VERSION ""

NS_ :

BS_:

BU_: WCM4 WCM3 WCM2 WCM VPM VLM VKM VICM VECM VDM VCU_RTOS_ETH VCU_ENTRY_ETH VCU_AGVM_ETH VCU UVM UPM TIM TEST_TOOL_1 TCP_ETH TCP TCM TCCM SRR_SRR_ETH SRR_SRR SRR_SLR_ETH SRR_SLR SRR_RR SRR_RF_ETH SRR_RF SRR_LR_CR SRR_LF_ETH SRR_LF SIB SDM SCL SBZA_R SBZA_L SBM SAM_RR SAM_RF SAM_LR SAM_LF SAM_BH SADS RadioLow_ETH RadioLow RSI_RTOS_ETH RSI RDCM PTM PLCM PFCM PDR_ETH PDR PCM PA ODS2 ODS NVM MTCM_R MTCM_L MSM_RR MSM_P MSM_LR MSM_D MSB2 MSB1 MRCM_R MRCM_L MFC LRR_RR_ETH LRR_LR_ETH LRR_CF_ETH LRR LRL_CF_ETH LIB_48V LIB1 IPC_INT IPC_GP IPC ICS_Info ICCM HVAC_FP_R HVAC_FP_F HUD_CAN HDLM FPI_RTOS_ETH FPI FOPM FCM_LC FCM EPSb EPS_1 EPSRAb EPSRAa EPS EOCM_HC_Superset EOCM_HCP2 EOCM ELM ECP_X1 ECP_S2 ECP_S ECP_MC ECP_H3 ECP_H2 ECP_H1 ECP_E ECM EBCM DMS DEFC DCM CSM_ETH CSM_AV CSM CGM_OTA_ETH CGM BSM_MH BSM_HEV BSM BCM ARS ARB APA AOS AMP ALC AHS AHL_AFL ADIMb ADIMa ACP2_MCU

BO_ 191 SRRSRRODP_BrstGrp_Prtctd_Conse02: 64 SRR_SRR
 SG_ SRRSRRODPB4P_POTk5IDAuth : 0|7@0+ (1,0) [0|127] "" EOCM_HCP2,EOCM_HC_Superset
 SG_ SRRSRRODPB4P_POTk5DynPrpAuth : 3|3@0+ (1,0) [0|4] "" EOCM_HCP2,EOCM_HC_Superset
 SG_ SRRSRRODPB4P_POTk5CnfdStsAuth : 5|2@0+ (1,0) [0|3] "" EOCM_HCP2,EOCM_HC_Superset
 SG_ SRRSRRODPB4P_BrstID : 7|2@0+ (1,0) [0|3] "" EOCM_HCP2,EOCM_HC_Superset
 SG_ SRRSRRODPB4P_POTk5InPthPotAuth : 9|6@0+ (2,0) [0|126] "%" EOCM_HCP2,EOCM_HC_Superset
 SG_ SRRSRRODPB4P_POTk5PoILAAuth : 17|9@0- (0.125,0) [-32|31.875] "m/s^2" EOCM_HCP2,EOCM_HC_Superset
 SG_ SRRSRRODPB4P_POTk5MStsAuth : 19|2@0+ (1,0) [0|3] "" EOCM_HCP2,EOCM_HC_Superset
 SG_ SRRSRRODPB4P_POTk5PoILgAAuth : 24|9@0- (0.125,0) [-32|31.875] "m/s^2" EOCM_HCP2,EOCM_HC_Superset
 SG_ SRRSRRODPB4P_POTk5PoILgPsAuth : 47|11@0- (0.125,0) [-128|127.875] "m" EOCM_HCP2,EOCM_HC_Superset
 SG_ SRRSRRODPB4P_POTk5PoILgVAuth : 52|10@0- (0.125,0) [-64|63.875] "m/s" EOCM_HCP2,EOCM_HC_Superset
 SG_ SRRSRRODPB4P_POTk5PoILPsAuth : 58|10@0- (0.125,0) [-64|63.875] "m" EOCM_HCP2,EOCM_HC_Superset
 SG_ SRRSRRODPB4P_POTk5PoILVAuth : 64|9@0- (0.125,0) [-32|31.875] "m/s" EOCM_HCP2,EOCM_HC_Superset
 SG_ SRRSRRODPB4P_VOTk10CICOPotAuth : 83|6@0+ (2,0) [0|126] "%" EOCM_HCP2,EOCM_HC_Superset
 SG_ SRRSRRODPB4P_POTk5TypCnfdAuth : 85|2@0+ (1,0) [0|3] "" EOCM_HCP2,EOCM_HC_Superset
 SG_ SRRSRRODPB4P_POTk5TypAuth : 87|2@0+ (1,0) [0|2] "" EOCM_HCP2,EOCM_HC_Superset
 SG_ SRRSRRODPB4P_VOTk10DynPrpStAuth : 88|1@0+ (1,0) [0|1] "" EOCM_HCP2,EOCM_HC_Superset
 SG_ SRRSRRODPB4P_VOTk10DynPrpAuth : 91|3@0+ (1,0) [0|4] "" EOCM_HCP2,EOCM_HC_Superset
 SG_ SRRSRRODPB4P_VOTk10CnfdStsAuth : 93|2@0+ (1,0) [0|3] "" EOCM_HCP2,EOCM_HC_Superset
 SG_ SRRSRRODPB4P_VOTk10MStsAuth : 96|2@0+ (1,0) [0|3] "" EOCM_HCP2,EOCM_HC_Superset
 SG_ SRRSRRODPB4P_VOTk10IDAuth : 103|7@0+ (1,0) [0|127] "" EOCM_HCP2,EOCM_HC_Superset
 SG_ SRRSRRODPB4P_VOTk10PoILAAuth : 110|9@0- (0.125,0) [-32|31.875] "m/s^2" EOCM_HCP2,EOCM_HC_Superset
 SG_ SRRSRRODPB4P_VOTk10PoILgAAuth : 117|9@0- (0.125,0) [-32|31.875] "m/s^2" EOCM_HCP2,EOCM_HC_Superset
 SG_ SRRSRRODPB4P_VOTk10PoILgPsAuth : 124|11@0- (0.125,0) [-128|127.875] "m" EOCM_HCP2,EOCM_HC_Superset
 SG_ SRRSRRODPB4P_VOTk10PoILgPsCAuth : 129|16@0+ (0.01,0) [0|655.35] "m^2" EOCM_HCP2,EOCM_HC_Superset
 SG_ SRRSRRODPB4P_VOTk10PoILgthAuth : 145|8@0+ (0.125,0) [0|31.875] "m" EOCM_HCP2,EOCM_HC_Superset
 SG_ SRRSRRODPB4P_VOTk10PoILgVAuth : 153|11@0- (0.125,0) [-128|127.875] "m/s" EOCM_HCP2,EOCM_HC_Superset
 SG_ SRRSRRODPB4P_VOTk10PoILgVCAuth : 174|10@0+ (0.125,0) [0|127.875] "(m/s)^2" EOCM_HCP2,EOCM_HC_Superset
 SG_ SRRSRRODPB4P_VOTk10PoILPsAuth : 180|10@0- (0.125,0) [-64|63.875] "m" EOCM_HCP2,EOCM_HC_Superset
 SG_ SRRSRRODPB4P_VOTk10PoILPsCAuth : 186|14@0+ (0.01,0) [0|163.83] "m^2" EOCM_HCP2,EOCM_HC_Superset
 SG_ SRRSRRODPB4P_VOTk10PoILVAuth : 204|9@0- (0.125,0) [-32|31.875] "m/s" EOCM_HCP2,EOCM_HC_Superset
 SG_ SRRSRRODPB4P_VOTk10PoILVCAuth : 211|10@0+ (0.125,0) [0|127.875] "(m/s)^2" EOCM_HCP2,EOCM_HC_Superset
 SG_ SRRSRRODPB4P_VOTk10TypCnfdAuth : 217|2@0+ (1,0) [0|3] "" EOCM_HCP2,EOCM_HC_Superset
 SG_ SRRSRRODPB4P_VOTk8CnfdStsAuth : 225|2@0+ (1,0) [0|3] "" EOCM_HCP2,EOCM_HC_Superset
 SG_ SRRSRRODPB4P_VOTk8CICOPotAuth : 231|6@0+ (2,0) [0|126] "%" EOCM_HCP2,EOCM_HC_Superset
 SG_ SRRSRRODPB4P_VOTk8IDAuth : 235|7@0+ (1,0) [0|127] "" EOCM_HCP2,EOCM_HC_Superset
 SG_ SRRSRRODPB4P_VOTk8DynPrpStsAuth : 236|1@0+ (1,0) [0|1] "" EOCM_HCP2,EOCM_HC_Superset
 SG_ SRRSRRODPB4P_VOTk8DynPrpAuth : 239|3@0+ (1,0) [0|4] "" EOCM_HCP2,EOCM_HC_Superset
 SG_ SRRSRRODPB4P_VOTk8PoILAAuth : 242|9@0- (0.125,0) [-32|31.875] "m/s^2" EOCM_HCP2,EOCM_HC_Superset
 SG_ SRRSRRODPB4P_VOTk8MStsAuth : 244|2@0+ (1,0) [0|3] "" EOCM_HCP2,EOCM_HC_Superset
 SG_ SRRSRRODPB4P_VOTk8PoILgAAuth : 249|9@0- (0.125,0) [-32|31.875] "m/s^2" EOCM_HCP2,EOCM_HC_Superset
 SG_ SRRSRRODPB4P_VOTk8PoILgPsAuth : 256|11@0- (0.125,0) [-128|127.875] "m" EOCM_HCP2,EOCM_HC_Superset
 SG_ SRRSRRODPB4P_VOTk8PoILgPsCAuth : 277|16@0+ (0.01,0) [0|655.35] "m^2" EOCM_HCP2,EOCM_HC_Superset
 SG_ SRRSRRODPB4P_VOTk8PoILgVAuth : 293|11@0- (0.125,0) [-128|127.875] "m/s" EOCM_HCP2,EOCM_HC_Superset
 SG_ SRRSRRODPB4P_VOTk8PoILgVCAuth : 298|10@0+ (0.125,0) [0|127.875] "(m/s)^2" EOCM_HCP2,EOCM_HC_Superset
 SG_ SRRSRRODPB4P_VOTk8PoILPsAuth : 304|10@0- (0.125,0) [-64|63.875] "m" EOCM_HCP2,EOCM_HC_Superset
 SG_ SRRSRRODPB4P_VOTk8PoILPsCAuth : 326|14@0+ (0.01,0) [0|163.83] "m^2" EOCM_HCP2,EOCM_HC_Superset
 SG_ SRRSRRODPB4P_VOTk8PoILVAuth : 328|9@0- (0.125,0) [-32|31.875] "m/s" EOCM_HCP2,EOCM_HC_Superset
 SG_ SRRSRRODPB4P_VOTk8PoILVCAuth : 351|10@0+ (0.125,0) [0|127.875] "(m/s)^2" EOCM_HCP2,EOCM_HC_Superset
 SG_ SRRSRRODPB4P_VOTk9CICOPotAuth : 355|6@0+ (2,0) [0|126] "%" EOCM_HCP2,EOCM_HC_Superset
 SG_ SRRSRRODPB4P_VOTk8TypCnfdAuth : 357|2@0+ (1,0) [0|3] "" EOCM_HCP2,EOCM_HC_Superset
 SG_ SRRSRRODPB4P_VOTk9DynPrpStsAuth : 360|1@0+ (1,0) [0|1] "" EOCM_HCP2,EOCM_HC_Superset
 SG_ SRRSRRODPB4P_VOTk9DynPrpAuth : 363|3@0+ (1,0) [0|4] "" EOCM_HCP2,EOCM_HC_Superset
 SG_ SRRSRRODPB4P_VOTk9CnfdStsAuth : 365|2@0+ (1,0) [0|3] "" EOCM_HCP2,EOCM_HC_Superset
 SG_ SRRSRRODPB4P_VOTk9MStsAuth : 368|2@0+ (1,0) [0|3] "" EOCM_HCP2,EOCM_HC_Superset
 SG_ SRRSRRODPB4P_VOTk9IDAuth : 375|7@0+ (1,0) [0|127] "" EOCM_HCP2,EOCM_HC_Superset
 SG_ SRRSRRODPB4P_VOTk9PoILAAuth : 382|9@0- (0.125,0) [-32|31.875] "m/s^2" EOCM_HCP2,EOCM_HC_Superset
 SG_ SRRSRRODPB4P_VOTk9PoILgAAuth : 389|9@0- (0.125,0) [-32|31.875] "m/s^2" EOCM_HCP2,EOCM_HC_Superset
 SG_ SRRSRRODPB4P_VOTk9PoILgPsAuth : 396|11@0- (0.125,0) [-128|127.875] "m" EOCM_HCP2,EOCM_HC_Superset
 SG_ SRRSRRODPB4P_VOTk9PoILgPsCAuth : 401|16@0+ (0.01,0) [0|655.35] "m^2" EOCM_HCP2,EOCM_HC_Superset
 SG_ SRRSRRODPB4P_VOTk9PoILgthAuth : 417|8@0+ (0.125,0) [0|31.875] "m" EOCM_HCP2,EOCM_HC_Superset
 SG_ SRRSRRODPB4P_VOTk9PoILgVAuth : 425|11@0- (0.125,0) [-128|127.875] "m/s" EOCM_HCP2,EOCM_HC_Superset
 SG_ SRRSRRODPB4P_VOTk9PoILgVCAuth : 446|10@0+ (0.125,0) [0|127.875] "(m/s)^2" EOCM_HCP2,EOCM_HC_Superset
 SG_ SRRSRRODPB4P_VOTk9PoILPsAuth : 452|10@0- (0.125,0) [-64|63.875] "m" EOCM_HCP2,EOCM_HC_Superset
 SG_ SRRSRRODPB4P_VOTk9PoILPsCAuth : 458|14@0+ (0.01,0) [0|163.83] "m^2" EOCM_HCP2,EOCM_HC_Superset
 SG_ SRRSRRODPB4P_VOTk9PoILVAuth : 476|9@0- (0.125,0) [-32|31.875] "m/s" EOCM_HCP2,EOCM_HC_Superset
 SG_ SRRSRRODPB4P_VOTk9PoILVCAuth : 483|10@0+ (0.125,0) [0|127.875] "(m/s)^2" EOCM_HCP2,EOCM_HC_Superset
 SG_ SRRSRRODPB4P_VOTk9TypCnfdAuth : 489|2@0+ (1,0) [0|3] "" EOCM_HCP2,EOCM_HC_Superset
 SG_ SRRSRRODPB4P_Filler : 503|16@0+ (1,0) [0|65535] "" EOCM_HCP2,EOCM_HC_Superset

BO_ 190 SRRSRRODP_BrstGrp_Prtctd_Conse03: 64 SRR_SRR
 SG_ SRRSRRODPB5P_IOTk10IDAuth : 1|7@0+ (1,0) [0|127] "" EOCM_HCP2,EOCM_HC_Superset
 SG_ SRRSRRODPB5P_IOTk10ElvtnAuth : 3|2@0+ (1,0) [0|3] "" EOCM_HCP2,EOCM_HC_Superset
 SG_ SRRSRRODPB5P_IOTk10CnfdStsAuth : 5|2@0+ (1,0) [0|3] "" EOCM_HCP2,EOCM_HC_Superset
 SG_ SRRSRRODPB5P_BrstID : 7|2@0+ (1,0) [0|3] "" EOCM_HCP2,EOCM_HC_Superset
 SG_ SRRSRRODPB5P_IOTk10PolLgPsAuth : 8|11@0- (0.125,0) [-128|127.875] "m" EOCM_HCP2,EOCM_HC_Superset
 SG_ SRRSRRODPB5P_IOTk10MStsAuth : 10|2@0+ (1,0) [0|3] "" EOCM_HCP2,EOCM_HC_Superset
 SG_ SRRSRRODPB5P_IOTk1CnfdStsAuth : 24|2@0+ (1,0) [0|3] "" EOCM_HCP2,EOCM_HC_Superset
 SG_ SRRSRRODPB5P_IOTk10TypCnfdAuth : 26|2@0+ (1,0) [0|3] "" EOCM_HCP2,EOCM_HC_Superset
 SG_ SRRSRRODPB5P_IOTk10TypAuth : 29|3@0+ (1,0) [0|5] "" EOCM_HCP2,EOCM_HC_Superset
 SG_ SRRSRRODPB5P_IOTk1IDAuth : 36|7@0+ (1,0) [0|127] "" EOCM_HCP2,EOCM_HC_Superset
 SG_ SRRSRRODPB5P_IOTk1ElvtnAuth : 38|2@0+ (1,0) [0|3] "" EOCM_HCP2,EOCM_HC_Superset
 SG_ SRRSRRODPB5P_IOTk1PoILgPsAuth : 43|11@0- (0.125,0) [-128|127.875] "m" EOCM_HCP2,EOCM_HC_Superset
 SG_ SRRSRRODPB5P_IOTk1MStsAuth : 45|2@0+ (1,0) [0|3] "" EOCM_HCP2,EOCM_HC_Superset
 SG_ SRRSRRODPB5P_IOTk1TypAuth : 48|3@0+ (1,0) [0|5] "" EOCM_HCP2,EOCM_HC_Superset
 SG_ SRRSRRODPB5P_IOTk2ElvtnAuth : 57|2@0+ (1,0) [0|3] "" EOCM_HCP2,EOCM_HC_Superset
 SG_ SRRSRRODPB5P_IOTk2CnfdStsAuth : 59|2@0+ (1,0) [0|3] "" EOCM_HCP2,EOCM_HC_Superset
 SG_ SRRSRRODPB5P_IOTk1TypCnfdAuth : 61|2@0+ (1,0) [0|3] "" EOCM_HCP2,EOCM_HC_Superset
 SG_ SRRSRRODPB5P_IOTk2MStsAuth : 64|2@0+ (1,0) [0|3] "" EOCM_HCP2,EOCM_HC_Superset
 SG_ SRRSRRODPB5P_IOTk2IDAuth : 71|7@0+ (1,0) [0|127] "" EOCM_HCP2,EOCM_HC_Superset
 SG_ SRRSRRODPB5P_IOTk2PolLgPsAuth : 78|11@0- (0.125,0) [-128|127.875] "m" EOCM_HCP2,EOCM_HC_Superset
 SG_ SRRSRRODPB5P_IOTk2TypCnfdAuth : 80|2@0+ (1,0) [0|3] "" EOCM_HCP2,EOCM_HC_Superset
 SG_ SRRSRRODPB5P_IOTk2TypAuth : 83|3@0+ (1,0) [0|5] "" EOCM_HCP2,EOCM_HC_Superset
 SG_ SRRSRRODPB5P_IOTk3IDAuth : 90|7@0+ (1,0) [0|127] "" EOCM_HCP2,EOCM_HC_Superset
 SG_ SRRSRRODPB5P_IOTk3ElvtnAuth : 92|2@0+ (1,0) [0|3] "" EOCM_HCP2,EOCM_HC_Superset
 SG_ SRRSRRODPB5P_IOTk3CnfdStsAuth : 94|2@0+ (1,0) [0|3] "" EOCM_HCP2,EOCM_HC_Superset
 SG_ SRRSRRODPB5P_IOTk3PolLgPsAuth : 97|11@0- (0.125,0) [-128|127.875] "m" EOCM_HCP2,EOCM_HC_Superset
 SG_ SRRSRRODPB5P_IOTk3MStsAuth : 99|2@0+ (1,0) [0|3] "" EOCM_HCP2,EOCM_HC_Superset
 SG_ SRRSRRODPB5P_IOTk4CnfdStsAuth : 113|2@0+ (1,0) [0|3] "" EOCM_HCP2,EOCM_HC_Superset
 SG_ SRRSRRODPB5P_IOTk3TypCnfdAuth : 115|2@0+ (1,0) [0|3] "" EOCM_HCP2,EOCM_HC_Superset
 SG_ SRRSRRODPB5P_IOTk3TypAuth : 118|3@0+ (1,0) [0|5] "" EOCM_HCP2,EOCM_HC_Superset
 SG_ SRRSRRODPB5P_IOTk4IDAuth : 125|7@0+ (1,0) [0|127] "" EOCM_HCP2,EOCM_HC_Superset
 SG_ SRRSRRODPB5P_IOTk4ElvtnAuth : 127|2@0+ (1,0) [0|3] "" EOCM_HCP2,EOCM_HC_Superset
 SG_ SRRSRRODPB5P_IOTk4PolLgPsAuth : 132|11@0- (0.125,0) [-128|127.875] "m" EOCM_HCP2,EOCM_HC_Superset
 SG_ SRRSRRODPB5P_IOTk4MStsAuth : 134|2@0+ (1,0) [0|3] "" EOCM_HCP2,EOCM_HC_Superset
 SG_ SRRSRRODPB5P_IOTk4TypAuth : 137|3@0+ (1,0) [0|5] "" EOCM_HCP2,EOCM_HC_Superset
 SG_ SRRSRRODPB5P_IOTk5IDAuth : 144|7@0+ (1,0) [0|127] "" EOCM_HCP2,EOCM_HC_Superset
 SG_ SRRSRRODPB5P_IOTk5ElvtnAuth : 146|2@0+ (1,0) [0|3] "" EOCM_HCP2,EOCM_HC_Superset
 SG_ SRRSRRODPB5P_IOTk5CnfdStsAuth : 148|2@0+ (1,0) [0|3] "" EOCM_HCP2,EOCM_HC_Superset
 SG_ SRRSRRODPB5P_IOTk4TypCnfdAuth : 150|2@0+ (1,0) [0|3] "" EOCM_HCP2,EOCM_HC_Superset
 SG_ SRRSRRODPB5P_IOTk5MStsAuth : 153|2@0+ (1,0) [0|3] "" EOCM_HCP2,EOCM_HC_Superset
 SG_ SRRSRRODPB5P_IOTk5PolLgPsAuth : 167|11@0- (0.125,0) [-128|127.875] "m" EOCM_HCP2,EOCM_HC_Superset
 SG_ SRRSRRODPB5P_IOTk5TypCnfdAuth : 169|2@0+ (1,0) [0|3] "" EOCM_HCP2,EOCM_HC_Superset
 SG_ SRRSRRODPB5P_IOTk5TypAuth : 172|3@0+ (1,0) [0|5] "" EOCM_HCP2,EOCM_HC_Superset
 SG_ SRRSRRODPB5P_IOTk6IDAuth : 179|7@0+ (1,0) [0|127] "" EOCM_HCP2,EOCM_HC_Superset
 SG_ SRRSRRODPB5P_IOTk6ElvtnAuth : 181|2@0+ (1,0) [0|3] "" EOCM_HCP2,EOCM_HC_Superset
 SG_ SRRSRRODPB5P_IOTk6CnfdStsAuth : 183|2@0+ (1,0) [0|3] "" EOCM_HCP2,EOCM_HC_Superset
 SG_ SRRSRRODPB5P_IOTk6PolLgPsAuth : 186|11@0- (0.125,0) [-128|127.875] "m" EOCM_HCP2,EOCM_HC_Superset
 SG_ SRRSRRODPB5P_IOTk6MStsAuth : 188|2@0+ (1,0) [0|3] "" EOCM_HCP2,EOCM_HC_Superset
 SG_ SRRSRRODPB5P_IOTk7ElvtnAuth : 200|2@0+ (1,0) [0|3] "" EOCM_HCP2,EOCM_HC_Superset
 SG_ SRRSRRODPB5P_IOTk7CnfdStsAuth : 202|2@0+ (1,0) [0|3] "" EOCM_HCP2,EOCM_HC_Superset
 SG_ SRRSRRODPB5P_IOTk6TypCnfdAuth : 204|2@0+ (1,0) [0|3] "" EOCM_HCP2,EOCM_HC_Superset
 SG_ SRRSRRODPB5P_IOTk6TypAuth : 207|3@0+ (1,0) [0|5] "" EOCM_HCP2,EOCM_HC_Superset
 SG_ SRRSRRODPB5P_IOTk7IDAuth : 214|7@0+ (1,0) [0|127] "" EOCM_HCP2,EOCM_HC_Superset
 SG_ SRRSRRODPB5P_IOTk7PolLgPsAuth : 221|11@0- (0.125,0) [-128|127.875] "m" EOCM_HCP2,EOCM_HC_Superset
 SG_ SRRSRRODPB5P_IOTk7MStsAuth : 223|2@0+ (1,0) [0|3] "" EOCM_HCP2,EOCM_HC_Superset
 SG_ SRRSRRODPB5P_IOTk7TypAuth : 226|3@0+ (1,0) [0|5] "" EOCM_HCP2,EOCM_HC_Superset
 SG_ SRRSRRODPB5P_IOTk8IDAuth : 233|7@0+ (1,0) [0|127] "" EOCM_HCP2,EOCM_HC_Superset
 SG_ SRRSRRODPB5P_IOTk8ElvtnAuth : 235|2@0+ (1,0) [0|3] "" EOCM_HCP2,EOCM_HC_Superset
 SG_ SRRSRRODPB5P_IOTk8CnfdStsAuth : 237|2@0+ (1,0) [0|3] "" EOCM_HCP2,EOCM_HC_Superset
 SG_ SRRSRRODPB5P_IOTk7TypCnfdAuth : 239|2@0+ (1,0) [0|3] "" EOCM_HCP2,EOCM_HC_Superset
 SG_ SRRSRRODPB5P_IOTk8PolLgPsAuth : 240|11@0- (0.125,0) [-128|127.875] "m" EOCM_HCP2,EOCM_HC_Superset
 SG_ SRRSRRODPB5P_IOTk8MStsAuth : 242|2@0+ (1,0) [0|3] "" EOCM_HCP2,EOCM_HC_Superset
 SG_ SRRSRRODPB5P_IOTk9CnfdStsAuth : 256|2@0+ (1,0) [0|3] "" EOCM_HCP2,EOCM_HC_Superset
 SG_ SRRSRRODPB5P_IOTk8TypCnfdAuth : 258|2@0+ (1,0) [0|3] "" EOCM_HCP2,EOCM_HC_Superset
 SG_ SRRSRRODPB5P_IOTk8TypAuth : 261|3@0+ (1,0) [0|5] "" EOCM_HCP2,EOCM_HC_Superset
 SG_ SRRSRRODPB5P_IOTk9IDAuth : 268|7@0+ (1,0) [0|127] "" EOCM_HCP2,EOCM_HC_Superset
 SG_ SRRSRRODPB5P_IOTk9ElvtnAuth : 270|2@0+ (1,0) [0|3] "" EOCM_HCP2,EOCM_HC_Superset
 SG_ SRRSRRODPB5P_IOTk9PolLgPsAuth : 275|11@0- (0.125,0) [-128|127.875] "m" EOCM_HCP2,EOCM_HC_Superset
 SG_ SRRSRRODPB5P_IOTk9MStsAuth : 277|2@0+ (1,0) [0|3] "" EOCM_HCP2,EOCM_HC_Superset
 SG_ SRRSRRODPB5P_IOTk9TypAuth : 280|3@0+ (1,0) [0|5] "" EOCM_HCP2,EOCM_HC_Superset
 SG_ SRRSRRODPB5P_VOTk9PoI2LgPsAuth : 291|11@0- (0.125,0) [-128|127.875] "m" EOCM_HCP2,EOCM_HC_Superset
 SG_ SRRSRRODPB5P_IOTk9TypCnfdAuth : 293|2@0+ (1,0) [0|3] "" EOCM_HCP2,EOCM_HC_Superset
 SG_ SRRSRRODPB5P_VOTk9PoI2LPsAuth : 296|10@0- (0.125,0) [-64|63.875] "m" EOCM_HCP2,EOCM_HC_Superset
 SG_ SRRSRRODPB5P_VOTk1PoI2LgPsAuth : 318|11@0- (0.125,0) [-128|127.875] "m" EOCM_HCP2,EOCM_HC_Superset
 SG_ SRRSRRODPB5P_VOTk1PoI2LPsAuth : 323|10@0- (0.125,0) [-64|63.875] "m" EOCM_HCP2,EOCM_HC_Superset
 SG_ SRRSRRODPB5P_VOTk2PoI2LgPsAuth : 329|11@0- (0.125,0) [-128|127.875] "m" EOCM_HCP2,EOCM_HC_Superset
 SG_ SRRSRRODPB5P_VOTk2PoI2LPsAuth : 350|10@0- (0.125,0) [-64|63.875] "m" EOCM_HCP2,EOCM_HC_Superset
 SG_ SRRSRRODPB5P_VOTk3PoI2LgPsAuth : 356|11@0- (0.125,0) [-128|127.875] "m" EOCM_HCP2,EOCM_HC_Superset
 SG_ SRRSRRODPB5P_VOTk3PoI2LPsAuth : 361|10@0- (0.125,0) [-64|63.875] "m" EOCM_HCP2,EOCM_HC_Superset
 SG_ SRRSRRODPB5P_VOTk4PoI2LgPsAuth : 383|11@0- (0.125,0) [-128|127.875] "m" EOCM_HCP2,EOCM_HC_Superset
 SG_ SRRSRRODPB5P_VOTk4PoI2LPsAuth : 388|10@0- (0.125,0) [-64|63.875] "m" EOCM_HCP2,EOCM_HC_Superset
 SG_ SRRSRRODPB5P_VOTk5Pol2LgPsAuth : 394|11@0- (0.125,0) [-128|127.875] "m" EOCM_HCP2,EOCM_HC_Superset
 SG_ SRRSRRODPB5P_VOTk5Pol2LPsAuth : 415|10@0- (0.125,0) [-64|63.875] "m" EOCM_HCP2,EOCM_HC_Superset
 SG_ SRRSRRODPB5P_VOTk6PoI2LgPsAuth : 421|11@0- (0.125,0) [-128|127.875] "m" EOCM_HCP2,EOCM_HC_Superset
 SG_ SRRSRRODPB5P_VOTk6PoI2LPsAuth : 426|10@0- (0.125,0) [-64|63.875] "m" EOCM_HCP2,EOCM_HC_Superset
 SG_ SRRSRRODPB5P_VOTk7PoI2LgPsAuth : 432|11@0- (0.125,0) [-128|127.875] "m" EOCM_HCP2,EOCM_HC_Superset
 SG_ SRRSRRODPB5P_VOTk7PoI2LPsAuth : 453|10@0- (0.125,0) [-64|63.875] "m" EOCM_HCP2,EOCM_HC_Superset
 SG_ SRRSRRODPB5P_VOTk8PoI2LgPsAuth : 459|11@0- (0.125,0) [-128|127.875] "m" EOCM_HCP2,EOCM_HC_Superset
 SG_ SRRSRRODPB5P_VOTk8PoI2LPsAuth : 464|10@0- (0.125,0) [-64|63.875] "m" EOCM_HCP2,EOCM_HC_Superset
 SG_ SRRSRRODPB5P_VOTk10PoI2LgPsAuth : 486|11@0- (0.125,0) [-128|127.875] "m" EOCM_HCP2,EOCM_HC_Superset
 SG_ SRRSRRODPB5P_VOTk10PoI2LPsAuth : 491|10@0- (0.125,0) [-64|63.875] "m" EOCM_HCP2,EOCM_HC_Superset
 SG_ SRRSRRODPB5P_Filler : 497|10@0+ (1,0) [0|1023] "" EOCM_HCP2,EOCM_HC_Superset

BO_ 193 SRRSRRODP_BrstGrp_Prtctd_First_F: 48 SRR_SRR
 SG_ SRRSRRODPB1P_MAC : 7|32@0+ (1,0) [0|4.29497e+009] "" EOCM_HCP2,EOCM_HC_Superset
 SG_ SRRSRRODPB1P_FCnt : 39|5@0+ (1,0) [0|31] "" EOCM_HCP2,EOCM_HC_Superset
 SG_ SRRSRRODPB1P_AcqTmStmAuth : 45|11@0+ (1,0) [0|2047] "ms" EOCM_HCP2,EOCM_HC_Superset
 SG_ SRRSRRODPB1P_BrstID : 47|2@0+ (1,0) [0|3] "" EOCM_HCP2,EOCM_HC_Superset
 SG_ SRRSRRODPB1P_CnstrArDtnCnfdAuth : 49|2@0+ (1,0) [0|3] "" EOCM_HCP2,EOCM_HC_Superset
 SG_ SRRSRRODPB1P_AcqTmStmAuth_Inv : 50|1@0+ (1,0) [0|1] "" EOCM_HCP2,EOCM_HC_Superset
 SG_ SRRSRRODPB1P_POTk1DynPrpAuth : 57|3@0+ (1,0) [0|4] "" EOCM_HCP2,EOCM_HC_Superset
 SG_ SRRSRRODPB1P_POTk1CnfdStsAuth : 59|2@0+ (1,0) [0|3] "" EOCM_HCP2,EOCM_HC_Superset
 SG_ SRRSRRODPB1P_MdCmdStsAuth : 61|2@0+ (1,0) [0|2] "" EOCM_HCP2,EOCM_HC_Superset
 SG_ SRRSRRODPB1P_CnstrArDtnStsAuth : 63|2@0+ (1,0) [0|2] "" EOCM_HCP2,EOCM_HC_Superset
 SG_ SRRSRRODPB1P_POTk1IDAuth : 70|7@0+ (1,0) [0|127] "" EOCM_HCP2,EOCM_HC_Superset
 SG_ SRRSRRODPB1P_POTk1MStsAuth : 73|2@0+ (1,0) [0|3] "" EOCM_HCP2,EOCM_HC_Superset
 SG_ SRRSRRODPB1P_POTk1InPthPotAuth : 79|6@0+ (2,0) [0|126] "%" EOCM_HCP2,EOCM_HC_Superset
 SG_ SRRSRRODPB1P_POTk1PoILAAuth : 87|9@0- (0.125,0) [-32|31.875] "m/s^2" EOCM_HCP2,EOCM_HC_Superset
 SG_ SRRSRRODPB1P_POTk1PoILgAAuth : 94|9@0- (0.125,0) [-32|31.875] "m/s^2" EOCM_HCP2,EOCM_HC_Superset
 SG_ SRRSRRODPB1P_POTk1PoILgPsAuth : 101|11@0- (0.125,0) [-128|127.875] "m" EOCM_HCP2,EOCM_HC_Superset
 SG_ SRRSRRODPB1P_POTk1PoILgVAuth : 106|10@0- (0.125,0) [-64|63.875] "m/s" EOCM_HCP2,EOCM_HC_Superset
 SG_ SRRSRRODPB1P_POTk1PoILPsAuth : 112|10@0- (0.125,0) [-64|63.875] "m" EOCM_HCP2,EOCM_HC_Superset
 SG_ SRRSRRODPB1P_POTk1PoILVAuth : 134|9@0- (0.125,0) [-32|31.875] "m/s" EOCM_HCP2,EOCM_HC_Superset
 SG_ SRRSRRODPB1P_POTk2CnfdStsAuth : 137|2@0+ (1,0) [0|3] "" EOCM_HCP2,EOCM_HC_Superset
 SG_ SRRSRRODPB1P_POTk1TypCnfdAuth : 139|2@0+ (1,0) [0|3] "" EOCM_HCP2,EOCM_HC_Superset
 SG_ SRRSRRODPB1P_POTk1TypAuth : 141|2@0+ (1,0) [0|2] "" EOCM_HCP2,EOCM_HC_Superset
 SG_ SRRSRRODPB1P_POTk2IDAuth : 148|7@0+ (1,0) [0|127] "" EOCM_HCP2,EOCM_HC_Superset
 SG_ SRRSRRODPB1P_POTk2DynPrpAuth : 151|3@0+ (1,0) [0|4] "" EOCM_HCP2,EOCM_HC_Superset
 SG_ SRRSRRODPB1P_POTk2InPthPotAuth : 157|6@0+ (2,0) [0|126] "%" EOCM_HCP2,EOCM_HC_Superset
 SG_ SRRSRRODPB1P_POTk2PoILAAuth : 165|9@0- (0.125,0) [-32|31.875] "m/s^2" EOCM_HCP2,EOCM_HC_Superset
 SG_ SRRSRRODPB1P_POTk2MStsAuth : 167|2@0+ (1,0) [0|3] "" EOCM_HCP2,EOCM_HC_Superset
 SG_ SRRSRRODPB1P_POTk2PoILgAAuth : 172|9@0- (0.125,0) [-32|31.875] "m/s^2" EOCM_HCP2,EOCM_HC_Superset
 SG_ SRRSRRODPB1P_POTk2PoILgPsAuth : 179|11@0- (0.125,0) [-128|127.875] "m" EOCM_HCP2,EOCM_HC_Superset
 SG_ SRRSRRODPB1P_POTk2PoILgVAuth : 184|10@0- (0.125,0) [-64|63.875] "m/s" EOCM_HCP2,EOCM_HC_Superset
 SG_ SRRSRRODPB1P_POTk2PoILPsAuth : 206|10@0- (0.125,0) [-64|63.875] "m" EOCM_HCP2,EOCM_HC_Superset
 SG_ SRRSRRODPB1P_POTk2PoILVAuth : 212|9@0- (0.125,0) [-32|31.875] "m/s" EOCM_HCP2,EOCM_HC_Superset
 SG_ SRRSRRODPB1P_POTk2TypCnfdAuth : 217|2@0+ (1,0) [0|3] "" EOCM_HCP2,EOCM_HC_Superset
 SG_ SRRSRRODPB1P_POTk2TypAuth : 219|2@0+ (1,0) [0|2] "" EOCM_HCP2,EOCM_HC_Superset
 SG_ SRRSRRODPB1P_SnsrUnvAuth : 224|1@0+ (1,0) [0|1] "" EOCM_HCP2,EOCM_HC_Superset
 SG_ SRRSRRODPB1P_SnsrBlckdAuth : 225|1@0+ (1,0) [0|1] "" EOCM_HCP2,EOCM_HC_Superset
 SG_ SRRSRRODPB1P_ServRqrdAuth : 226|1@0+ (1,0) [0|1] "" EOCM_HCP2,EOCM_HC_Superset
 SG_ SRRSRRODPB1P_RdTypCnfdAuth : 228|2@0+ (1,0) [0|3] "" EOCM_HCP2,EOCM_HC_Superset
 SG_ SRRSRRODPB1P_RdTypAuth : 231|3@0+ (1,0) [0|7] "" EOCM_HCP2,EOCM_HC_Superset
 SG_ SRRSRRODPB1P_VOTk1CICOPotAuth : 237|6@0+ (2,0) [0|126] "%" EOCM_HCP2,EOCM_HC_Superset
 SG_ SRRSRRODPB1P_SwpBndwdthStsAuth : 239|2@0+ (1,0) [0|3] "" EOCM_HCP2,EOCM_HC_Superset
 SG_ SRRSRRODPB1P_VOTk1IDAuth : 241|7@0+ (1,0) [0|127] "" EOCM_HCP2,EOCM_HC_Superset
 SG_ SRRSRRODPB1P_VOTk1DynPrpStsAuth : 242|1@0+ (1,0) [0|1] "" EOCM_HCP2,EOCM_HC_Superset
 SG_ SRRSRRODPB1P_VOTk1DynPrpAuth : 245|3@0+ (1,0) [0|4] "" EOCM_HCP2,EOCM_HC_Superset
 SG_ SRRSRRODPB1P_VOTk1CnfdStsAuth : 247|2@0+ (1,0) [0|3] "" EOCM_HCP2,EOCM_HC_Superset
 SG_ SRRSRRODPB1P_VOTk1PoILAAuth : 248|9@0- (0.125,0) [-32|31.875] "m/s^2" EOCM_HCP2,EOCM_HC_Superset
 SG_ SRRSRRODPB1P_VOTk1MStsAuth : 250|2@0+ (1,0) [0|3] "" EOCM_HCP2,EOCM_HC_Superset
 SG_ SRRSRRODPB1P_VOTk1PoILgAAuth : 271|9@0- (0.125,0) [-32|31.875] "m/s^2" EOCM_HCP2,EOCM_HC_Superset
 SG_ SRRSRRODPB1P_VOTk1PoILgPsAuth : 278|11@0- (0.125,0) [-128|127.875] "m" EOCM_HCP2,EOCM_HC_Superset
 SG_ SRRSRRODPB1P_VOTk1PoILgPsCAuth : 283|16@0+ (0.01,0) [0|655.35] "m^2" EOCM_HCP2,EOCM_HC_Superset
 SG_ SRRSRRODPB1P_VOTk1PoILgthAuth : 299|8@0+ (0.125,0) [0|31.875] "m" EOCM_HCP2,EOCM_HC_Superset
 SG_ SRRSRRODPB1P_VOTk1PoILgVAuth : 307|11@0- (0.125,0) [-128|127.875] "m/s" EOCM_HCP2,EOCM_HC_Superset
 SG_ SRRSRRODPB1P_VOTk1PoILgVCAuth : 312|10@0+ (0.125,0) [0|127.875] "(m/s)^2" EOCM_HCP2,EOCM_HC_Superset
 SG_ SRRSRRODPB1P_VOTk1PoILPsAuth : 334|10@0- (0.125,0) [-64|63.875] "m" EOCM_HCP2,EOCM_HC_Superset
 SG_ SRRSRRODPB1P_VOTk1PoILPsCAuth : 340|14@0+ (0.01,0) [0|163.83] "m^2" EOCM_HCP2,EOCM_HC_Superset
 SG_ SRRSRRODPB1P_VOTk1PoILVAuth : 358|9@0- (0.125,0) [-32|31.875] "m/s" EOCM_HCP2,EOCM_HC_Superset
 SG_ SRRSRRODPB1P_VOTk1PoILVCAuth : 365|10@0+ (0.125,0) [0|127.875] "(m/s)^2" EOCM_HCP2,EOCM_HC_Superset
 SG_ SRRSRRODPB1P_VOTk2PoILgthAuth : 369|8@0+ (0.125,0) [0|31.875] "m" EOCM_HCP2,EOCM_HC_Superset
 SG_ SRRSRRODPB1P_VOTk1TypCnfdAuth : 371|2@0+ (1,0) [0|3] "" EOCM_HCP2,EOCM_HC_Superset
 SG_ SRRSRRODPB1P_ARC : 377|2@0+ (1,0) [0|3] "" EOCM_HCP2,EOCM_HC_Superset

BO_ 522 SRRSRRODP_BrstGrp_Prtctd_Last_Fr: 48 SRR_SRR
 SG_ SRRSRRODPB6P_IOTk10PolLPsAuth : 5|10@0- (0.125,0) [-64|63.875] "m" EOCM_HCP2,EOCM_HC_Superset
 SG_ SRRSRRODPB6P_BrstID : 7|2@0+ (1,0) [0|3] "" EOCM_HCP2,EOCM_HC_Superset
 SG_ SRRSRRODPB6P_IOTk1PoILPsAuth : 11|10@0- (0.125,0) [-64|63.875] "m" EOCM_HCP2,EOCM_HC_Superset
 SG_ SRRSRRODPB6P_IOTk2PolLPsAuth : 17|10@0- (0.125,0) [-64|63.875] "m" EOCM_HCP2,EOCM_HC_Superset
 SG_ SRRSRRODPB6P_IOTk3PolLPsAuth : 39|10@0- (0.125,0) [-64|63.875] "m" EOCM_HCP2,EOCM_HC_Superset
 SG_ SRRSRRODPB6P_IOTk4PolLPsAuth : 45|10@0- (0.125,0) [-64|63.875] "m" EOCM_HCP2,EOCM_HC_Superset
 SG_ SRRSRRODPB6P_IOTk5PolLPsAuth : 51|10@0- (0.125,0) [-64|63.875] "m" EOCM_HCP2,EOCM_HC_Superset
 SG_ SRRSRRODPB6P_IOTk6PolLPsAuth : 57|10@0- (0.125,0) [-64|63.875] "m" EOCM_HCP2,EOCM_HC_Superset
 SG_ SRRSRRODPB6P_IOTk7PolLPsAuth : 79|10@0- (0.125,0) [-64|63.875] "m" EOCM_HCP2,EOCM_HC_Superset
 SG_ SRRSRRODPB6P_IOTk8PolLPsAuth : 85|10@0- (0.125,0) [-64|63.875] "m" EOCM_HCP2,EOCM_HC_Superset
 SG_ SRRSRRODPB6P_IOTk9PolLPsAuth : 91|10@0- (0.125,0) [-64|63.875] "m" EOCM_HCP2,EOCM_HC_Superset
 SG_ SRRSRRODPB6P_REOTk1CnfdStsAuth : 97|2@0+ (1,0) [0|3] "" EOCM_HCP2,EOCM_HC_Superset,SRR_SLR
 SG_ SRRSRRODPB6P_REOTk1CrvAuth : 111|16@0- (9.77e-07,0) [-0.0320143|0.0320134] "1/m" EOCM_HCP2,EOCM_HC_Superset,SRR_SLR
 SG_ SRRSRRODPB6P_REOTk1CrvDrvtAuth : 127|16@0- (3.73e-09,0) [-0.000122225|0.000122221] "1/m2" EOCM_HCP2,EOCM_HC_Superset,SRR_SLR
 SG_ SRRSRRODPB6P_REOTk1HdgAuth : 143|10@0- (0.000977,0) [-0.500224|0.499247] "rad" EOCM_HCP2,EOCM_HC_Superset,SRR_SLR
 SG_ SRRSRRODPB6P_REOTk1OfstAuth : 149|9@0- (0.125,0) [-32|31.875] "m" EOCM_HCP2,EOCM_HC_Superset,SRR_SLR
 SG_ SRRSRRODPB6P_REOTk1PsEndAuth : 156|11@0- (0.125,0) [-128|127.875] "m" EOCM_HCP2,EOCM_HC_Superset,SRR_SLR
 SG_ SRRSRRODPB6P_REOTk1PsStrtAuth : 161|11@0- (0.125,0) [-128|127.875] "m" EOCM_HCP2,EOCM_HC_Superset,SRR_SLR
 SG_ SRRSRRODPB6P_REOTk2CnfdStsAuth : 177|2@0+ (1,0) [0|3] "" EOCM_HCP2,EOCM_HC_Superset,SRR_SLR
 SG_ SRRSRRODPB6P_REOTk1TypCnfdAuth : 179|2@0+ (1,0) [0|3] "" EOCM_HCP2,EOCM_HC_Superset,SRR_SLR
 SG_ SRRSRRODPB6P_REOTk1TypAuth : 182|3@0+ (1,0) [0|5] "" EOCM_HCP2,EOCM_HC_Superset,SRR_SLR
 SG_ SRRSRRODPB6P_REOTk2CrvAuth : 191|16@0- (9.77e-07,0) [-0.0320143|0.0320134] "1/m" EOCM_HCP2,EOCM_HC_Superset,SRR_SLR
 SG_ SRRSRRODPB6P_REOTk2CrvDrvtAuth : 207|16@0- (3.73e-09,0) [-0.000122225|0.000122221] "1/m2" EOCM_HCP2,EOCM_HC_Superset,SRR_SLR
 SG_ SRRSRRODPB6P_REOTk2HdgAuth : 223|10@0- (0.000977,0) [-0.500224|0.499247] "rad" EOCM_HCP2,EOCM_HC_Superset,SRR_SLR
 SG_ SRRSRRODPB6P_REOTk2OfstAuth : 229|9@0- (0.125,0) [-32|31.875] "m" EOCM_HCP2,EOCM_HC_Superset,SRR_SLR
 SG_ SRRSRRODPB6P_REOTk2PsEndAuth : 236|11@0- (0.125,0) [-128|127.875] "m" EOCM_HCP2,EOCM_HC_Superset,SRR_SLR
 SG_ SRRSRRODPB6P_REOTk2PsStrtAuth : 241|11@0- (0.125,0) [-128|127.875] "m" EOCM_HCP2,EOCM_HC_Superset,SRR_SLR
 SG_ SRRSRRODPB6P_REOTk3CnfdStsAuth : 257|2@0+ (1,0) [0|3] "" EOCM_HCP2,EOCM_HC_Superset,SRR_SLR
 SG_ SRRSRRODPB6P_REOTk2TypCnfdAuth : 259|2@0+ (1,0) [0|3] "" EOCM_HCP2,EOCM_HC_Superset,SRR_SLR
 SG_ SRRSRRODPB6P_REOTk2TypAuth : 262|3@0+ (1,0) [0|5] "" EOCM_HCP2,EOCM_HC_Superset,SRR_SLR
 SG_ SRRSRRODPB6P_REOTk3CrvAuth : 271|16@0- (9.77e-07,0) [-0.0320143|0.0320134] "1/m" EOCM_HCP2,EOCM_HC_Superset,SRR_SLR
 SG_ SRRSRRODPB6P_REOTk3CrvDrvtAuth : 287|16@0- (3.73e-09,0) [-0.000122225|0.000122221] "1/m2" EOCM_HCP2,EOCM_HC_Superset,SRR_SLR
 SG_ SRRSRRODPB6P_REOTk3HdgAuth : 303|10@0- (0.000977,0) [-0.500224|0.499247] "rad" EOCM_HCP2,EOCM_HC_Superset,SRR_SLR
 SG_ SRRSRRODPB6P_REOTk3OfstAuth : 309|9@0- (0.125,0) [-32|31.875] "m" EOCM_HCP2,EOCM_HC_Superset,SRR_SLR
 SG_ SRRSRRODPB6P_REOTk3PsEndAuth : 316|11@0- (0.125,0) [-128|127.875] "m" EOCM_HCP2,EOCM_HC_Superset,SRR_SLR
 SG_ SRRSRRODPB6P_REOTk3PsStrtAuth : 321|11@0- (0.125,0) [-128|127.875] "m" EOCM_HCP2,EOCM_HC_Superset,SRR_SLR
 SG_ SRRSRRODPB6P_Filler : 337|32@0+ (1,0) [0|4.29497e+009] "" EOCM_HCP2,EOCM_HC_Superset
 SG_ SRRSRRODPB6P_REOTk3TypCnfdAuth : 339|2@0+ (1,0) [0|3] "" EOCM_HCP2,EOCM_HC_Superset,SRR_SLR
 SG_ SRRSRRODPB6P_REOTk3TypAuth : 342|3@0+ (1,0) [0|5] "" EOCM_HCP2,EOCM_HC_Superset,SRR_SLR
 SG_ SRRSRRODPB6P_FillerExtnd : 369|10@0+ (1,0) [0|1023] "" EOCM_HCP2,EOCM_HC_Superset

BO_ 2147745812 SRR_LF_CAN8_ClscCANHrtBtActv_PDU: 1 SRR_LF
 SG_ SRR_LF_CAN8_ClscCANHrtBtActv : 7|1@0+ (1,0) [0|1] "" CGM

BO_ 2147745813 SRR_LR_CR_CAN8_ClscCANHrtBtActv_: 1 SRR_LR_CR
 SG_ SRR_LR_CR_CAN8_ClscCANHrtBtActv : 7|1@0+ (1,0) [0|1] "" CGM

BO_ 2147745814 SRR_RF_CAN8_ClscCANHrtBtActv_PDU: 1 SRR_RF
 SG_ SRR_RF_CAN8_ClscCANHrtBtActv : 7|1@0+ (1,0) [0|1] "" CGM

BO_ 2147745815 SRR_RR_CAN8_ClscCANHrtBtActv_PDU: 1 SRR_RR
 SG_ SRR_RR_CAN8_ClscCANHrtBtActv : 7|1@0+ (1,0) [0|1] "" CGM

BO_ 2147745816 SRR_SLR_CAN8_ClscCANHrtBtActv_PD: 1 SRR_SLR
 SG_ SRR_SLR_CAN8_ClscCANHrtBtActv : 7|1@0+ (1,0) [0|1] "" CGM

BO_ 473 SRR_SLR_NM_PDU_On_CAN_8_Cluster: 8 SRR_SLR
 SG_ ISignal_SRR_SLR_CAN_8_Cluster : 23|48@0+ (1,0) [0|281474976710655] "" ACP2_MCU,CGM,EOCM,EOCM_HCP2,EOCM_HC_Superset,FCM_LC,HDLM,LRR,SRR_LF,SRR_LR_CR,SRR_RF,SRR_RR,SRR_SRR,UPM

BO_ 2147745817 SRR_SRR_CAN8_ClscCANHrtBtActv_PD: 1 SRR_SRR
 SG_ SRR_SRR_CAN8_ClscCANHrtBtActv : 7|1@0+ (1,0) [0|1] "" CGM

BO_ 1348 SpdLimVsnFsdSpd_PCSM_PDU: 8 ACP2_MCU
 SG_ SpdLimVsnFsdSpd_PCSM : 0|64@1+ (1,0) [0|1.84467e+019] "" EOCM,EOCM_HC_Superset

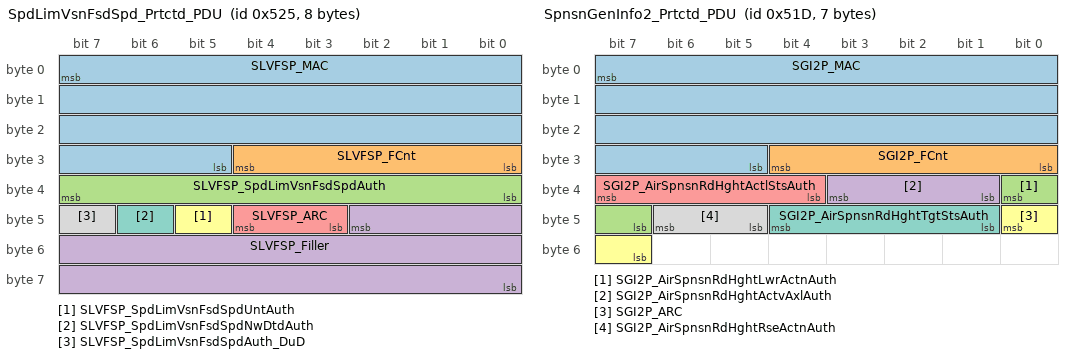
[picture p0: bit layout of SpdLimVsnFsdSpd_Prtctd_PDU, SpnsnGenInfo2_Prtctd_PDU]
BO_ 1317 SpdLimVsnFsdSpd_Prtctd_PDU: 8 ACP2_MCU
 SG_ SLVFSP_MAC : 7|27@0+ (1,0) [0|1.34218e+008] "" CGM,EOCM,EOCM_HC_Superset
 SG_ SLVFSP_FCnt : 28|5@0+ (1,0) [0|31] "" CGM,EOCM,EOCM_HC_Superset
 SG_ SLVFSP_SpdLimVsnFsdSpdAuth : 39|8@0+ (1,0) [0|255] "" CGM,EOCM,EOCM_HC_Superset
 SG_ SLVFSP_Filler : 42|19@0+ (1,0) [0|524287] "" EOCM,EOCM_HC_Superset
 SG_ SLVFSP_ARC : 44|2@0+ (1,0) [0|3] "" CGM,EOCM,EOCM_HC_Superset
 SG_ SLVFSP_SpdLimVsnFsdSpdUntAuth : 45|1@0+ (1,0) [0|1] "" CGM,EOCM,EOCM_HC_Superset
 SG_ SLVFSP_SpdLimVsnFsdSpdNwDtdAuth : 46|1@0+ (1,0) [0|1] "" CGM,EOCM,EOCM_HC_Superset
 SG_ SLVFSP_SpdLimVsnFsdSpdAuth_DuD : 47|1@0+ (1,0) [0|1] "" CGM,EOCM,EOCM_HC_Superset

BO_ 1378 SpnsnGenInfo2_PCSM_PDU: 8 CGM
 SG_ SpnsnGenInfo2_PCSM : 0|64@1+ (1,0) [0|1.84467e+019] "" ACP2_MCU,FCM_LC

BO_ 1309 SpnsnGenInfo2_Prtctd_PDU: 7 CGM
 SG_ SGI2P_MAC : 7|27@0+ (1,0) [0|1.34218e+008] "" ACP2_MCU,FCM_LC
 SG_ SGI2P_FCnt : 28|5@0+ (1,0) [0|31] "" ACP2_MCU,FCM_LC
 SG_ SGI2P_AirSpnsnRdHghtLwrActnAuth : 32|2@0+ (1,0) [0|3] "" ACP2_MCU,FCM_LC
 SG_ SGI2P_AirSpnsnRdHghtActvAxlAuth : 35|3@0+ (1,0) [0|4] "" ACP2_MCU,FCM_LC
 SG_ SGI2P_AirSpnsnRdHghtActlStsAuth : 39|4@0+ (1,0) [0|13] "" ACP2_MCU,FCM_LC
 SG_ SGI2P_ARC : 40|2@0+ (1,0) [0|3] "" ACP2_MCU,FCM_LC
 SG_ SGI2P_AirSpnsnRdHghtTgtStsAuth : 44|4@0+ (1,0) [0|13] "" ACP2_MCU,FCM_LC
 SG_ SGI2P_AirSpnsnRdHghtRseActnAuth : 46|2@0+ (1,0) [0|3] "" ACP2_MCU,FCM_LC

BO_ 636 SrlDat100_PCSM_PDU: 8 ACP2_MCU
 SG_ SrlDat100_PCSM : 0|64@1+ (1,0) [0|1.84467e+019] "" Vector__XXX

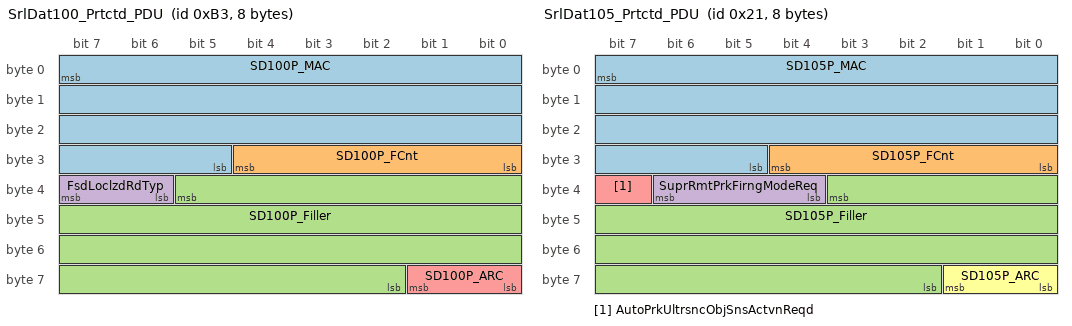
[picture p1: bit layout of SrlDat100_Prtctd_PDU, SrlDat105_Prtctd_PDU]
BO_ 179 SrlDat100_Prtctd_PDU: 8 ACP2_MCU
 SG_ SD100P_MAC : 7|27@0+ (1,0) [0|1.34218e+008] "" Vector__XXX
 SG_ SD100P_FCnt : 28|5@0+ (1,0) [0|31] "" Vector__XXX
 SG_ SD100P_Filler : 37|28@0+ (1,0) [0|2.68435e+008] "" Vector__XXX
 SG_ FsdLoclzdRdTyp : 39|2@0+ (1,0) [0|2] "" Vector__XXX
 SG_ SD100P_ARC : 57|2@0+ (1,0) [0|3] "" Vector__XXX

BO_ 884 SrlDat101_PCSM_PDU: 8 UPM
 SG_ SrlDat101_PCSM : 0|64@1+ (1,0) [0|1.84467e+019] "" ACP2_MCU,EOCM,EOCM_HC_Superset

BO_ 180 SrlDat101_Prtctd_PDU: 48 UPM
 SG_ SD101P_MAC : 7|32@0+ (1,0) [0|4.29497e+009] "" ACP2_MCU,EOCM,EOCM_HC_Superset
 SG_ SD101P_FCnt : 39|5@0+ (1,0) [0|31] "" ACP2_MCU,EOCM,EOCM_HC_Superset
 SG_ UODPFrtEchoAcqTmStm : 47|11@0+ (1,0) [0|2047] "ms" ACP2_MCU,EOCM,EOCM_HC_Superset
 SG_ UODPFrtSnsr1EchoDist1 : 51|11@0+ (0.25,0) [0|511.75] "cm" ACP2_MCU,EOCM,EOCM_HC_Superset
 SG_ UODPFrtEchoAcqTmStm_Inv : 52|1@0+ (1,0) [0|1] "" ACP2_MCU,EOCM,EOCM_HC_Superset
 SG_ UODPFrtSnsr1EchoDist2 : 56|11@0+ (0.25,0) [0|511.75] "cm" ACP2_MCU,EOCM,EOCM_HC_Superset
 SG_ UODPFrtSnsr1EchoDist3 : 77|11@0+ (0.25,0) [0|511.75] "cm" ACP2_MCU,EOCM,EOCM_HC_Superset
 SG_ UODPFrtSnsr1EchoQlty1 : 82|4@0+ (1,0) [0|15] "" ACP2_MCU,EOCM,EOCM_HC_Superset
 SG_ UODPFrtSnsr1EchoQlty3 : 90|4@0+ (1,0) [0|15] "" ACP2_MCU,EOCM,EOCM_HC_Superset
 SG_ UODPFrtSnsr1EchoQlty2 : 94|4@0+ (1,0) [0|15] "" ACP2_MCU,EOCM,EOCM_HC_Superset
 SG_ UODPFrtSnsr2EchoDist1 : 99|11@0+ (0.25,0) [0|511.75] "cm" ACP2_MCU,EOCM,EOCM_HC_Superset
 SG_ UODPFrtSnsr1EchoSnsrMode : 101|2@0+ (1,0) [0|2] "" ACP2_MCU,EOCM,EOCM_HC_Superset
 SG_ UODPFrtSnsr1EchoSnsrDatUsg : 102|1@0+ (1,0) [0|1] "" ACP2_MCU,EOCM,EOCM_HC_Superset
 SG_ UODPFrtSnsr2EchoDist2 : 104|11@0+ (0.25,0) [0|511.75] "cm" ACP2_MCU,EOCM,EOCM_HC_Superset
 SG_ UODPFrtSnsr2EchoDist3 : 125|11@0+ (0.25,0) [0|511.75] "cm" ACP2_MCU,EOCM,EOCM_HC_Superset
 SG_ UODPFrtSnsr2EchoQlty1 : 130|4@0+ (1,0) [0|15] "" ACP2_MCU,EOCM,EOCM_HC_Superset
 SG_ UODPFrtSnsr2EchoQlty3 : 138|4@0+ (1,0) [0|15] "" ACP2_MCU,EOCM,EOCM_HC_Superset
 SG_ UODPFrtSnsr2EchoQlty2 : 142|4@0+ (1,0) [0|15] "" ACP2_MCU,EOCM,EOCM_HC_Superset
 SG_ UODPFrtSnsr3EchoDist1 : 147|11@0+ (0.25,0) [0|511.75] "cm" ACP2_MCU,EOCM,EOCM_HC_Superset
 SG_ UODPFrtSnsr2EchoSnsrMode : 149|2@0+ (1,0) [0|2] "" ACP2_MCU,EOCM,EOCM_HC_Superset
 SG_ UODPFrtSnsr2EchoSnsrDatUsg : 150|1@0+ (1,0) [0|1] "" ACP2_MCU,EOCM,EOCM_HC_Superset
 SG_ UODPFrtSnsr3EchoDist2 : 152|11@0+ (0.25,0) [0|511.75] "cm" ACP2_MCU,EOCM,EOCM_HC_Superset
 SG_ UODPFrtSnsr3EchoDist3 : 173|11@0+ (0.25,0) [0|511.75] "cm" ACP2_MCU,EOCM,EOCM_HC_Superset
 SG_ UODPFrtSnsr3EchoQlty1 : 178|4@0+ (1,0) [0|15] "" ACP2_MCU,EOCM,EOCM_HC_Superset
 SG_ UODPFrtSnsr3EchoQlty3 : 186|4@0+ (1,0) [0|15] "" ACP2_MCU,EOCM,EOCM_HC_Superset
 SG_ UODPFrtSnsr3EchoQlty2 : 190|4@0+ (1,0) [0|15] "" ACP2_MCU,EOCM,EOCM_HC_Superset
 SG_ UODPFrtSnsr4EchoDist1 : 195|11@0+ (0.25,0) [0|511.75] "cm" ACP2_MCU,EOCM,EOCM_HC_Superset
 SG_ UODPFrtSnsr3EchoSnsrMode : 197|2@0+ (1,0) [0|2] "" ACP2_MCU,EOCM,EOCM_HC_Superset
 SG_ UODPFrtSnsr3EchoSnsrDatUsg : 198|1@0+ (1,0) [0|1] "" ACP2_MCU,EOCM,EOCM_HC_Superset
 SG_ UODPFrtSnsr4EchoDist2 : 200|11@0+ (0.25,0) [0|511.75] "cm" ACP2_MCU,EOCM,EOCM_HC_Superset
 SG_ UODPFrtSnsr4EchoDist3 : 221|11@0+ (0.25,0) [0|511.75] "cm" ACP2_MCU,EOCM,EOCM_HC_Superset
 SG_ UODPFrtSnsr4EchoQlty1 : 226|4@0+ (1,0) [0|15] "" ACP2_MCU,EOCM,EOCM_HC_Superset
 SG_ UODPFrtSnsr4EchoQlty3 : 234|4@0+ (1,0) [0|15] "" ACP2_MCU,EOCM,EOCM_HC_Superset
 SG_ UODPFrtSnsr4EchoQlty2 : 238|4@0+ (1,0) [0|15] "" ACP2_MCU,EOCM,EOCM_HC_Superset
 SG_ UODPFrtSnsr5EchoDist1 : 243|11@0+ (0.25,0) [0|511.75] "cm" ACP2_MCU,EOCM,EOCM_HC_Superset
 SG_ UODPFrtSnsr4EchoSnsrMode : 245|2@0+ (1,0) [0|2] "" ACP2_MCU,EOCM,EOCM_HC_Superset
 SG_ UODPFrtSnsr4EchoSnsrDatUsg : 246|1@0+ (1,0) [0|1] "" ACP2_MCU,EOCM,EOCM_HC_Superset
 SG_ UODPFrtSnsr5EchoDist2 : 248|11@0+ (0.25,0) [0|511.75] "cm" ACP2_MCU,EOCM,EOCM_HC_Superset
 SG_ UODPFrtSnsr5EchoDist3 : 269|11@0+ (0.25,0) [0|511.75] "cm" ACP2_MCU,EOCM,EOCM_HC_Superset
 SG_ UODPFrtSnsr5EchoQlty1 : 274|4@0+ (1,0) [0|15] "" ACP2_MCU,EOCM,EOCM_HC_Superset
 SG_ UODPFrtSnsr5EchoQlty3 : 282|4@0+ (1,0) [0|15] "" ACP2_MCU,EOCM,EOCM_HC_Superset
 SG_ UODPFrtSnsr5EchoQlty2 : 286|4@0+ (1,0) [0|15] "" ACP2_MCU,EOCM,EOCM_HC_Superset
 SG_ UODPFrtSnsr6EchoDist1 : 291|11@0+ (0.25,0) [0|511.75] "cm" ACP2_MCU,EOCM,EOCM_HC_Superset
 SG_ UODPFrtSnsr5EchoSnsrMode : 293|2@0+ (1,0) [0|2] "" ACP2_MCU,EOCM,EOCM_HC_Superset
 SG_ UODPFrtSnsr5EchoSnsrDatUsg : 294|1@0+ (1,0) [0|1] "" ACP2_MCU,EOCM,EOCM_HC_Superset
 SG_ UODPFrtSnsr6EchoDist2 : 296|11@0+ (0.25,0) [0|511.75] "cm" ACP2_MCU,EOCM,EOCM_HC_Superset
 SG_ UODPFrtSnsr6EchoDist3 : 317|11@0+ (0.25,0) [0|511.75] "cm" ACP2_MCU,EOCM,EOCM_HC_Superset
 SG_ UODPFrtSnsr6EchoQlty1 : 322|4@0+ (1,0) [0|15] "" ACP2_MCU,EOCM,EOCM_HC_Superset
 SG_ UODPFrtSnsr6EchoQlty3 : 330|4@0+ (1,0) [0|15] "" ACP2_MCU,EOCM,EOCM_HC_Superset
 SG_ UODPFrtSnsr6EchoQlty2 : 334|4@0+ (1,0) [0|15] "" ACP2_MCU,EOCM,EOCM_HC_Superset
 SG_ UODPFrtModSts : 338|3@0+ (1,0) [0|5] "" ACP2_MCU,EOCM,EOCM_HC_Superset
 SG_ UODPSnsAutoPrkAval : 339|1@0+ (1,0) [0|1] "" ACP2_MCU,EOCM,EOCM_HC_Superset
 SG_ UODPFrtSnsr6EchoSnsrMode : 341|2@0+ (1,0) [0|2] "" ACP2_MCU,EOCM,EOCM_HC_Superset
 SG_ UODPFrtSnsr6EchoSnsrDatUsg : 342|1@0+ (1,0) [0|1] "" ACP2_MCU,EOCM,EOCM_HC_Superset
 SG_ SD101P_ARC : 351|2@0+ (1,0) [0|3] "" ACP2_MCU,EOCM,EOCM_HC_Superset

BO_ 883 SrlDat102_PCSM_PDU: 8 UPM
 SG_ SrlDat102_PCSM : 0|64@1+ (1,0) [0|1.84467e+019] "" ACP2_MCU,EOCM,EOCM_HC_Superset

BO_ 532 SrlDat102_Prtctd_PDU: 48 UPM
 SG_ SD102P_MAC : 7|32@0+ (1,0) [0|4.29497e+009] "" ACP2_MCU,EOCM,EOCM_HC_Superset
 SG_ SD102P_FCnt : 39|5@0+ (1,0) [0|31] "" ACP2_MCU,EOCM,EOCM_HC_Superset
 SG_ UODPRrEchoAcqTmStm : 47|11@0+ (1,0) [0|2047] "ms" ACP2_MCU,EOCM,EOCM_HC_Superset
 SG_ UODPRrSnsr1EchoDist1 : 51|11@0+ (0.25,0) [0|511.75] "cm" ACP2_MCU,EOCM,EOCM_HC_Superset
 SG_ UODPRrEchoAcqTmStm_Inv : 52|1@0+ (1,0) [0|1] "" ACP2_MCU,EOCM,EOCM_HC_Superset
 SG_ UODPRrSnsr1EchoDist2 : 56|11@0+ (0.25,0) [0|511.75] "cm" ACP2_MCU,EOCM,EOCM_HC_Superset
 SG_ UODPRrSnsr1EchoDist3 : 77|11@0+ (0.25,0) [0|511.75] "cm" ACP2_MCU,EOCM,EOCM_HC_Superset
 SG_ UODPRrSnsr1EchoQlty1 : 82|4@0+ (1,0) [0|15] "" ACP2_MCU,EOCM,EOCM_HC_Superset
 SG_ UODPRrSnsr1EchoQlty3 : 90|4@0+ (1,0) [0|15] "" ACP2_MCU,EOCM,EOCM_HC_Superset
 SG_ UODPRrSnsr1EchoQlty2 : 94|4@0+ (1,0) [0|15] "" ACP2_MCU,EOCM,EOCM_HC_Superset
 SG_ UODPRrSnsr2EchoDist1 : 99|11@0+ (0.25,0) [0|511.75] "cm" ACP2_MCU,EOCM,EOCM_HC_Superset
 SG_ UODPRrSnsr1EchoSnsrMode : 101|2@0+ (1,0) [0|2] "" ACP2_MCU,EOCM,EOCM_HC_Superset
 SG_ UODPRrSnsr1EchoSnsrDatUsg : 102|1@0+ (1,0) [0|1] "" ACP2_MCU,EOCM,EOCM_HC_Superset
 SG_ UODPRrSnsr2EchoDist2 : 104|11@0+ (0.25,0) [0|511.75] "cm" ACP2_MCU,EOCM,EOCM_HC_Superset
 SG_ UODPRrSnsr2EchoDist3 : 125|11@0+ (0.25,0) [0|511.75] "cm" ACP2_MCU,EOCM,EOCM_HC_Superset
 SG_ UODPRrSnsr2EchoQlty1 : 130|4@0+ (1,0) [0|15] "" ACP2_MCU,EOCM,EOCM_HC_Superset
 SG_ UODPRrSnsr2EchoQlty3 : 138|4@0+ (1,0) [0|15] "" ACP2_MCU,EOCM,EOCM_HC_Superset
 SG_ UODPRrSnsr2EchoQlty2 : 142|4@0+ (1,0) [0|15] "" ACP2_MCU,EOCM,EOCM_HC_Superset
 SG_ UODPRrSnsr3EchoDist1 : 147|11@0+ (0.25,0) [0|511.75] "cm" ACP2_MCU,EOCM,EOCM_HC_Superset
 SG_ UODPRrSnsr2EchoSnsrMode : 149|2@0+ (1,0) [0|2] "" ACP2_MCU,EOCM,EOCM_HC_Superset
 SG_ UODPRrSnsr2EchoSnsrDatUsg : 150|1@0+ (1,0) [0|1] "" ACP2_MCU,EOCM,EOCM_HC_Superset
 SG_ UODPRrSnsr3EchoDist2 : 152|11@0+ (0.25,0) [0|511.75] "cm" ACP2_MCU,EOCM,EOCM_HC_Superset
 SG_ UODPRrSnsr3EchoDist3 : 173|11@0+ (0.25,0) [0|511.75] "cm" ACP2_MCU,EOCM,EOCM_HC_Superset
 SG_ UODPRrSnsr3EchoQlty1 : 178|4@0+ (1,0) [0|15] "" ACP2_MCU,EOCM,EOCM_HC_Superset
 SG_ UODPRrSnsr3EchoQlty3 : 186|4@0+ (1,0) [0|15] "" ACP2_MCU,EOCM,EOCM_HC_Superset
 SG_ UODPRrSnsr3EchoQlty2 : 190|4@0+ (1,0) [0|15] "" ACP2_MCU,EOCM,EOCM_HC_Superset
 SG_ UODPRrSnsr4EchoDist1 : 195|11@0+ (0.25,0) [0|511.75] "cm" ACP2_MCU,EOCM,EOCM_HC_Superset
 SG_ UODPRrSnsr3EchoSnsrMode : 197|2@0+ (1,0) [0|2] "" ACP2_MCU,EOCM,EOCM_HC_Superset
 SG_ UODPRrSnsr3EchoSnsrDatUsg : 198|1@0+ (1,0) [0|1] "" ACP2_MCU,EOCM,EOCM_HC_Superset
 SG_ UODPRrSnsr4EchoDist2 : 200|11@0+ (0.25,0) [0|511.75] "cm" ACP2_MCU,EOCM,EOCM_HC_Superset
 SG_ UODPRrSnsr4EchoDist3 : 221|11@0+ (0.25,0) [0|511.75] "cm" ACP2_MCU,EOCM,EOCM_HC_Superset
 SG_ UODPRrSnsr4EchoQlty1 : 226|4@0+ (1,0) [0|15] "" ACP2_MCU,EOCM,EOCM_HC_Superset
 SG_ UODPRrSnsr4EchoQlty3 : 234|4@0+ (1,0) [0|15] "" ACP2_MCU,EOCM,EOCM_HC_Superset
 SG_ UODPRrSnsr4EchoQlty2 : 238|4@0+ (1,0) [0|15] "" ACP2_MCU,EOCM,EOCM_HC_Superset
 SG_ UODPRrSnsr5EchoDist1 : 243|11@0+ (0.25,0) [0|511.75] "cm" ACP2_MCU,EOCM,EOCM_HC_Superset
 SG_ UODPRrSnsr4EchoSnsrMode : 245|2@0+ (1,0) [0|2] "" ACP2_MCU,EOCM,EOCM_HC_Superset
 SG_ UODPRrSnsr4EchoSnsrDatUsg : 246|1@0+ (1,0) [0|1] "" ACP2_MCU,EOCM,EOCM_HC_Superset
 SG_ UODPRrSnsr5EchoDist2 : 248|11@0+ (0.25,0) [0|511.75] "cm" ACP2_MCU,EOCM,EOCM_HC_Superset
 SG_ UODPRrSnsr5EchoDist3 : 269|11@0+ (0.25,0) [0|511.75] "cm" ACP2_MCU,EOCM,EOCM_HC_Superset
 SG_ UODPRrSnsr5EchoQlty1 : 274|4@0+ (1,0) [0|15] "" ACP2_MCU,EOCM,EOCM_HC_Superset
 SG_ UODPRrSnsr5EchoQlty3 : 282|4@0+ (1,0) [0|15] "" ACP2_MCU,EOCM,EOCM_HC_Superset
 SG_ UODPRrSnsr5EchoQlty2 : 286|4@0+ (1,0) [0|15] "" ACP2_MCU,EOCM,EOCM_HC_Superset
 SG_ UODPRrSnsr6EchoDist1 : 291|11@0+ (0.25,0) [0|511.75] "cm" ACP2_MCU,EOCM,EOCM_HC_Superset
 SG_ UODPRrSnsr5EchoSnsrMode : 293|2@0+ (1,0) [0|2] "" ACP2_MCU,EOCM,EOCM_HC_Superset
 SG_ UODPRrSnsr5EchoSnsrDatUsg : 294|1@0+ (1,0) [0|1] "" ACP2_MCU,EOCM,EOCM_HC_Superset
 SG_ UODPRrSnsr6EchoDist2 : 296|11@0+ (0.25,0) [0|511.75] "cm" ACP2_MCU,EOCM,EOCM_HC_Superset
 SG_ UODPRrSnsr6EchoDist3 : 317|11@0+ (0.25,0) [0|511.75] "cm" ACP2_MCU,EOCM,EOCM_HC_Superset
 SG_ UODPRrSnsr6EchoQlty1 : 322|4@0+ (1,0) [0|15] "" ACP2_MCU,EOCM,EOCM_HC_Superset
 SG_ UODPRrSnsr6EchoQlty3 : 330|4@0+ (1,0) [0|15] "" ACP2_MCU,EOCM,EOCM_HC_Superset
 SG_ UODPRrSnsr6EchoQlty2 : 334|4@0+ (1,0) [0|15] "" ACP2_MCU,EOCM,EOCM_HC_Superset
 SG_ SD102P_ARC : 336|2@0+ (1,0) [0|3] "" ACP2_MCU,EOCM,EOCM_HC_Superset
 SG_ UODPRrModSts : 339|3@0+ (1,0) [0|5] "" ACP2_MCU,EOCM,EOCM_HC_Superset
 SG_ UODPRrSnsr6EchoSnsrMode : 341|2@0+ (1,0) [0|2] "" ACP2_MCU,EOCM,EOCM_HC_Superset
 SG_ UODPRrSnsr6EchoSnsrDatUsg : 342|1@0+ (1,0) [0|1] "" ACP2_MCU,EOCM,EOCM_HC_Superset

BO_ 1326 SrlDat104_BrstGrp_PCSM_PDU: 8 UPM
 SG_ SrlDat104BrstGrp1_PCSM : 0|64@1+ (1,0) [0|1.84467e+019] "" ACP2_MCU,EOCM,EOCM_HC_Superset

BO_ 594 SrlDat104_BrstGrp_Prtctd_First_F: 64 UPM
 SG_ SD104BG1P_MAC : 7|32@0+ (1,0) [0|4.29497e+009] "" ACP2_MCU,EOCM,EOCM_HC_Superset
 SG_ SD104BG1P_FCnt : 39|5@0+ (1,0) [0|31] "" ACP2_MCU,EOCM,EOCM_HC_Superset
 SG_ UODPLoclzdObj10PstnP1X : 43|11@0- (1,0) [-1024|1023] "cm" ACP2_MCU,EOCM,EOCM_HC_Superset
 SG_ UODPLoclzdObj10Hght : 45|2@0+ (1,0) [0|3] "" ACP2_MCU,EOCM,EOCM_HC_Superset
 SG_ SD104BG1P_BrstID : 47|2@0+ (1,0) [0|3] "" ACP2_MCU,EOCM,EOCM_HC_Superset
 SG_ UODPLoclzdObj10PstnP1Y : 48|11@0- (1,0) [-1024|1023] "cm" ACP2_MCU,EOCM,EOCM_HC_Superset
 SG_ UODPLoclzdObj10PstnP2X : 69|11@0- (1,0) [-1024|1023] "cm" ACP2_MCU,EOCM,EOCM_HC_Superset
 SG_ UODPLoclzdObj10PstnP2Y : 74|11@0- (1,0) [-1024|1023] "cm" ACP2_MCU,EOCM,EOCM_HC_Superset
 SG_ UODPLoclzdObj1PstnP1X : 93|11@0- (1,0) [-1024|1023] "cm" ACP2_MCU,EOCM,EOCM_HC_Superset
 SG_ UODPLoclzdObj1Hght : 95|2@0+ (1,0) [0|3] "" ACP2_MCU,EOCM,EOCM_HC_Superset
 SG_ UODPLoclzdObj1PstnP1Y : 98|11@0- (1,0) [-1024|1023] "cm" ACP2_MCU,EOCM,EOCM_HC_Superset
 SG_ UODPLoclzdObj1PstnP2X : 119|11@0- (1,0) [-1024|1023] "cm" ACP2_MCU,EOCM,EOCM_HC_Superset
 SG_ UODPLoclzdObj1PstnP2Y : 124|11@0- (1,0) [-1024|1023] "cm" ACP2_MCU,EOCM,EOCM_HC_Superset
 SG_ UODPLoclzdObj2Hght : 129|2@0+ (1,0) [0|3] "" ACP2_MCU,EOCM,EOCM_HC_Superset
 SG_ UODPLoclzdObj2PstnP1X : 143|11@0- (1,0) [-1024|1023] "cm" ACP2_MCU,EOCM,EOCM_HC_Superset
 SG_ UODPLoclzdObj2PstnP1Y : 148|11@0- (1,0) [-1024|1023] "cm" ACP2_MCU,EOCM,EOCM_HC_Superset
 SG_ UODPLoclzdObj2PstnP2X : 153|11@0- (1,0) [-1024|1023] "cm" ACP2_MCU,EOCM,EOCM_HC_Superset
 SG_ UODPLoclzdObj2PstnP2Y : 174|11@0- (1,0) [-1024|1023] "cm" ACP2_MCU,EOCM,EOCM_HC_Superset
 SG_ UODPLoclzdObj3PstnP1X : 177|11@0- (1,0) [-1024|1023] "cm" ACP2_MCU,EOCM,EOCM_HC_Superset
 SG_ UODPLoclzdObj3Hght : 179|2@0+ (1,0) [0|3] "" ACP2_MCU,EOCM,EOCM_HC_Superset
 SG_ UODPLoclzdObj3PstnP1Y : 198|11@0- (1,0) [-1024|1023] "cm" ACP2_MCU,EOCM,EOCM_HC_Superset
 SG_ UODPLoclzdObj3PstnP2X : 203|11@0- (1,0) [-1024|1023] "cm" ACP2_MCU,EOCM,EOCM_HC_Superset
 SG_ UODPLoclzdObj3PstnP2Y : 208|11@0- (1,0) [-1024|1023] "cm" ACP2_MCU,EOCM,EOCM_HC_Superset
 SG_ UODPLoclzdObj4PstnP1X : 227|11@0- (1,0) [-1024|1023] "cm" ACP2_MCU,EOCM,EOCM_HC_Superset
 SG_ UODPLoclzdObj4Hght : 229|2@0+ (1,0) [0|3] "" ACP2_MCU,EOCM,EOCM_HC_Superset
 SG_ UODPLoclzdObj4PstnP1Y : 232|11@0- (1,0) [-1024|1023] "cm" ACP2_MCU,EOCM,EOCM_HC_Superset
 SG_ UODPLoclzdObj4PstnP2X : 253|11@0- (1,0) [-1024|1023] "cm" ACP2_MCU,EOCM,EOCM_HC_Superset
 SG_ UODPLoclzdObj4PstnP2Y : 258|11@0- (1,0) [-1024|1023] "cm" ACP2_MCU,EOCM,EOCM_HC_Superset
 SG_ UODPLoclzdObj5PstnP1X : 277|11@0- (1,0) [-1024|1023] "cm" ACP2_MCU,EOCM,EOCM_HC_Superset
 SG_ UODPLoclzdObj5Hght : 279|2@0+ (1,0) [0|3] "" ACP2_MCU,EOCM,EOCM_HC_Superset
 SG_ UODPLoclzdObj5PstnP1Y : 282|11@0- (1,0) [-1024|1023] "cm" ACP2_MCU,EOCM,EOCM_HC_Superset
 SG_ UODPLoclzdObj5PstnP2X : 303|11@0- (1,0) [-1024|1023] "cm" ACP2_MCU,EOCM,EOCM_HC_Superset
 SG_ UODPLoclzdObj5PstnP2Y : 308|11@0- (1,0) [-1024|1023] "cm" ACP2_MCU,EOCM,EOCM_HC_Superset
 SG_ UODPLoclzdObj6Hght : 313|2@0+ (1,0) [0|3] "" ACP2_MCU,EOCM,EOCM_HC_Superset
 SG_ UODPLoclzdObj6PstnP1X : 327|11@0- (1,0) [-1024|1023] "cm" ACP2_MCU,EOCM,EOCM_HC_Superset
 SG_ UODPLoclzdObj6PstnP1Y : 332|11@0- (1,0) [-1024|1023] "cm" ACP2_MCU,EOCM,EOCM_HC_Superset
 SG_ UODPLoclzdObj6PstnP2X : 337|11@0- (1,0) [-1024|1023] "cm" ACP2_MCU,EOCM,EOCM_HC_Superset
 SG_ UODPLoclzdObj6PstnP2Y : 358|11@0- (1,0) [-1024|1023] "cm" ACP2_MCU,EOCM,EOCM_HC_Superset
 SG_ UODPLoclzdObj7PstnP1X : 361|11@0- (1,0) [-1024|1023] "cm" ACP2_MCU,EOCM,EOCM_HC_Superset
 SG_ UODPLoclzdObj7Hght : 363|2@0+ (1,0) [0|3] "" ACP2_MCU,EOCM,EOCM_HC_Superset
 SG_ UODPLoclzdObj7PstnP1Y : 382|11@0- (1,0) [-1024|1023] "cm" ACP2_MCU,EOCM,EOCM_HC_Superset
 SG_ UODPLoclzdObj7PstnP2X : 387|11@0- (1,0) [-1024|1023] "cm" ACP2_MCU,EOCM,EOCM_HC_Superset
 SG_ UODPLoclzdObj7PstnP2Y : 392|11@0- (1,0) [-1024|1023] "cm" ACP2_MCU,EOCM,EOCM_HC_Superset
 SG_ UODPLoclzdObj8PstnP1X : 411|11@0- (1,0) [-1024|1023] "cm" ACP2_MCU,EOCM,EOCM_HC_Superset
 SG_ UODPLoclzdObj8Hght : 413|2@0+ (1,0) [0|3] "" ACP2_MCU,EOCM,EOCM_HC_Superset
 SG_ UODPLoclzdObj8PstnP1Y : 416|11@0- (1,0) [-1024|1023] "cm" ACP2_MCU,EOCM,EOCM_HC_Superset
 SG_ UODPLoclzdObj8PstnP2X : 437|11@0- (1,0) [-1024|1023] "cm" ACP2_MCU,EOCM,EOCM_HC_Superset
 SG_ UODPLoclzdObj8PstnP2Y : 442|11@0- (1,0) [-1024|1023] "cm" ACP2_MCU,EOCM,EOCM_HC_Superset
 SG_ UODPLoclzdObj9PstnP1X : 461|11@0- (1,0) [-1024|1023] "cm" ACP2_MCU,EOCM,EOCM_HC_Superset
 SG_ UODPLoclzdObj9Hght : 463|2@0+ (1,0) [0|3] "" ACP2_MCU,EOCM,EOCM_HC_Superset
 SG_ UODPLoclzdObj9PstnP1Y : 466|11@0- (1,0) [-1024|1023] "cm" ACP2_MCU,EOCM,EOCM_HC_Superset
 SG_ UODPLoclzdObj9PstnP2X : 487|11@0- (1,0) [-1024|1023] "cm" ACP2_MCU,EOCM,EOCM_HC_Superset
 SG_ UODPLoclzdObj9PstnP2Y : 492|11@0- (1,0) [-1024|1023] "cm" ACP2_MCU,EOCM,EOCM_HC_Superset
 SG_ SD104BG1P_ARC : 497|2@0+ (1,0) [0|3] "" ACP2_MCU,EOCM,EOCM_HC_Superset

BO_ 593 SrlDat104_BrstGrp_Prtctd_Last_Fr: 20 UPM
 SG_ UODPLoclzdObj10Cnfd : 5|6@0+ (2,0) [0|126] "%" ACP2_MCU,EOCM,EOCM_HC_Superset
 SG_ SD104BG2P_BrstID : 7|2@0+ (1,0) [0|3] "" ACP2_MCU,EOCM,EOCM_HC_Superset
 SG_ UODPLoclzdObj10Typ : 9|3@0+ (1,0) [0|5] "" ACP2_MCU,EOCM,EOCM_HC_Superset
 SG_ UODPLoclzdObj10HghtCnfd : 15|6@0+ (2,0) [0|126] "%" ACP2_MCU,EOCM,EOCM_HC_Superset
 SG_ UODPLoclzdObj1HghtCnfd : 16|6@0+ (2,0) [0|126] "%" ACP2_MCU,EOCM,EOCM_HC_Superset
 SG_ UODPLoclzdObj1Cnfd : 22|6@0+ (2,0) [0|126] "%" ACP2_MCU,EOCM,EOCM_HC_Superset
 SG_ UODPLoclzdObj1Typ : 26|3@0+ (1,0) [0|5] "" ACP2_MCU,EOCM,EOCM_HC_Superset
 SG_ UODPLoclzdObj2HghtCnfd : 33|6@0+ (2,0) [0|126] "%" ACP2_MCU,EOCM,EOCM_HC_Superset
 SG_ UODPLoclzdObj2Cnfd : 39|6@0+ (2,0) [0|126] "%" ACP2_MCU,EOCM,EOCM_HC_Superset
 SG_ UODPLoclzdObj3Cnfd : 40|6@0+ (2,0) [0|126] "%" ACP2_MCU,EOCM,EOCM_HC_Superset
 SG_ UODPLoclzdObj2Typ : 43|3@0+ (1,0) [0|5] "" ACP2_MCU,EOCM,EOCM_HC_Superset
 SG_ UODPLoclzdObj3HghtCnfd : 50|6@0+ (2,0) [0|126] "%" ACP2_MCU,EOCM,EOCM_HC_Superset
 SG_ UODPLoclzdObj4Cnfd : 57|6@0+ (2,0) [0|126] "%" ACP2_MCU,EOCM,EOCM_HC_Superset
 SG_ UODPLoclzdObj3Typ : 60|3@0+ (1,0) [0|5] "" ACP2_MCU,EOCM,EOCM_HC_Superset
 SG_ UODPLoclzdObj4HghtCnfd : 67|6@0+ (2,0) [0|126] "%" ACP2_MCU,EOCM,EOCM_HC_Superset
 SG_ UODPLoclzdObj5Cnfd : 74|6@0+ (2,0) [0|126] "%" ACP2_MCU,EOCM,EOCM_HC_Superset
 SG_ UODPLoclzdObj4Typ : 77|3@0+ (1,0) [0|5] "" ACP2_MCU,EOCM,EOCM_HC_Superset
 SG_ UODPLoclzdObj5HghtCnfd : 84|6@0+ (2,0) [0|126] "%" ACP2_MCU,EOCM,EOCM_HC_Superset
 SG_ UODPLoclzdObj6Cnfd : 91|6@0+ (2,0) [0|126] "%" ACP2_MCU,EOCM,EOCM_HC_Superset
 SG_ UODPLoclzdObj5Typ : 94|3@0+ (1,0) [0|5] "" ACP2_MCU,EOCM,EOCM_HC_Superset
 SG_ UODPLoclzdObj6HghtCnfd : 101|6@0+ (2,0) [0|126] "%" ACP2_MCU,EOCM,EOCM_HC_Superset
 SG_ UODPLoclzdObj7Cnfd : 108|6@0+ (2,0) [0|126] "%" ACP2_MCU,EOCM,EOCM_HC_Superset
 SG_ UODPLoclzdObj6Typ : 111|3@0+ (1,0) [0|5] "" ACP2_MCU,EOCM,EOCM_HC_Superset
 SG_ UODPLoclzdObj7Typ : 112|3@0+ (1,0) [0|5] "" ACP2_MCU,EOCM,EOCM_HC_Superset
 SG_ UODPLoclzdObj7HghtCnfd : 118|6@0+ (2,0) [0|126] "%" ACP2_MCU,EOCM,EOCM_HC_Superset
 SG_ UODPLoclzdObj8Cnfd : 125|6@0+ (2,0) [0|126] "%" ACP2_MCU,EOCM,EOCM_HC_Superset
 SG_ UODPLoclzdObj8Typ : 129|3@0+ (1,0) [0|5] "" ACP2_MCU,EOCM,EOCM_HC_Superset
 SG_ UODPLoclzdObj8HghtCnfd : 135|6@0+ (2,0) [0|126] "%" ACP2_MCU,EOCM,EOCM_HC_Superset
 SG_ UODPLoclzdObj9HghtCnfd : 136|6@0+ (2,0) [0|126] "%" ACP2_MCU,EOCM,EOCM_HC_Superset
 SG_ UODPLoclzdObj9Cnfd : 142|6@0+ (2,0) [0|126] "%" ACP2_MCU,EOCM,EOCM_HC_Superset
 SG_ UODPLoclzdObj9Typ : 146|3@0+ (1,0) [0|5] "" ACP2_MCU,EOCM,EOCM_HC_Superset

BO_ 882 SrlDat105_PCSM_PDU: 8 ACP2_MCU
 SG_ SrlDat105_PCSM : 0|64@1+ (1,0) [0|1.84467e+019] "" UPM

BO_ 33 SrlDat105_Prtctd_PDU: 8 ACP2_MCU
 SG_ SD105P_MAC : 7|27@0+ (1,0) [0|1.34218e+008] "" UPM
 SG_ SD105P_FCnt : 28|5@0+ (1,0) [0|31] "" UPM
 SG_ SD105P_Filler : 35|26@0+ (1,0) [0|6.71089e+007] "" UPM
 SG_ SuprRmtPrkFirngModeReq : 38|3@0+ (1,0) [0|5] "" UPM
 SG_ AutoPrkUltrsncObjSnsActvnReqd : 39|1@0+ (1,0) [0|1] "" UPM
 SG_ SD105P_ARC : 57|2@0+ (1,0) [0|3] "" UPM

BO_ 540 SrlDat197_PCSM_PDU: 8 SRR_LR_CR
 SG_ SrlDat197_PCSM : 0|64@1+ (1,0) [0|1.84467e+019] "" SRR_RR

BO_ 23 SrlDat197_Prtctd_PDU: 32 SRR_LR_CR
 SG_ SD197P_MAC : 7|32@0+ (1,0) [0|4.29497e+009] "" SRR_RR
 SG_ SD197P_FCnt : 39|5@0+ (1,0) [0|31] "" SRR_RR
 SG_ SRRLRCRODPTOVYawRate : 47|11@0+ (0.002,0) [0|4.094] "(rad/s)^2" SRR_RR
 SG_ SRRLRCRODPTrObjYawRate : 52|11@0- (0.002,0) [-2.048|2.046] "rad/s" SRR_RR
 SG_ SRRLRCRODPTrObjOrntn : 57|10@0- (0.01,0) [-5.12|5.11] "rad" SRR_RR
 SG_ SRRLRCRODPTODTrHtchTrFrt : 79|8@0- (0.1,0) [-12.8|12.7] "m" SRR_RR
 SG_ SRRLRCRODPTOVLgth : 87|8@0+ (0.1,0) [0|25.5] "m^2" SRR_RR
 SG_ SRRLRCRODPTOVOrntn : 95|8@0+ (0.01,0) [0|2.55] "rad^2" SRR_RR
 SG_ SRRLRCRODPTOVWdth : 103|8@0+ (0.1,0) [0|25.5] "m^2" SRR_RR
 SG_ SRRLRCRODPTrObjLgth : 111|8@0+ (0.1,0) [0|25.5] "m" SRR_RR
 SG_ SRRLRCRODPTODVhFrtAxVhHtch : 112|7@0+ (0.1,0) [0|12.7] "m" SRR_RR
 SG_ SRRLRCRODPTODTrHtchTrAx : 119|7@0+ (0.1,0) [0|12.7] "m" SRR_RR
 SG_ SRRLRCRODPTOEExistPrblty : 121|7@0+ (0.01,0) [0|1.27] "" SRR_RR
 SG_ SRRLRCRODPTOPDtnPrblty : 130|7@0+ (0.01,0) [0|1.27] "" SRR_RR
 SG_ SRRLRCRODPTrObjQlty : 139|7@0+ (1,0) [0|127] "%" SRR_RR
 SG_ SRRLRCRODPTOVDTrHtchTrAx : 148|6@0+ (0.1,0) [0|6.3] "m^2" SRR_RR
 SG_ SRRLRCRODPTOVDVhFrtAxVhHtch : 152|6@0+ (0.1,0) [0|6.3] "m^2" SRR_RR
 SG_ SRRLRCRODPTOVDTrHtchTrFrt : 158|6@0+ (0.1,0) [0|6.3] "m^2" SRR_RR
 SG_ SRRLRCRODPTrObjWdth : 162|6@0+ (0.1,0) [0|6.3] "m" SRR_RR
 SG_ SRRLRCRODPTrObjStatInfo : 169|3@0+ (1,0) [0|4] "" SRR_RR
 SG_ SRRLRCRODPTrObjExtrnInfo : 172|3@0+ (1,0) [0|7] "" SRR_RR
 SG_ SRRLRCRODPTOPDtnPrblty_Inv : 176|1@0+ (1,0) [0|1] "" SRR_RR
 SG_ SRRLRCRODPTOEExistPrblty_Inv : 177|1@0+ (1,0) [0|1] "" SRR_RR
 SG_ SRRLRCRODPTODVhFrtAxVhHtch_Inv : 178|1@0+ (1,0) [0|1] "" SRR_RR
 SG_ SRRLRCRODPTODTrHtchTrFrt_Inv : 179|1@0+ (1,0) [0|1] "" SRR_RR
 SG_ SRRLRCRODPTODTrHtchTrAx_Inv : 180|1@0+ (1,0) [0|1] "" SRR_RR
 SG_ SRRLRCRODPTrAtchdInfo : 182|2@0+ (1,0) [0|3] "" SRR_RR
 SG_ SRRLRCRODPTrObjExtrnInfo_Inv : 184|1@0+ (1,0) [0|1] "" SRR_RR
 SG_ SRRLRCRODPTOVYawRate_Inv : 185|1@0+ (1,0) [0|1] "" SRR_RR
 SG_ SRRLRCRODPTOVWdth_Inv : 186|1@0+ (1,0) [0|1] "" SRR_RR
 SG_ SRRLRCRODPTOVOrntn_Inv : 187|1@0+ (1,0) [0|1] "" SRR_RR
 SG_ SRRLRCRODPTOVLgth_Inv : 188|1@0+ (1,0) [0|1] "" SRR_RR
 SG_ SRRLRCRODPTOVDVhFrtAxVhHtch_Inv : 189|1@0+ (1,0) [0|1] "" SRR_RR
 SG_ SRRLRCRODPTOVDTrHtchTrFrt_Inv : 190|1@0+ (1,0) [0|1] "" SRR_RR
 SG_ SRRLRCRODPTOVDTrHtchTrAx_Inv : 191|1@0+ (1,0) [0|1] "" SRR_RR
 SG_ SrlDat197_Filler : 194|32@0+ (1,0) [0|4.29497e+009] "" SRR_RR
 SG_ SRRLRCRODPTrObjYawRate_Inv : 195|1@0+ (1,0) [0|1] "" SRR_RR
 SG_ SRRLRCRODPTrObjWdth_Inv : 196|1@0+ (1,0) [0|1] "" SRR_RR
 SG_ SRRLRCRODPTrObjQlty_Inv : 197|1@0+ (1,0) [0|1] "" SRR_RR
 SG_ SRRLRCRODPTrObjOrntn_Inv : 198|1@0+ (1,0) [0|1] "" SRR_RR
 SG_ SRRLRCRODPTrObjLgth_Inv : 199|1@0+ (1,0) [0|1] "" SRR_RR
 SG_ SrlDat197_FillerExtnd : 226|25@0+ (1,0) [0|3.35544e+007] "" SRR_RR
 SG_ SD197P_ARC : 249|2@0+ (1,0) [0|3] "" SRR_RR

BO_ 541 SrlDat198_PCSM_PDU: 8 SRR_SLR
 SG_ SrlDat198_PCSM : 0|64@1+ (1,0) [0|1.84467e+019] "" SRR_SRR

BO_ 22 SrlDat198_Prtctd_PDU: 32 SRR_SLR
 SG_ SD198P_MAC : 7|32@0+ (1,0) [0|4.29497e+009] "" SRR_SRR
 SG_ SD198P_FCnt : 39|5@0+ (1,0) [0|31] "" SRR_SRR
 SG_ SRRSLRODPTOVYawRate : 47|11@0+ (0.002,0) [0|4.094] "(rad/s)^2" SRR_SRR
 SG_ SRRSLRODPTrObjYawRate : 52|11@0- (0.002,0) [-2.048|2.046] "rad/s" SRR_SRR
 SG_ SRRSLRODPTrObjOrntn : 57|10@0- (0.01,0) [-5.12|5.11] "rad" SRR_SRR
 SG_ SRRSLRODPTODTrHtchTrFrt : 79|8@0- (0.1,0) [-12.8|12.7] "m" SRR_SRR
 SG_ SRRSLRODPTOVLgth : 87|8@0+ (0.1,0) [0|25.5] "m^2" SRR_SRR
 SG_ SRRSLRODPTOVOrntn : 95|8@0+ (0.01,0) [0|2.55] "rad^2" SRR_SRR
 SG_ SRRSLRODPTOVWdth : 103|8@0+ (0.1,0) [0|25.5] "m^2" SRR_SRR
 SG_ SRRSLRODPTrObjLgth : 111|8@0+ (0.1,0) [0|25.5] "m" SRR_SRR
 SG_ SRRSLRODPTODVhFrtAxVhHtch : 112|7@0+ (0.1,0) [0|12.7] "m" SRR_SRR
 SG_ SRRSLRODPTODTrHtchTrAx : 119|7@0+ (0.1,0) [0|12.7] "m" SRR_SRR
 SG_ SRRSLRODPTOEExistPrblty : 121|7@0+ (0.01,0) [0|1.27] "" SRR_SRR
 SG_ SRRSLRODPTOPDtnPrblty : 130|7@0+ (0.01,0) [0|1.27] "" SRR_SRR
 SG_ SRRSLRODPTrObjQlty : 139|7@0+ (1,0) [0|127] "%" SRR_SRR
 SG_ SRRSLRODPTOVDTrHtchTrAx : 148|6@0+ (0.1,0) [0|6.3] "m^2" SRR_SRR
 SG_ SRRSLRODPTOVDVhFrtAxVhHtch : 152|6@0+ (0.1,0) [0|6.3] "m^2" SRR_SRR
 SG_ SRRSLRODPTOVDTrHtchTrFrt : 158|6@0+ (0.1,0) [0|6.3] "m^2" SRR_SRR
 SG_ SRRSLRODPTrObjWdth : 162|6@0+ (0.1,0) [0|6.3] "m" SRR_SRR
 SG_ SRRSLRODPTrObjStatInfo : 169|3@0+ (1,0) [0|4] "" SRR_SRR
 SG_ SRRSLRODPTrObjExtrnInfo : 172|3@0+ (1,0) [0|7] "" SRR_SRR
 SG_ SRRSLRODPTOPDtnPrblty_Inv : 176|1@0+ (1,0) [0|1] "" SRR_SRR
 SG_ SRRSLRODPTOEExistPrblty_Inv : 177|1@0+ (1,0) [0|1] "" SRR_SRR
 SG_ SRRSLRODPTODVhFrtAxVhHtch_Inv : 178|1@0+ (1,0) [0|1] "" SRR_SRR
 SG_ SRRSLRODPTODTrHtchTrFrt_Inv : 179|1@0+ (1,0) [0|1] "" SRR_SRR
 SG_ SRRSLRODPTODTrHtchTrAx_Inv : 180|1@0+ (1,0) [0|1] "" SRR_SRR
 SG_ SRRSLRODPTrAtchdInfo : 182|2@0+ (1,0) [0|3] "" SRR_SRR
 SG_ SRRSLRODPTrObjExtrnInfo_Inv : 184|1@0+ (1,0) [0|1] "" SRR_SRR
 SG_ SRRSLRODPTOVYawRate_Inv : 185|1@0+ (1,0) [0|1] "" SRR_SRR
 SG_ SRRSLRODPTOVWdth_Inv : 186|1@0+ (1,0) [0|1] "" SRR_SRR
 SG_ SRRSLRODPTOVOrntn_Inv : 187|1@0+ (1,0) [0|1] "" SRR_SRR
 SG_ SRRSLRODPTOVLgth_Inv : 188|1@0+ (1,0) [0|1] "" SRR_SRR
 SG_ SRRSLRODPTOVDVhFrtAxVhHtch_Inv : 189|1@0+ (1,0) [0|1] "" SRR_SRR
 SG_ SRRSLRODPTOVDTrHtchTrFrt_Inv : 190|1@0+ (1,0) [0|1] "" SRR_SRR
 SG_ SRRSLRODPTOVDTrHtchTrAx_Inv : 191|1@0+ (1,0) [0|1] "" SRR_SRR
 SG_ SrlDat198_Filler : 194|32@0+ (1,0) [0|4.29497e+009] "" SRR_SRR
 SG_ SRRSLRODPTrObjYawRate_Inv : 195|1@0+ (1,0) [0|1] "" SRR_SRR
 SG_ SRRSLRODPTrObjWdth_Inv : 196|1@0+ (1,0) [0|1] "" SRR_SRR
 SG_ SRRSLRODPTrObjQlty_Inv : 197|1@0+ (1,0) [0|1] "" SRR_SRR
 SG_ SRRSLRODPTrObjOrntn_Inv : 198|1@0+ (1,0) [0|1] "" SRR_SRR
 SG_ SRRSLRODPTrObjLgth_Inv : 199|1@0+ (1,0) [0|1] "" SRR_SRR
 SG_ SrlDat198_FillerExtnd : 226|25@0+ (1,0) [0|3.35544e+007] "" SRR_SRR
 SG_ SD198P_ARC : 249|2@0+ (1,0) [0|3] "" SRR_SRR

BO_ 542 SrlDat199_PCSM_PDU: 8 SRR_SRR
 SG_ SrlDat199_PCSM : 0|64@1+ (1,0) [0|1.84467e+019] "" SRR_SLR

BA_DEF_ SG_  "SignalType" STRING ;
BA_DEF_ SG_  "SignalLongName" STRING ;
BA_DEF_ BO_  "GenMsgCycleTime" INT 0 10000;
BA_DEF_ BO_  "GenMsgSendType" ENUM "cyclicX","spontanX","cyclicIfActiveX","spontanWithDelay","cyclicAndSpontanX","cyclicAndSpontanWithDelay","spontanWithRepetition","cyclicIfActiveAndSpontanWD";
BA_DEF_ BO_  "VFrameFormat" ENUM  "StandardCAN","ExtendedCAN","reserved","reserved","reserved","reserved","reserved","reserved","reserved","reserved","reserved","reserved","reserved","reserved","StandardCAN_FD","ExtendedCAN_FD";
BA_DEF_DEF_  "SignalType" "";
BA_DEF_DEF_  "SignalLongName" "";
BA_DEF_DEF_  "GenMsgCycleTime" 0;
BA_DEF_DEF_  "GenMsgSendType" "cyclicX";
BA_DEF_DEF_  "VFrameFormat" "StandardCAN";
BA_ "VFrameFormat" BO_ 191 14;
BA_ "VFrameFormat" BO_ 190 14;
BA_ "VFrameFormat" BO_ 193 14;
BA_ "VFrameFormat" BO_ 522 14;
BA_ "GenMsgCycleTime" BO_ 2147745812 1000;
BA_ "GenMsgCycleTime" BO_ 2147745813 1000;
BA_ "GenMsgCycleTime" BO_ 2147745814 1000;
BA_ "GenMsgCycleTime" BO_ 2147745815 1000;
BA_ "GenMsgCycleTime" BO_ 2147745816 1000;
BA_ "GenMsgCycleTime" BO_ 2147745817 1000;
BA_ "GenMsgCycleTime" BO_ 1348 3500;
BA_ "VFrameFormat" BO_ 1348 14;
BA_ "GenMsgCycleTime" BO_ 1317 1000;
BA_ "VFrameFormat" BO_ 1317 14;
BA_ "GenMsgCycleTime" BO_ 1378 3500;
BA_ "VFrameFormat" BO_ 1378 14;
BA_ "GenMsgCycleTime" BO_ 1309 1000;
BA_ "VFrameFormat" BO_ 1309 14;
BA_ "VFrameFormat" BO_ 636 14;
BA_ "VFrameFormat" BO_ 179 14;
BA_ "VFrameFormat" BO_ 884 14;
BA_ "GenMsgCycleTime" BO_ 180 40;
BA_ "VFrameFormat" BO_ 180 14;
BA_ "VFrameFormat" BO_ 883 14;
BA_ "GenMsgCycleTime" BO_ 532 40;
BA_ "VFrameFormat" BO_ 532 14;
BA_ "VFrameFormat" BO_ 1326 14;
BA_ "GenMsgCycleTime" BO_ 594 100;
BA_ "VFrameFormat" BO_ 594 14;
BA_ "GenMsgCycleTime" BO_ 593 100;
BA_ "VFrameFormat" BO_ 593 14;
BA_ "VFrameFormat" BO_ 882 14;
BA_ "GenMsgCycleTime" BO_ 33 100;
BA_ "VFrameFormat" BO_ 33 14;
BA_ "VFrameFormat" BO_ 540 14;
BA_ "VFrameFormat" BO_ 23 14;
BA_ "VFrameFormat" BO_ 541 14;
BA_ "VFrameFormat" BO_ 22 14;
BA_ "VFrameFormat" BO_ 542 14;
BA_ "SignalLongName" SG_ 191 SRRSRRODPB4P_POTk5IDAuth "Short Range Radar Side Right Rear Object Detection and Processing Burst 4 Protected : Pedestrian Object Track 5 ID Authenticated";
BA_ "SignalType" SG_ 191 SRRSRRODPB4P_POTk5DynPrpAuth "ENM";
BA_ "SignalLongName" SG_ 191 SRRSRRODPB4P_POTk5DynPrpAuth "Short Range Radar Side Right Rear Object Detection and Processing Burst 4 Protected : Pedestrian Object Track 5 Dynamic Property Authenticated";
BA_ "SignalType" SG_ 191 SRRSRRODPB4P_POTk5CnfdStsAuth "ENM";
BA_ "SignalLongName" SG_ 191 SRRSRRODPB4P_POTk5CnfdStsAuth "Short Range Radar Side Right Rear Object Detection and Processing Burst 4 Protected : Pedestrian Object Track 5 Confidence Status Authenticated";
BA_ "SignalLongName" SG_ 191 SRRSRRODPB4P_BrstID "Short Range Radar Side Right Rear Object Detection and Processing Burst 4 Protected : Burst ID";
BA_ "SignalLongName" SG_ 191 SRRSRRODPB4P_POTk5InPthPotAuth "Short Range Radar Side Right Rear Object Detection and Processing Burst 4 Protected : Pedestrian Object Track 5 In Path Potential Authenticated";
BA_ "SignalLongName" SG_ 191 SRRSRRODPB4P_POTk5PoILAAuth "Short Range Radar Side Right Rear Object Detection and Processing Burst 4 Protected : Pedestrian Object Track 5 Point of Interest Lateral Acceleration Authenticated";
BA_ "SignalType" SG_ 191 SRRSRRODPB4P_POTk5MStsAuth "ENM";
BA_ "SignalLongName" SG_ 191 SRRSRRODPB4P_POTk5MStsAuth "Short Range Radar Side Right Rear Object Detection and Processing Burst 4 Protected : Pedestrian Object Track 5 Measurement Status Authenticated";
BA_ "SignalLongName" SG_ 191 SRRSRRODPB4P_POTk5PoILgAAuth "Short Range Radar Side Right Rear Object Detection and Processing Burst 4 Protected : Pedestrian Object Track 5 Point of Interest Longitudinal Acceleration Authenticated";
BA_ "SignalLongName" SG_ 191 SRRSRRODPB4P_POTk5PoILgPsAuth "Short Range Radar Side Right Rear Object Detection and Processing Burst 4 Protected : Pedestrian Object Track 5 Point of Interest Longitudinal Position Authenticated";
BA_ "SignalLongName" SG_ 191 SRRSRRODPB4P_POTk5PoILgVAuth "Short Range Radar Side Right Rear Object Detection and Processing Burst 4 Protected : Pedestrian Object Track 5 Point of Interest Longitudinal Velocity Authenticated";
BA_ "SignalLongName" SG_ 191 SRRSRRODPB4P_POTk5PoILPsAuth "Short Range Radar Side Right Rear Object Detection and Processing Burst 4 Protected : Pedestrian Object Track 5 Point of Interest Lateral Position Authenticated";
BA_ "SignalLongName" SG_ 191 SRRSRRODPB4P_POTk5PoILVAuth "Short Range Radar Side Right Rear Object Detection and Processing Burst 4 Protected : Pedestrian Object Track 5 Point of Interest Lateral Velocity Authenticated";
BA_ "SignalLongName" SG_ 191 SRRSRRODPB4P_VOTk10CICOPotAuth "Short Range Radar Side Right Rear Object Detection and Processing Burst 4 Protected : Vehicle Object Track 10 Cut In Cut Out Potential Authenticated";
BA_ "SignalType" SG_ 191 SRRSRRODPB4P_POTk5TypCnfdAuth "ENM";
BA_ "SignalLongName" SG_ 191 SRRSRRODPB4P_POTk5TypCnfdAuth "Short Range Radar Side Right Rear Object Detection and Processing Burst 4 Protected : Pedestrian Object Track 5 Type Confidence Authenticated";
BA_ "SignalType" SG_ 191 SRRSRRODPB4P_POTk5TypAuth "ENM";
BA_ "SignalLongName" SG_ 191 SRRSRRODPB4P_POTk5TypAuth "Short Range Radar Side Right Rear Object Detection and Processing Burst 4 Protected : Pedestrian Object Track 5 Type Authenticated";
BA_ "SignalType" SG_ 191 SRRSRRODPB4P_VOTk10DynPrpStAuth "ENM";
BA_ "SignalLongName" SG_ 191 SRRSRRODPB4P_VOTk10DynPrpStAuth "Short Range Radar Side Right Rear Object Detection and Processing Burst 4 Protected : Vehicle Object Track 10 Dynamic Property Status Authenticated";
BA_ "SignalType" SG_ 191 SRRSRRODPB4P_VOTk10DynPrpAuth "ENM";
BA_ "SignalLongName" SG_ 191 SRRSRRODPB4P_VOTk10DynPrpAuth "Short Range Radar Side Right Rear Object Detection and Processing Burst 4 Protected : Vehicle Object Track 10 Dynamic Property Authenticated";
BA_ "SignalType" SG_ 191 SRRSRRODPB4P_VOTk10CnfdStsAuth "ENM";
BA_ "SignalLongName" SG_ 191 SRRSRRODPB4P_VOTk10CnfdStsAuth "Short Range Radar Side Right Rear Object Detection and Processing Burst 4 Protected : Vehicle Object Track 10 Confidence Status Authenticated";
BA_ "SignalType" SG_ 191 SRRSRRODPB4P_VOTk10MStsAuth "ENM";
BA_ "SignalLongName" SG_ 191 SRRSRRODPB4P_VOTk10MStsAuth "Short Range Radar Side Right Rear Object Detection and Processing Burst 4 Protected : Vehicle Object Track 10 Measurement Status Authenticated";
BA_ "SignalLongName" SG_ 191 SRRSRRODPB4P_VOTk10IDAuth "Short Range Radar Side Right Rear Object Detection and Processing Burst 4 Protected : Vehicle Object Track 10 ID Authenticated";
BA_ "SignalLongName" SG_ 191 SRRSRRODPB4P_VOTk10PoILAAuth "Short Range Radar Side Right Rear Object Detection and Processing Burst 4 Protected : Vehicle Object Track 10 Point of Interest Lateral Acceleration Authenticated";
BA_ "SignalLongName" SG_ 191 SRRSRRODPB4P_VOTk10PoILgAAuth "Short Range Radar Side Right Rear Object Detection and Processing Burst 4 Protected : Vehicle Object Track 10 Point of Interest Longitudinal Acceleration Authenticated";
BA_ "SignalLongName" SG_ 191 SRRSRRODPB4P_VOTk10PoILgPsAuth "Short Range Radar Side Right Rear Object Detection and Processing Burst 4 Protected : Vehicle Object Track 10 Point of Interest Longitudinal Position Authenticated";
BA_ "SignalLongName" SG_ 191 SRRSRRODPB4P_VOTk10PoILgPsCAuth "Short Range Radar Side Right Rear Object Detection and Processing Burst 4 Protected : Vehicle Object Track 10 Point of Interest Longitudinal Position Covariance Authenticated";
BA_ "SignalLongName" SG_ 191 SRRSRRODPB4P_VOTk10PoILgthAuth "Short Range Radar Side Right Rear Object Detection and Processing Burst 4 Protected : Vehicle Object Track 10 Point of Interest Length Authenticated";
BA_ "SignalLongName" SG_ 191 SRRSRRODPB4P_VOTk10PoILgVAuth "Short Range Radar Side Right Rear Object Detection and Processing Burst 4 Protected : Vehicle Object Track 10 Point of Interest Longitudinal Velocity Authenticated";
BA_ "SignalLongName" SG_ 191 SRRSRRODPB4P_VOTk10PoILgVCAuth "Short Range Radar Side Right Rear Object Detection and Processing Burst 4 Protected : Vehicle Object Track 10 Point of Interest Longitudinal Velocity Covariance Authenticated";
BA_ "SignalLongName" SG_ 191 SRRSRRODPB4P_VOTk10PoILPsAuth "Short Range Radar Side Right Rear Object Detection and Processing Burst 4 Protected : Vehicle Object Track 10 Point of Interest Lateral Position Authenticated";
BA_ "SignalLongName" SG_ 191 SRRSRRODPB4P_VOTk10PoILPsCAuth "Short Range Radar Side Right Rear Object Detection and Processing Burst 4 Protected : Vehicle Object Track 10 Point of Interest Lateral Position Covariance Authenticated";
BA_ "SignalLongName" SG_ 191 SRRSRRODPB4P_VOTk10PoILVAuth "Short Range Radar Side Right Rear Object Detection and Processing Burst 4 Protected : Vehicle Object Track 10 Point of Interest Lateral Velocity Authenticated";
BA_ "SignalLongName" SG_ 191 SRRSRRODPB4P_VOTk10PoILVCAuth "Short Range Radar Side Right Rear Object Detection and Processing Burst 4 Protected : Vehicle Object Track 10 Point of Interest Lateral Velocity Covariance Authenticated";
BA_ "SignalType" SG_ 191 SRRSRRODPB4P_VOTk10TypCnfdAuth "ENM";
BA_ "SignalLongName" SG_ 191 SRRSRRODPB4P_VOTk10TypCnfdAuth "Short Range Radar Side Right Rear Object Detection and Processing Burst 4 Protected : Vehicle Object Track 10 Type Confidence Authenticated";
BA_ "SignalType" SG_ 191 SRRSRRODPB4P_VOTk8CnfdStsAuth "ENM";
BA_ "SignalLongName" SG_ 191 SRRSRRODPB4P_VOTk8CnfdStsAuth "Short Range Radar Side Right Rear Object Detection and Processing Burst 4 Protected : Vehicle Object Track 8 Confidence Status Authenticated";
BA_ "SignalLongName" SG_ 191 SRRSRRODPB4P_VOTk8CICOPotAuth "Short Range Radar Side Right Rear Object Detection and Processing Burst 4 Protected : Vehicle Object Track 8 Cut In Cut Out Potential Authenticated";
BA_ "SignalLongName" SG_ 191 SRRSRRODPB4P_VOTk8IDAuth "Short Range Radar Side Right Rear Object Detection and Processing Burst 4 Protected : Vehicle Object Track 8 ID Authenticated";
BA_ "SignalType" SG_ 191 SRRSRRODPB4P_VOTk8DynPrpStsAuth "ENM";
BA_ "SignalLongName" SG_ 191 SRRSRRODPB4P_VOTk8DynPrpStsAuth "Short Range Radar Side Right Rear Object Detection and Processing Burst 4 Protected : Vehicle Object Track 8 Dynamic Property Status Authenticated";
BA_ "SignalType" SG_ 191 SRRSRRODPB4P_VOTk8DynPrpAuth "ENM";
BA_ "SignalLongName" SG_ 191 SRRSRRODPB4P_VOTk8DynPrpAuth "Short Range Radar Side Right Rear Object Detection and Processing Burst 4 Protected : Vehicle Object Track 8 Dynamic Property Authenticated";
BA_ "SignalLongName" SG_ 191 SRRSRRODPB4P_VOTk8PoILAAuth "Short Range Radar Side Right Rear Object Detection and Processing Burst 4 Protected : Vehicle Object Track 8 Point of Interest Lateral Acceleration Authenticated";
BA_ "SignalType" SG_ 191 SRRSRRODPB4P_VOTk8MStsAuth "ENM";
BA_ "SignalLongName" SG_ 191 SRRSRRODPB4P_VOTk8MStsAuth "Short Range Radar Side Right Rear Object Detection and Processing Burst 4 Protected : Vehicle Object Track 8 Measurement Status Authenticated";
BA_ "SignalLongName" SG_ 191 SRRSRRODPB4P_VOTk8PoILgAAuth "Short Range Radar Side Right Rear Object Detection and Processing Burst 4 Protected : Vehicle Object Track 8 Point of Interest Longitudinal Acceleration Authenticated";
BA_ "SignalLongName" SG_ 191 SRRSRRODPB4P_VOTk8PoILgPsAuth "Short Range Radar Side Right Rear Object Detection and Processing Burst 4 Protected : Vehicle Object Track 8 Point of Interest Longitudinal Position Authenticated";
BA_ "SignalLongName" SG_ 191 SRRSRRODPB4P_VOTk8PoILgPsCAuth "Short Range Radar Side Right Rear Object Detection and Processing Burst 4 Protected : Vehicle Object Track 8 Point of Interest Longitudinal Position Covariance Authenticated";
BA_ "SignalLongName" SG_ 191 SRRSRRODPB4P_VOTk8PoILgVAuth "Short Range Radar Side Right Rear Object Detection and Processing Burst 4 Protected : Vehicle Object Track 8 Point of Interest Longitudinal Velocity Authenticated";
BA_ "SignalLongName" SG_ 191 SRRSRRODPB4P_VOTk8PoILgVCAuth "Short Range Radar Side Right Rear Object Detection and Processing Burst 4 Protected : Vehicle Object Track 8 Point of Interest Longitudinal Velocity Covariance Authenticated";
BA_ "SignalLongName" SG_ 191 SRRSRRODPB4P_VOTk8PoILPsAuth "Short Range Radar Side Right Rear Object Detection and Processing Burst 4 Protected : Vehicle Object Track 8 Point of Interest Lateral Position Authenticated";
BA_ "SignalLongName" SG_ 191 SRRSRRODPB4P_VOTk8PoILPsCAuth "Short Range Radar Side Right Rear Object Detection and Processing Burst 4 Protected : Vehicle Object Track 8 Point of Interest Lateral Position Covariance Authenticated";
BA_ "SignalLongName" SG_ 191 SRRSRRODPB4P_VOTk8PoILVAuth "Short Range Radar Side Right Rear Object Detection and Processing Burst 4 Protected : Vehicle Object Track 8 Point of Interest Lateral Velocity Authenticated";
BA_ "SignalLongName" SG_ 191 SRRSRRODPB4P_VOTk8PoILVCAuth "Short Range Radar Side Right Rear Object Detection and Processing Burst 4 Protected : Vehicle Object Track 8 Point of Interest Lateral Velocity Covariance Authenticated";
BA_ "SignalLongName" SG_ 191 SRRSRRODPB4P_VOTk9CICOPotAuth "Short Range Radar Side Right Rear Object Detection and Processing Burst 4 Protected : Vehicle Object Track 9 Cut In Cut Out Potential Authenticated";
BA_ "SignalType" SG_ 191 SRRSRRODPB4P_VOTk8TypCnfdAuth "ENM";
BA_ "SignalLongName" SG_ 191 SRRSRRODPB4P_VOTk8TypCnfdAuth "Short Range Radar Side Right Rear Object Detection and Processing Burst 4 Protected : Vehicle Object Track 8 Type Confidence Authenticated";
BA_ "SignalType" SG_ 191 SRRSRRODPB4P_VOTk9DynPrpStsAuth "ENM";
BA_ "SignalLongName" SG_ 191 SRRSRRODPB4P_VOTk9DynPrpStsAuth "Short Range Radar Side Right Rear Object Detection and Processing Burst 4 Protected : Vehicle Object Track 9 Dynamic Property Status Authenticated";
BA_ "SignalType" SG_ 191 SRRSRRODPB4P_VOTk9DynPrpAuth "ENM";
BA_ "SignalLongName" SG_ 191 SRRSRRODPB4P_VOTk9DynPrpAuth "Short Range Radar Side Right Rear Object Detection and Processing Burst 4 Protected : Vehicle Object Track 9 Dynamic Property Authenticated";
BA_ "SignalType" SG_ 191 SRRSRRODPB4P_VOTk9CnfdStsAuth "ENM";
BA_ "SignalLongName" SG_ 191 SRRSRRODPB4P_VOTk9CnfdStsAuth "Short Range Radar Side Right Rear Object Detection and Processing Burst 4 Protected : Vehicle Object Track 9 Confidence Status Authenticated";
BA_ "SignalType" SG_ 191 SRRSRRODPB4P_VOTk9MStsAuth "ENM";
BA_ "SignalLongName" SG_ 191 SRRSRRODPB4P_VOTk9MStsAuth "Short Range Radar Side Right Rear Object Detection and Processing Burst 4 Protected : Vehicle Object Track 9 Measurement Status Authenticated";
BA_ "SignalLongName" SG_ 191 SRRSRRODPB4P_VOTk9IDAuth "Short Range Radar Side Right Rear Object Detection and Processing Burst 4 Protected : Vehicle Object Track 9 ID Authenticated";
BA_ "SignalLongName" SG_ 191 SRRSRRODPB4P_VOTk9PoILAAuth "Short Range Radar Side Right Rear Object Detection and Processing Burst 4 Protected : Vehicle Object Track 9 Point of Interest Lateral Acceleration Authenticated";
BA_ "SignalLongName" SG_ 191 SRRSRRODPB4P_VOTk9PoILgAAuth "Short Range Radar Side Right Rear Object Detection and Processing Burst 4 Protected : Vehicle Object Track 9 Point of Interest Longitudinal Acceleration Authenticated";
BA_ "SignalLongName" SG_ 191 SRRSRRODPB4P_VOTk9PoILgPsAuth "Short Range Radar Side Right Rear Object Detection and Processing Burst 4 Protected : Vehicle Object Track 9 Point of Interest Longitudinal Position Authenticated";
BA_ "SignalLongName" SG_ 191 SRRSRRODPB4P_VOTk9PoILgPsCAuth "Short Range Radar Side Right Rear Object Detection and Processing Burst 4 Protected : Vehicle Object Track 9 Point of Interest Longitudinal Position Covariance Authenticated";
BA_ "SignalLongName" SG_ 191 SRRSRRODPB4P_VOTk9PoILgthAuth "Short Range Radar Side Right Rear Object Detection and Processing Burst 4 Protected : Vehicle Object Track 9 Point of Interest Length Authenticated";
BA_ "SignalLongName" SG_ 191 SRRSRRODPB4P_VOTk9PoILgVAuth "Short Range Radar Side Right Rear Object Detection and Processing Burst 4 Protected : Vehicle Object Track 9 Point of Interest Longitudinal Velocity Authenticated";
BA_ "SignalLongName" SG_ 191 SRRSRRODPB4P_VOTk9PoILgVCAuth "Short Range Radar Side Right Rear Object Detection and Processing Burst 4 Protected : Vehicle Object Track 9 Point of Interest Longitudinal Velocity Covariance Authenticated";
BA_ "SignalLongName" SG_ 191 SRRSRRODPB4P_VOTk9PoILPsAuth "Short Range Radar Side Right Rear Object Detection and Processing Burst 4 Protected : Vehicle Object Track 9 Point of Interest Lateral Position Authenticated";
BA_ "SignalLongName" SG_ 191 SRRSRRODPB4P_VOTk9PoILPsCAuth "Short Range Radar Side Right Rear Object Detection and Processing Burst 4 Protected : Vehicle Object Track 9 Point of Interest Lateral Position Covariance Authenticated";
BA_ "SignalLongName" SG_ 191 SRRSRRODPB4P_VOTk9PoILVAuth "Short Range Radar Side Right Rear Object Detection and Processing Burst 4 Protected : Vehicle Object Track 9 Point of Interest Lateral Velocity Authenticated";
BA_ "SignalLongName" SG_ 191 SRRSRRODPB4P_VOTk9PoILVCAuth "Short Range Radar Side Right Rear Object Detection and Processing Burst 4 Protected : Vehicle Object Track 9 Point of Interest Lateral Velocity Covariance Authenticated";
BA_ "SignalType" SG_ 191 SRRSRRODPB4P_VOTk9TypCnfdAuth "ENM";
BA_ "SignalLongName" SG_ 191 SRRSRRODPB4P_VOTk9TypCnfdAuth "Short Range Radar Side Right Rear Object Detection and Processing Burst 4 Protected : Vehicle Object Track 9 Type Confidence Authenticated";
BA_ "SignalLongName" SG_ 191 SRRSRRODPB4P_Filler "Short Range Radar Side Right Rear Object Detection and Processing Burst 4 Protected : Filler";
BA_ "SignalLongName" SG_ 190 SRRSRRODPB5P_IOTk10IDAuth "Short Range Radar Side Right Rear Object Detection and Processing Burst 5 Protected : Infrastructure Object Track 10 ID Authenticated";
BA_ "SignalType" SG_ 190 SRRSRRODPB5P_IOTk10ElvtnAuth "ENM";
BA_ "SignalLongName" SG_ 190 SRRSRRODPB5P_IOTk10ElvtnAuth "Short Range Radar Side Right Rear Object Detection and Processing Burst 5 Protected : Infrastructure Object Track 10 Elevation Authenticated";
BA_ "SignalType" SG_ 190 SRRSRRODPB5P_IOTk10CnfdStsAuth "ENM";
BA_ "SignalLongName" SG_ 190 SRRSRRODPB5P_IOTk10CnfdStsAuth "Short Range Radar Side Right Rear Object Detection and Processing Burst 5 Protected : Infrastructure Object Track 10 Confidence Status Authenticated";
BA_ "SignalLongName" SG_ 190 SRRSRRODPB5P_BrstID "Short Range Radar Side Right Rear Object Detection and Processing Burst 5 Protected : Burst ID";
BA_ "SignalLongName" SG_ 190 SRRSRRODPB5P_IOTk10PolLgPsAuth "Short Range Radar Side Right Rear Object Detection and Processing Burst 5 Protected : Infrastructure Object Track 10 Point of Interest Longitudinal Position Authenticated";
BA_ "SignalType" SG_ 190 SRRSRRODPB5P_IOTk10MStsAuth "ENM";
BA_ "SignalLongName" SG_ 190 SRRSRRODPB5P_IOTk10MStsAuth "Short Range Radar Side Right Rear Object Detection and Processing Burst 5 Protected : Infrastructure Object Track 10 Measurement Status Authenticated";
BA_ "SignalType" SG_ 190 SRRSRRODPB5P_IOTk1CnfdStsAuth "ENM";
BA_ "SignalLongName" SG_ 190 SRRSRRODPB5P_IOTk1CnfdStsAuth "Short Range Radar Side Right Rear Object Detection and Processing Burst 5 Protected : Infrastructure Object Track 1 Confidence Status Authenticated";
BA_ "SignalType" SG_ 190 SRRSRRODPB5P_IOTk10TypCnfdAuth "ENM";
BA_ "SignalLongName" SG_ 190 SRRSRRODPB5P_IOTk10TypCnfdAuth "Short Range Radar Side Right Rear Object Detection and Processing Burst 5 Protected : Infrastructure Object Track 10 Type Confidence Authenticated";
BA_ "SignalType" SG_ 190 SRRSRRODPB5P_IOTk10TypAuth "ENM";
BA_ "SignalLongName" SG_ 190 SRRSRRODPB5P_IOTk10TypAuth "Short Range Radar Side Right Rear Object Detection and Processing Burst 5 Protected : Infrastructure Object Track 10 Type Authenticated";
BA_ "SignalLongName" SG_ 190 SRRSRRODPB5P_IOTk1IDAuth "Short Range Radar Side Right Rear Object Detection and Processing Burst 5 Protected : Infrastructure Object Track 1 ID Authenticated";
BA_ "SignalType" SG_ 190 SRRSRRODPB5P_IOTk1ElvtnAuth "ENM";
BA_ "SignalLongName" SG_ 190 SRRSRRODPB5P_IOTk1ElvtnAuth "Short Range Radar Side Right Rear Object Detection and Processing Burst 5 Protected : Infrastructure Object Track 1 Elevation Authenticated";
BA_ "SignalLongName" SG_ 190 SRRSRRODPB5P_IOTk1PoILgPsAuth "Short Range Radar Side Right Rear Object Detection and Processing Burst 5 Protected : Infrastructure Object Track 1 Point of Interest Longitudinal Position Authenticated";
BA_ "SignalType" SG_ 190 SRRSRRODPB5P_IOTk1MStsAuth "ENM";
BA_ "SignalLongName" SG_ 190 SRRSRRODPB5P_IOTk1MStsAuth "Short Range Radar Side Right Rear Object Detection and Processing Burst 5 Protected : Infrastructure Object Track 1 Measurement Status Authenticated";
BA_ "SignalType" SG_ 190 SRRSRRODPB5P_IOTk1TypAuth "ENM";
BA_ "SignalLongName" SG_ 190 SRRSRRODPB5P_IOTk1TypAuth "Short Range Radar Side Right Rear Object Detection and Processing Burst 5 Protected : Infrastructure Object Track 1 Type Authenticated";
BA_ "SignalType" SG_ 190 SRRSRRODPB5P_IOTk2ElvtnAuth "ENM";
BA_ "SignalLongName" SG_ 190 SRRSRRODPB5P_IOTk2ElvtnAuth "Short Range Radar Side Right Rear Object Detection and Processing Burst 5 Protected : Infrastructure Object Track 2 Elevation Authenticated";
BA_ "SignalType" SG_ 190 SRRSRRODPB5P_IOTk2CnfdStsAuth "ENM";
BA_ "SignalLongName" SG_ 190 SRRSRRODPB5P_IOTk2CnfdStsAuth "Short Range Radar Side Right Rear Object Detection and Processing Burst 5 Protected : Infrastructure Object Track 2 Confidence Status Authenticated";
BA_ "SignalType" SG_ 190 SRRSRRODPB5P_IOTk1TypCnfdAuth "ENM";
BA_ "SignalLongName" SG_ 190 SRRSRRODPB5P_IOTk1TypCnfdAuth "Short Range Radar Side Right Rear Object Detection and Processing Burst 5 Protected : Infrastructure Object Track 1 Type Confidence Authenticated";
BA_ "SignalType" SG_ 190 SRRSRRODPB5P_IOTk2MStsAuth "ENM";
BA_ "SignalLongName" SG_ 190 SRRSRRODPB5P_IOTk2MStsAuth "Short Range Radar Side Right Rear Object Detection and Processing Burst 5 Protected : Infrastructure Object Track 2 Measurement Status Authenticated";
BA_ "SignalLongName" SG_ 190 SRRSRRODPB5P_IOTk2IDAuth "Short Range Radar Side Right Rear Object Detection and Processing Burst 5 Protected : Infrastructure Object Track 2 ID Authenticated";
BA_ "SignalLongName" SG_ 190 SRRSRRODPB5P_IOTk2PolLgPsAuth "Short Range Radar Side Right Rear Object Detection and Processing Burst 5 Protected : Infrastructure Object Track 2 Point of Interest Longitudinal Position Authenticated";
BA_ "SignalType" SG_ 190 SRRSRRODPB5P_IOTk2TypCnfdAuth "ENM";
BA_ "SignalLongName" SG_ 190 SRRSRRODPB5P_IOTk2TypCnfdAuth "Short Range Radar Side Right Rear Object Detection and Processing Burst 5 Protected : Infrastructure Object Track 2 Type Confidence Authenticated";
BA_ "SignalType" SG_ 190 SRRSRRODPB5P_IOTk2TypAuth "ENM";
BA_ "SignalLongName" SG_ 190 SRRSRRODPB5P_IOTk2TypAuth "Short Range Radar Side Right Rear Object Detection and Processing Burst 5 Protected : Infrastructure Object Track 2 Type Authenticated";
BA_ "SignalLongName" SG_ 190 SRRSRRODPB5P_IOTk3IDAuth "Short Range Radar Side Right Rear Object Detection and Processing Burst 5 Protected : Infrastructure Object Track 3 ID Authenticated";
BA_ "SignalType" SG_ 190 SRRSRRODPB5P_IOTk3ElvtnAuth "ENM";
BA_ "SignalLongName" SG_ 190 SRRSRRODPB5P_IOTk3ElvtnAuth "Short Range Radar Side Right Rear Object Detection and Processing Burst 5 Protected : Infrastructure Object Track 3 Elevation Authenticated";
BA_ "SignalType" SG_ 190 SRRSRRODPB5P_IOTk3CnfdStsAuth "ENM";
BA_ "SignalLongName" SG_ 190 SRRSRRODPB5P_IOTk3CnfdStsAuth "Short Range Radar Side Right Rear Object Detection and Processing Burst 5 Protected : Infrastructure Object Track 3 Confidence Status Authenticated";
BA_ "SignalLongName" SG_ 190 SRRSRRODPB5P_IOTk3PolLgPsAuth "Short Range Radar Side Right Rear Object Detection and Processing Burst 5 Protected : Infrastructure Object Track 3 Point of Interest Longitudinal Position Authenticated";
BA_ "SignalType" SG_ 190 SRRSRRODPB5P_IOTk3MStsAuth "ENM";
BA_ "SignalLongName" SG_ 190 SRRSRRODPB5P_IOTk3MStsAuth "Short Range Radar Side Right Rear Object Detection and Processing Burst 5 Protected : Infrastructure Object Track 3 Measurement Status Authenticated";
BA_ "SignalType" SG_ 190 SRRSRRODPB5P_IOTk4CnfdStsAuth "ENM";
BA_ "SignalLongName" SG_ 190 SRRSRRODPB5P_IOTk4CnfdStsAuth "Short Range Radar Side Right Rear Object Detection and Processing Burst 5 Protected : Infrastructure Object Track 4 Confidence Status Authenticated";
BA_ "SignalType" SG_ 190 SRRSRRODPB5P_IOTk3TypCnfdAuth "ENM";
BA_ "SignalLongName" SG_ 190 SRRSRRODPB5P_IOTk3TypCnfdAuth "Short Range Radar Side Right Rear Object Detection and Processing Burst 5 Protected : Infrastructure Object Track 3 Type Confidence Authenticated";
BA_ "SignalType" SG_ 190 SRRSRRODPB5P_IOTk3TypAuth "ENM";
BA_ "SignalLongName" SG_ 190 SRRSRRODPB5P_IOTk3TypAuth "Short Range Radar Side Right Rear Object Detection and Processing Burst 5 Protected : Infrastructure Object Track 3 Type Authenticated";
BA_ "SignalLongName" SG_ 190 SRRSRRODPB5P_IOTk4IDAuth "Short Range Radar Side Right Rear Object Detection and Processing Burst 5 Protected : Infrastructure Object Track 4 ID Authenticated";
BA_ "SignalType" SG_ 190 SRRSRRODPB5P_IOTk4ElvtnAuth "ENM";
BA_ "SignalLongName" SG_ 190 SRRSRRODPB5P_IOTk4ElvtnAuth "Short Range Radar Side Right Rear Object Detection and Processing Burst 5 Protected : Infrastructure Object Track 4 Elevation Authenticated";
BA_ "SignalLongName" SG_ 190 SRRSRRODPB5P_IOTk4PolLgPsAuth "Short Range Radar Side Right Rear Object Detection and Processing Burst 5 Protected : Infrastructure Object Track 4 Point of Interest Longitudinal Position Authenticated";
BA_ "SignalType" SG_ 190 SRRSRRODPB5P_IOTk4MStsAuth "ENM";
BA_ "SignalLongName" SG_ 190 SRRSRRODPB5P_IOTk4MStsAuth "Short Range Radar Side Right Rear Object Detection and Processing Burst 5 Protected : Infrastructure Object Track 4 Measurement Status Authenticated";
BA_ "SignalType" SG_ 190 SRRSRRODPB5P_IOTk4TypAuth "ENM";
BA_ "SignalLongName" SG_ 190 SRRSRRODPB5P_IOTk4TypAuth "Short Range Radar Side Right Rear Object Detection and Processing Burst 5 Protected : Infrastructure Object Track 4 Type Authenticated";
BA_ "SignalLongName" SG_ 190 SRRSRRODPB5P_IOTk5IDAuth "Short Range Radar Side Right Rear Object Detection and Processing Burst 5 Protected : Infrastructure Object Track 5 ID Authenticated";
BA_ "SignalType" SG_ 190 SRRSRRODPB5P_IOTk5ElvtnAuth "ENM";
BA_ "SignalLongName" SG_ 190 SRRSRRODPB5P_IOTk5ElvtnAuth "Short Range Radar Side Right Rear Object Detection and Processing Burst 5 Protected : Infrastructure Object Track 5 Elevation Authenticated";
BA_ "SignalType" SG_ 190 SRRSRRODPB5P_IOTk5CnfdStsAuth "ENM";
BA_ "SignalLongName" SG_ 190 SRRSRRODPB5P_IOTk5CnfdStsAuth "Short Range Radar Side Right Rear Object Detection and Processing Burst 5 Protected : Infrastructure Object Track 5 Confidence Status Authenticated";
BA_ "SignalType" SG_ 190 SRRSRRODPB5P_IOTk4TypCnfdAuth "ENM";
BA_ "SignalLongName" SG_ 190 SRRSRRODPB5P_IOTk4TypCnfdAuth "Short Range Radar Side Right Rear Object Detection and Processing Burst 5 Protected : Infrastructure Object Track 4 Type Confidence Authenticated";
BA_ "SignalType" SG_ 190 SRRSRRODPB5P_IOTk5MStsAuth "ENM";
BA_ "SignalLongName" SG_ 190 SRRSRRODPB5P_IOTk5MStsAuth "Short Range Radar Side Right Rear Object Detection and Processing Burst 5 Protected : Infrastructure Object Track 5 Measurement Status Authenticated";
BA_ "SignalLongName" SG_ 190 SRRSRRODPB5P_IOTk5PolLgPsAuth "Short Range Radar Side Right Rear Object Detection and Processing Burst 5 Protected : Infrastructure Object Track 5 Point of Interest Longitudinal Position Authenticated";
BA_ "SignalType" SG_ 190 SRRSRRODPB5P_IOTk5TypCnfdAuth "ENM";
BA_ "SignalLongName" SG_ 190 SRRSRRODPB5P_IOTk5TypCnfdAuth "Short Range Radar Side Right Rear Object Detection and Processing Burst 5 Protected : Infrastructure Object Track 5 Type Confidence Authenticated";
BA_ "SignalType" SG_ 190 SRRSRRODPB5P_IOTk5TypAuth "ENM";
BA_ "SignalLongName" SG_ 190 SRRSRRODPB5P_IOTk5TypAuth "Short Range Radar Side Right Rear Object Detection and Processing Burst 5 Protected : Infrastructure Object Track 5 Type Authenticated";
BA_ "SignalLongName" SG_ 190 SRRSRRODPB5P_IOTk6IDAuth "Short Range Radar Side Right Rear Object Detection and Processing Burst 5 Protected : Infrastructure Object Track 6 ID Authenticated";
BA_ "SignalType" SG_ 190 SRRSRRODPB5P_IOTk6ElvtnAuth "ENM";
BA_ "SignalLongName" SG_ 190 SRRSRRODPB5P_IOTk6ElvtnAuth "Short Range Radar Side Right Rear Object Detection and Processing Burst 5 Protected : Infrastructure Object Track 6 Elevation Authenticated";
BA_ "SignalType" SG_ 190 SRRSRRODPB5P_IOTk6CnfdStsAuth "ENM";
BA_ "SignalLongName" SG_ 190 SRRSRRODPB5P_IOTk6CnfdStsAuth "Short Range Radar Side Right Rear Object Detection and Processing Burst 5 Protected : Infrastructure Object Track 6 Confidence Status Authenticated";
BA_ "SignalLongName" SG_ 190 SRRSRRODPB5P_IOTk6PolLgPsAuth "Short Range Radar Side Right Rear Object Detection and Processing Burst 5 Protected : Infrastructure Object Track 6 Point of Interest Longitudinal Position Authenticated";
BA_ "SignalType" SG_ 190 SRRSRRODPB5P_IOTk6MStsAuth "ENM";
BA_ "SignalLongName" SG_ 190 SRRSRRODPB5P_IOTk6MStsAuth "Short Range Radar Side Right Rear Object Detection and Processing Burst 5 Protected : Infrastructure Object Track 6 Measurement Status Authenticated";
BA_ "SignalType" SG_ 190 SRRSRRODPB5P_IOTk7ElvtnAuth "ENM";
BA_ "SignalLongName" SG_ 190 SRRSRRODPB5P_IOTk7ElvtnAuth "Short Range Radar Side Right Rear Object Detection and Processing Burst 5 Protected : Infrastructure Object Track 7 Elevation Authenticated";
BA_ "SignalType" SG_ 190 SRRSRRODPB5P_IOTk7CnfdStsAuth "ENM";
BA_ "SignalLongName" SG_ 190 SRRSRRODPB5P_IOTk7CnfdStsAuth "Short Range Radar Side Right Rear Object Detection and Processing Burst 5 Protected : Infrastructure Object Track 7 Confidence Status Authenticated";
BA_ "SignalType" SG_ 190 SRRSRRODPB5P_IOTk6TypCnfdAuth "ENM";
BA_ "SignalLongName" SG_ 190 SRRSRRODPB5P_IOTk6TypCnfdAuth "Short Range Radar Side Right Rear Object Detection and Processing Burst 5 Protected : Infrastructure Object Track 6 Type Confidence Authenticated";
BA_ "SignalType" SG_ 190 SRRSRRODPB5P_IOTk6TypAuth "ENM";
BA_ "SignalLongName" SG_ 190 SRRSRRODPB5P_IOTk6TypAuth "Short Range Radar Side Right Rear Object Detection and Processing Burst 5 Protected : Infrastructure Object Track 6 Type Authenticated";
BA_ "SignalLongName" SG_ 190 SRRSRRODPB5P_IOTk7IDAuth "Short Range Radar Side Right Rear Object Detection and Processing Burst 5 Protected : Infrastructure Object Track 7 ID Authenticated";
BA_ "SignalLongName" SG_ 190 SRRSRRODPB5P_IOTk7PolLgPsAuth "Short Range Radar Side Right Rear Object Detection and Processing Burst 5 Protected : Infrastructure Object Track 7 Point of Interest Longitudinal Position Authenticated";
BA_ "SignalType" SG_ 190 SRRSRRODPB5P_IOTk7MStsAuth "ENM";
BA_ "SignalLongName" SG_ 190 SRRSRRODPB5P_IOTk7MStsAuth "Short Range Radar Side Right Rear Object Detection and Processing Burst 5 Protected : Infrastructure Object Track 7 Measurement Status Authenticated";
BA_ "SignalType" SG_ 190 SRRSRRODPB5P_IOTk7TypAuth "ENM";
BA_ "SignalLongName" SG_ 190 SRRSRRODPB5P_IOTk7TypAuth "Short Range Radar Side Right Rear Object Detection and Processing Burst 5 Protected : Infrastructure Object Track 7 Type Authenticated";
BA_ "SignalLongName" SG_ 190 SRRSRRODPB5P_IOTk8IDAuth "Short Range Radar Side Right Rear Object Detection and Processing Burst 5 Protected : Infrastructure Object Track 8 ID Authenticated";
BA_ "SignalType" SG_ 190 SRRSRRODPB5P_IOTk8ElvtnAuth "ENM";
BA_ "SignalLongName" SG_ 190 SRRSRRODPB5P_IOTk8ElvtnAuth "Short Range Radar Side Right Rear Object Detection and Processing Burst 5 Protected : Infrastructure Object Track 8 Elevation Authenticated";
BA_ "SignalType" SG_ 190 SRRSRRODPB5P_IOTk8CnfdStsAuth "ENM";
BA_ "SignalLongName" SG_ 190 SRRSRRODPB5P_IOTk8CnfdStsAuth "Short Range Radar Side Right Rear Object Detection and Processing Burst 5 Protected : Infrastructure Object Track 8 Confidence Status Authenticated";
BA_ "SignalType" SG_ 190 SRRSRRODPB5P_IOTk7TypCnfdAuth "ENM";
BA_ "SignalLongName" SG_ 190 SRRSRRODPB5P_IOTk7TypCnfdAuth "Short Range Radar Side Right Rear Object Detection and Processing Burst 5 Protected : Infrastructure Object Track 7 Type Confidence Authenticated";
BA_ "SignalLongName" SG_ 190 SRRSRRODPB5P_IOTk8PolLgPsAuth "Short Range Radar Side Right Rear Object Detection and Processing Burst 5 Protected : Infrastructure Object Track 8 Point of Interest Longitudinal Position Authenticated";
BA_ "SignalType" SG_ 190 SRRSRRODPB5P_IOTk8MStsAuth "ENM";
BA_ "SignalLongName" SG_ 190 SRRSRRODPB5P_IOTk8MStsAuth "Short Range Radar Side Right Rear Object Detection and Processing Burst 5 Protected : Infrastructure Object Track 8 Measurement Status Authenticated";
BA_ "SignalType" SG_ 190 SRRSRRODPB5P_IOTk9CnfdStsAuth "ENM";
BA_ "SignalLongName" SG_ 190 SRRSRRODPB5P_IOTk9CnfdStsAuth "Short Range Radar Side Right Rear Object Detection and Processing Burst 5 Protected : Infrastructure Object Track 9 Confidence Status Authenticated";
BA_ "SignalType" SG_ 190 SRRSRRODPB5P_IOTk8TypCnfdAuth "ENM";
BA_ "SignalLongName" SG_ 190 SRRSRRODPB5P_IOTk8TypCnfdAuth "Short Range Radar Side Right Rear Object Detection and Processing Burst 5 Protected : Infrastructure Object Track 8 Type Confidence Authenticated";
BA_ "SignalType" SG_ 190 SRRSRRODPB5P_IOTk8TypAuth "ENM";
BA_ "SignalLongName" SG_ 190 SRRSRRODPB5P_IOTk8TypAuth "Short Range Radar Side Right Rear Object Detection and Processing Burst 5 Protected : Infrastructure Object Track 8 Type Authenticated";
BA_ "SignalLongName" SG_ 190 SRRSRRODPB5P_IOTk9IDAuth "Short Range Radar Side Right Rear Object Detection and Processing Burst 5 Protected : Infrastructure Object Track 9 ID Authenticated";
BA_ "SignalType" SG_ 190 SRRSRRODPB5P_IOTk9ElvtnAuth "ENM";
BA_ "SignalLongName" SG_ 190 SRRSRRODPB5P_IOTk9ElvtnAuth "Short Range Radar Side Right Rear Object Detection and Processing Burst 5 Protected : Infrastructure Object Track 9 Elevation Authenticated";
BA_ "SignalLongName" SG_ 190 SRRSRRODPB5P_IOTk9PolLgPsAuth "Short Range Radar Side Right Rear Object Detection and Processing Burst 5 Protected : Infrastructure Object Track 9 Point of Interest Longitudinal Position Authenticated";
BA_ "SignalType" SG_ 190 SRRSRRODPB5P_IOTk9MStsAuth "ENM";
BA_ "SignalLongName" SG_ 190 SRRSRRODPB5P_IOTk9MStsAuth "Short Range Radar Side Right Rear Object Detection and Processing Burst 5 Protected : Infrastructure Object Track 9 Measurement Status Authenticated";
BA_ "SignalType" SG_ 190 SRRSRRODPB5P_IOTk9TypAuth "ENM";
BA_ "SignalLongName" SG_ 190 SRRSRRODPB5P_IOTk9TypAuth "Short Range Radar Side Right Rear Object Detection and Processing Burst 5 Protected : Infrastructure Object Track 9 Type Authenticated";
BA_ "SignalLongName" SG_ 190 SRRSRRODPB5P_VOTk9PoI2LgPsAuth "Short Range Radar Side Right Rear Object Detection and Processing Burst 5 Protected : Vehicle Object Track 9 Point of Interest 2nd Longitudinal Position Authenticated";
BA_ "SignalType" SG_ 190 SRRSRRODPB5P_IOTk9TypCnfdAuth "ENM";
BA_ "SignalLongName" SG_ 190 SRRSRRODPB5P_IOTk9TypCnfdAuth "Short Range Radar Side Right Rear Object Detection and Processing Burst 5 Protected : Infrastructure Object Track 9 Type Confidence Authenticated";
BA_ "SignalLongName" SG_ 190 SRRSRRODPB5P_VOTk9PoI2LPsAuth "Short Range Radar Side Right Rear Object Detection and Processing Burst 5 Protected : Vehicle Object Track 9 Point of Interest 2nd Lateral Position Authenticated";
BA_ "SignalLongName" SG_ 190 SRRSRRODPB5P_VOTk1PoI2LgPsAuth "Short Range Radar Side Right Rear Object Detection and Processing Burst 5 Protected : Vehicle Object Track 1 Point of Interest 2nd Longitudinal Position Authenticated";
BA_ "SignalLongName" SG_ 190 SRRSRRODPB5P_VOTk1PoI2LPsAuth "Short Range Radar Side Right Rear Object Detection and Processing Burst 5 Protected : Vehicle Object Track 1 Point of Interest 2nd Lateral Position Authenticated";
BA_ "SignalLongName" SG_ 190 SRRSRRODPB5P_VOTk2PoI2LgPsAuth "Short Range Radar Side Right Rear Object Detection and Processing Burst 5 Protected : Vehicle Object Track 2 Point of Interest 2nd Longitudinal Position Authenticated";
BA_ "SignalLongName" SG_ 190 SRRSRRODPB5P_VOTk2PoI2LPsAuth "Short Range Radar Side Right Rear Object Detection and Processing Burst 5 Protected : Vehicle Object Track 2 Point of Interest 2nd Lateral Position Authenticated";
BA_ "SignalLongName" SG_ 190 SRRSRRODPB5P_VOTk3PoI2LgPsAuth "Short Range Radar Side Right Rear Object Detection and Processing Burst 5 Protected : Vehicle Object Track 3 Point of Interest 2nd Longitudinal Position Authenticated";
BA_ "SignalLongName" SG_ 190 SRRSRRODPB5P_VOTk3PoI2LPsAuth "Short Range Radar Side Right Rear Object Detection and Processing Burst 5 Protected : Vehicle Object Track 3 Point of Interest 2nd Lateral Position Authenticated";
BA_ "SignalLongName" SG_ 190 SRRSRRODPB5P_VOTk4PoI2LgPsAuth "Short Range Radar Side Right Rear Object Detection and Processing Burst 5 Protected : Vehicle Object Track 4 Point of Interest 2nd Longitudinal Position Authenticated";
BA_ "SignalLongName" SG_ 190 SRRSRRODPB5P_VOTk4PoI2LPsAuth "Short Range Radar Side Right Rear Object Detection and Processing Burst 5 Protected : Vehicle Object Track 4 Point of Interest 2nd Lateral Position Authenticated";
BA_ "SignalLongName" SG_ 190 SRRSRRODPB5P_VOTk5Pol2LgPsAuth "Short Range Radar Side Right Rear Object Detection and Processing Burst 5 Protected : Vehicle Object Track 5 Point of Interest 2nd Longitudinal Position Authenticated";
BA_ "SignalLongName" SG_ 190 SRRSRRODPB5P_VOTk5Pol2LPsAuth "Short Range Radar Side Right Rear Object Detection and Processing Burst 5 Protected : Vehicle Object Track 5 Point of Interest 2nd Lateral Position Authenticated";
BA_ "SignalLongName" SG_ 190 SRRSRRODPB5P_VOTk6PoI2LgPsAuth "Short Range Radar Side Right Rear Object Detection and Processing Burst 5 Protected : Vehicle Object Track 6 Point of Interest 2nd Longitudinal Position Authenticated";
BA_ "SignalLongName" SG_ 190 SRRSRRODPB5P_VOTk6PoI2LPsAuth "Short Range Radar Side Right Rear Object Detection and Processing Burst 5 Protected : Vehicle Object Track 6 Point of Interest 2nd Lateral Position Authenticated";
BA_ "SignalLongName" SG_ 190 SRRSRRODPB5P_VOTk7PoI2LgPsAuth "Short Range Radar Side Right Rear Object Detection and Processing Burst 5 Protected : Vehicle Object Track 7 Point of Interest 2nd Longitudinal Position Authenticated";
BA_ "SignalLongName" SG_ 190 SRRSRRODPB5P_VOTk7PoI2LPsAuth "Short Range Radar Side Right Rear Object Detection and Processing Burst 5 Protected : Vehicle Object Track 7 Point of Interest 2nd Lateral Position Authenticated";
BA_ "SignalLongName" SG_ 190 SRRSRRODPB5P_VOTk8PoI2LgPsAuth "Short Range Radar Side Right Rear Object Detection and Processing Burst 5 Protected : Vehicle Object Track 8 Point of Interest 2nd Longitudinal Position Authenticated";
BA_ "SignalLongName" SG_ 190 SRRSRRODPB5P_VOTk8PoI2LPsAuth "Short Range Radar Side Right Rear Object Detection and Processing Burst 5 Protected : Vehicle Object Track 8 Point of Interest 2nd Lateral Position Authenticated";
BA_ "SignalLongName" SG_ 190 SRRSRRODPB5P_VOTk10PoI2LgPsAuth "Short Range Radar Side Right Rear Object Detection and Processing Burst 5 Protected : Vehicle Object Track 10 Point of Interest 2nd Longitudinal Position Authenticated";
BA_ "SignalLongName" SG_ 190 SRRSRRODPB5P_VOTk10PoI2LPsAuth "Short Range Radar Side Right Rear Object Detection and Processing Burst 5 Protected : Vehicle Object Track 10 Point of Interest 2nd Lateral Position Authenticated";
BA_ "SignalLongName" SG_ 190 SRRSRRODPB5P_Filler "Short Range Radar Side Right Rear Object Detection and Processing Burst 5 Protected : Filler";
BA_ "SignalLongName" SG_ 193 SRRSRRODPB1P_MAC "Short Range Radar Side Right Rear Object Detection and Processing Burst 1 Protected : MAC";
BA_ "SignalLongName" SG_ 193 SRRSRRODPB1P_FCnt "Short Range Radar Side Right Rear Object Detection and Processing Burst 1 Protected : Freshness Counter";
BA_ "SignalLongName" SG_ 193 SRRSRRODPB1P_AcqTmStmAuth "Short Range Radar Side Right Rear Object Detection and Processing Burst 1 Protected : Acquisition Time Stamp Authenticated";
BA_ "SignalLongName" SG_ 193 SRRSRRODPB1P_BrstID "Short Range Radar Side Right Rear Object Detection and Processing Burst 1 Protected : Burst ID";
BA_ "SignalType" SG_ 193 SRRSRRODPB1P_CnstrArDtnCnfdAuth "ENM";
BA_ "SignalLongName" SG_ 193 SRRSRRODPB1P_CnstrArDtnCnfdAuth "Short Range Radar Side Right Rear Object Detection and Processing Burst 1 Protected : Construction Area Detection Confidence Authenticated";
BA_ "SignalType" SG_ 193 SRRSRRODPB1P_AcqTmStmAuth_Inv "ENM";
BA_ "SignalLongName" SG_ 193 SRRSRRODPB1P_AcqTmStmAuth_Inv "Short Range Radar Side Right Rear Object Detection and Processing Burst 1 Protected : Acquisition Time Stamp Authenticated Invalid";
BA_ "SignalType" SG_ 193 SRRSRRODPB1P_POTk1DynPrpAuth "ENM";
BA_ "SignalLongName" SG_ 193 SRRSRRODPB1P_POTk1DynPrpAuth "Short Range Radar Side Right Rear Object Detection and Processing Burst 1 Protected : Pedestrian Object Track 1 Dynamic Property Authenticated";
BA_ "SignalType" SG_ 193 SRRSRRODPB1P_POTk1CnfdStsAuth "ENM";
BA_ "SignalLongName" SG_ 193 SRRSRRODPB1P_POTk1CnfdStsAuth "Short Range Radar Side Right Rear Object Detection and Processing Burst 1 Protected : Pedestrian Object Track 1 Confidence Status Authenticated";
BA_ "SignalType" SG_ 193 SRRSRRODPB1P_MdCmdStsAuth "ENM";
BA_ "SignalLongName" SG_ 193 SRRSRRODPB1P_MdCmdStsAuth "Short Range Radar Side Right Rear Object Detection and Processing Burst 1 Protected : Mode Command Status Authenticated";
BA_ "SignalType" SG_ 193 SRRSRRODPB1P_CnstrArDtnStsAuth "ENM";
BA_ "SignalLongName" SG_ 193 SRRSRRODPB1P_CnstrArDtnStsAuth "Short Range Radar Side Right Rear Object Detection and Processing Burst 1 Protected : Construction Area Detection Status Authenticated";
BA_ "SignalLongName" SG_ 193 SRRSRRODPB1P_POTk1IDAuth "Short Range Radar Side Right Rear Object Detection and Processing Burst 1 Protected : Pedestrian Object Track 1 ID Authenticated";
BA_ "SignalType" SG_ 193 SRRSRRODPB1P_POTk1MStsAuth "ENM";
BA_ "SignalLongName" SG_ 193 SRRSRRODPB1P_POTk1MStsAuth "Short Range Radar Side Right Rear Object Detection and Processing Burst 1 Protected : Pedestrian Object Track 1 Measurement Status Authenticated";
BA_ "SignalLongName" SG_ 193 SRRSRRODPB1P_POTk1InPthPotAuth "Short Range Radar Side Right Rear Object Detection and Processing Burst 1 Protected : Pedestrian Object Track 1 In Path Potential Authenticated";
BA_ "SignalLongName" SG_ 193 SRRSRRODPB1P_POTk1PoILAAuth "Short Range Radar Side Right Rear Object Detection and Processing Burst 1 Protected : Pedestrian Object Track 1 Point of Interest Lateral Acceleration Authenticated";
BA_ "SignalLongName" SG_ 193 SRRSRRODPB1P_POTk1PoILgAAuth "Short Range Radar Side Right Rear Object Detection and Processing Burst 1 Protected : Pedestrian Object Track 1 Point of Interest Longitudinal Acceleration Authenticated";
BA_ "SignalLongName" SG_ 193 SRRSRRODPB1P_POTk1PoILgPsAuth "Short Range Radar Side Right Rear Object Detection and Processing Burst 1 Protected : Pedestrian Object Track 1 Point of Interest Longitudinal Position Authenticated";
BA_ "SignalLongName" SG_ 193 SRRSRRODPB1P_POTk1PoILgVAuth "Short Range Radar Side Right Rear Object Detection and Processing Burst 1 Protected : Pedestrian Object Track 1 Point of Interest Longitudinal Velocity Authenticated";
BA_ "SignalLongName" SG_ 193 SRRSRRODPB1P_POTk1PoILPsAuth "Short Range Radar Side Right Rear Object Detection and Processing Burst 1 Protected : Pedestrian Object Track 1 Point of Interest Lateral Position Authenticated";
BA_ "SignalLongName" SG_ 193 SRRSRRODPB1P_POTk1PoILVAuth "Short Range Radar Side Right Rear Object Detection and Processing Burst 1 Protected : Pedestrian Object Track 1 Point of Interest Lateral Velocity Authenticated";
BA_ "SignalType" SG_ 193 SRRSRRODPB1P_POTk2CnfdStsAuth "ENM";
BA_ "SignalLongName" SG_ 193 SRRSRRODPB1P_POTk2CnfdStsAuth "Short Range Radar Side Right Rear Object Detection and Processing Burst 1 Protected : Pedestrian Object Track 2 Confidence Status Authenticated";
BA_ "SignalType" SG_ 193 SRRSRRODPB1P_POTk1TypCnfdAuth "ENM";
BA_ "SignalLongName" SG_ 193 SRRSRRODPB1P_POTk1TypCnfdAuth "Short Range Radar Side Right Rear Object Detection and Processing Burst 1 Protected : Pedestrian Object Track 1 Type Confidence Authenticated";
BA_ "SignalType" SG_ 193 SRRSRRODPB1P_POTk1TypAuth "ENM";
BA_ "SignalLongName" SG_ 193 SRRSRRODPB1P_POTk1TypAuth "Short Range Radar Side Right Rear Object Detection and Processing Burst 1 Protected : Pedestrian Object Track 1 Type Authenticated";
BA_ "SignalLongName" SG_ 193 SRRSRRODPB1P_POTk2IDAuth "Short Range Radar Side Right Rear Object Detection and Processing Burst 1 Protected : Pedestrian Object Track 2 ID Authenticated";
BA_ "SignalType" SG_ 193 SRRSRRODPB1P_POTk2DynPrpAuth "ENM";
BA_ "SignalLongName" SG_ 193 SRRSRRODPB1P_POTk2DynPrpAuth "Short Range Radar Side Right Rear Object Detection and Processing Burst 1 Protected : Pedestrian Object Track 2 Dynamic Property Authenticated";
BA_ "SignalLongName" SG_ 193 SRRSRRODPB1P_POTk2InPthPotAuth "Short Range Radar Side Right Rear Object Detection and Processing Burst 1 Protected : Pedestrian Object Track 2 In Path Potential Authenticated";
BA_ "SignalLongName" SG_ 193 SRRSRRODPB1P_POTk2PoILAAuth "Short Range Radar Side Right Rear Object Detection and Processing Burst 1 Protected : Pedestrian Object Track 2 Point of Interest Lateral Acceleration Authenticated";
BA_ "SignalType" SG_ 193 SRRSRRODPB1P_POTk2MStsAuth "ENM";
BA_ "SignalLongName" SG_ 193 SRRSRRODPB1P_POTk2MStsAuth "Short Range Radar Side Right Rear Object Detection and Processing Burst 1 Protected : Pedestrian Object Track 2 Measurement Status Authenticated";
BA_ "SignalLongName" SG_ 193 SRRSRRODPB1P_POTk2PoILgAAuth "Short Range Radar Side Right Rear Object Detection and Processing Burst 1 Protected : Pedestrian Object Track 2 Point of Interest Longitudinal Acceleration Authenticated";
BA_ "SignalLongName" SG_ 193 SRRSRRODPB1P_POTk2PoILgPsAuth "Short Range Radar Side Right Rear Object Detection and Processing Burst 1 Protected : Pedestrian Object Track 2 Point of Interest Longitudinal Position Authenticated";
BA_ "SignalLongName" SG_ 193 SRRSRRODPB1P_POTk2PoILgVAuth "Short Range Radar Side Right Rear Object Detection and Processing Burst 1 Protected : Pedestrian Object Track 2 Point of Interest Longitudinal Velocity Authenticated";
BA_ "SignalLongName" SG_ 193 SRRSRRODPB1P_POTk2PoILPsAuth "Short Range Radar Side Right Rear Object Detection and Processing Burst 1 Protected : Pedestrian Object Track 2 Point of Interest Lateral Position Authenticated";
BA_ "SignalLongName" SG_ 193 SRRSRRODPB1P_POTk2PoILVAuth "Short Range Radar Side Right Rear Object Detection and Processing Burst 1 Protected : Pedestrian Object Track 2 Point of Interest Lateral Velocity Authenticated";
BA_ "SignalType" SG_ 193 SRRSRRODPB1P_POTk2TypCnfdAuth "ENM";
BA_ "SignalLongName" SG_ 193 SRRSRRODPB1P_POTk2TypCnfdAuth "Short Range Radar Side Right Rear Object Detection and Processing Burst 1 Protected : Pedestrian Object Track 2 Type Confidence Authenticated";
BA_ "SignalType" SG_ 193 SRRSRRODPB1P_POTk2TypAuth "ENM";
BA_ "SignalLongName" SG_ 193 SRRSRRODPB1P_POTk2TypAuth "Short Range Radar Side Right Rear Object Detection and Processing Burst 1 Protected : Pedestrian Object Track 2 Type Authenticated";
BA_ "SignalType" SG_ 193 SRRSRRODPB1P_SnsrUnvAuth "ENM";
BA_ "SignalLongName" SG_ 193 SRRSRRODPB1P_SnsrUnvAuth "Short Range Radar Side Right Rear Object Detection and Processing Burst 1 Protected : Sensor Unavailable Authenticated";
BA_ "SignalType" SG_ 193 SRRSRRODPB1P_SnsrBlckdAuth "ENM";
BA_ "SignalLongName" SG_ 193 SRRSRRODPB1P_SnsrBlckdAuth "Short Range Radar Side Right Rear Object Detection and Processing Burst 1 Protected : Sensor Blocked Authenticated";
BA_ "SignalType" SG_ 193 SRRSRRODPB1P_ServRqrdAuth "ENM";
BA_ "SignalLongName" SG_ 193 SRRSRRODPB1P_ServRqrdAuth "Short Range Radar Side Right Rear Object Detection and Processing Burst 1 Protected : Service Required Authenticated";
BA_ "SignalType" SG_ 193 SRRSRRODPB1P_RdTypCnfdAuth "ENM";
BA_ "SignalLongName" SG_ 193 SRRSRRODPB1P_RdTypCnfdAuth "Short Range Radar Side Right Rear Object Detection and Processing Burst 1 Protected : Road Type Confidence Authenticated";
BA_ "SignalType" SG_ 193 SRRSRRODPB1P_RdTypAuth "ENM";
BA_ "SignalLongName" SG_ 193 SRRSRRODPB1P_RdTypAuth "Short Range Radar Side Right Rear Object Detection and Processing Burst 1 Protected : Road Type Authenticated";
BA_ "SignalLongName" SG_ 193 SRRSRRODPB1P_VOTk1CICOPotAuth "Short Range Radar Side Right Rear Object Detection and Processing Burst 1 Protected : Vehicle Object Track 1 Cut In Cut Out Potential Authenticated";
BA_ "SignalType" SG_ 193 SRRSRRODPB1P_SwpBndwdthStsAuth "ENM";
BA_ "SignalLongName" SG_ 193 SRRSRRODPB1P_SwpBndwdthStsAuth "Short Range Radar Side Right Rear Object Detection and Processing Burst 1 Protected : Sweep Bandwidth Status Authenticated";
BA_ "SignalLongName" SG_ 193 SRRSRRODPB1P_VOTk1IDAuth "Short Range Radar Side Right Rear Object Detection and Processing Burst 1 Protected : Vehicle Object Track 1 ID Authenticated";
BA_ "SignalType" SG_ 193 SRRSRRODPB1P_VOTk1DynPrpStsAuth "ENM";
BA_ "SignalLongName" SG_ 193 SRRSRRODPB1P_VOTk1DynPrpStsAuth "Short Range Radar Side Right Rear Object Detection and Processing Burst 1 Protected : Vehicle Object Track 1 Dynamic Property Status Authenticated";
BA_ "SignalType" SG_ 193 SRRSRRODPB1P_VOTk1DynPrpAuth "ENM";
BA_ "SignalLongName" SG_ 193 SRRSRRODPB1P_VOTk1DynPrpAuth "Short Range Radar Side Right Rear Object Detection and Processing Burst 1 Protected : Vehicle Object Track 1 Dynamic Property Authenticated";
BA_ "SignalType" SG_ 193 SRRSRRODPB1P_VOTk1CnfdStsAuth "ENM";
BA_ "SignalLongName" SG_ 193 SRRSRRODPB1P_VOTk1CnfdStsAuth "Short Range Radar Side Right Rear Object Detection and Processing Burst 1 Protected : Vehicle Object Track 1 Confidence Status Authenticated";
BA_ "SignalLongName" SG_ 193 SRRSRRODPB1P_VOTk1PoILAAuth "Short Range Radar Side Right Rear Object Detection and Processing Burst 1 Protected : Vehicle Object Track 1 Point of Interest Lateral Acceleration Authenticated";
BA_ "SignalType" SG_ 193 SRRSRRODPB1P_VOTk1MStsAuth "ENM";
BA_ "SignalLongName" SG_ 193 SRRSRRODPB1P_VOTk1MStsAuth "Short Range Radar Side Right Rear Object Detection and Processing Burst 1 Protected : Vehicle Object Track 1 Measurement Status Authenticated";
BA_ "SignalLongName" SG_ 193 SRRSRRODPB1P_VOTk1PoILgAAuth "Short Range Radar Side Right Rear Object Detection and Processing Burst 1 Protected : Vehicle Object Track 1 Point of Interest Longitudinal Acceleration Authenticated";
BA_ "SignalLongName" SG_ 193 SRRSRRODPB1P_VOTk1PoILgPsAuth "Short Range Radar Side Right Rear Object Detection and Processing Burst 1 Protected : Vehicle Object Track 1 Point of Interest Longitudinal Position Authenticated";
BA_ "SignalLongName" SG_ 193 SRRSRRODPB1P_VOTk1PoILgPsCAuth "Short Range Radar Side Right Rear Object Detection and Processing Burst 1 Protected : Vehicle Object Track 1 Point of Interest Longitudinal Position Covariance Authenticated";
BA_ "SignalLongName" SG_ 193 SRRSRRODPB1P_VOTk1PoILgthAuth "Short Range Radar Side Right Rear Object Detection and Processing Burst 1 Protected : Vehicle Object Track 1 Point of Interest Length Authenticated";
BA_ "SignalLongName" SG_ 193 SRRSRRODPB1P_VOTk1PoILgVAuth "Short Range Radar Side Right Rear Object Detection and Processing Burst 1 Protected : Vehicle Object Track 1 Point of Interest Longitudinal Velocity Authenticated";
BA_ "SignalLongName" SG_ 193 SRRSRRODPB1P_VOTk1PoILgVCAuth "Short Range Radar Side Right Rear Object Detection and Processing Burst 1 Protected : Vehicle Object Track 1 Point of Interest Longitudinal Velocity Covariance Authenticated";
BA_ "SignalLongName" SG_ 193 SRRSRRODPB1P_VOTk1PoILPsAuth "Short Range Radar Side Right Rear Object Detection and Processing Burst 1 Protected : Vehicle Object Track 1 Point of Interest Lateral Position Authenticated";
BA_ "SignalLongName" SG_ 193 SRRSRRODPB1P_VOTk1PoILPsCAuth "Short Range Radar Side Right Rear Object Detection and Processing Burst 1 Protected : Vehicle Object Track 1 Point of Interest Lateral Position Covariance Authenticated";
BA_ "SignalLongName" SG_ 193 SRRSRRODPB1P_VOTk1PoILVAuth "Short Range Radar Side Right Rear Object Detection and Processing Burst 1 Protected : Vehicle Object Track 1 Point of Interest Lateral Velocity Authenticated";
BA_ "SignalLongName" SG_ 193 SRRSRRODPB1P_VOTk1PoILVCAuth "Short Range Radar Side Right Rear Object Detection and Processing Burst 1 Protected : Vehicle Object Track 1 Point of Interest Lateral Velocity Covariance Authenticated";
BA_ "SignalLongName" SG_ 193 SRRSRRODPB1P_VOTk2PoILgthAuth "Short Range Radar Side Right Rear Object Detection and Processing Burst 1 Protected : Vehicle Object Track 2 Point of Interest Length Authenticated";
BA_ "SignalType" SG_ 193 SRRSRRODPB1P_VOTk1TypCnfdAuth "ENM";
BA_ "SignalLongName" SG_ 193 SRRSRRODPB1P_VOTk1TypCnfdAuth "Short Range Radar Side Right Rear Object Detection and Processing Burst 1 Protected : Vehicle Object Track 1 Type Confidence Authenticated";
BA_ "SignalLongName" SG_ 193 SRRSRRODPB1P_ARC "Short Range Radar Side Right Rear Object Detection and Processing Burst 1 Protected : Alive Rolling Count";
BA_ "SignalLongName" SG_ 522 SRRSRRODPB6P_IOTk10PolLPsAuth "Short Range Radar Side Right Rear Object Detection and Processing Burst 6 Protected : Infrastructure Object Track 10 Point of Interest Lateral Position Authenticated";
BA_ "SignalLongName" SG_ 522 SRRSRRODPB6P_BrstID "Short Range Radar Side Right Rear Object Detection and Processing Burst 6 Protected : Burst ID";
BA_ "SignalLongName" SG_ 522 SRRSRRODPB6P_IOTk1PoILPsAuth "Short Range Radar Side Right Rear Object Detection and Processing Burst 6 Protected : Infrastructure Object Track 1 Point of Interest Lateral Position Authenticated";
BA_ "SignalLongName" SG_ 522 SRRSRRODPB6P_IOTk2PolLPsAuth "Short Range Radar Side Right Rear Object Detection and Processing Burst 6 Protected : Infrastructure Object Track 2 Point of Interest Lateral Position Authenticated";
BA_ "SignalLongName" SG_ 522 SRRSRRODPB6P_IOTk3PolLPsAuth "Short Range Radar Side Right Rear Object Detection and Processing Burst 6 Protected : Infrastructure Object Track 3 Point of Interest Lateral Position Authenticated";
BA_ "SignalLongName" SG_ 522 SRRSRRODPB6P_IOTk4PolLPsAuth "Short Range Radar Side Right Rear Object Detection and Processing Burst 6 Protected : Infrastructure Object Track 4 Point of Interest Lateral Position Authenticated";
BA_ "SignalLongName" SG_ 522 SRRSRRODPB6P_IOTk5PolLPsAuth "Short Range Radar Side Right Rear Object Detection and Processing Burst 6 Protected : Infrastructure Object Track 5 Point of Interest Lateral Position Authenticated";
BA_ "SignalLongName" SG_ 522 SRRSRRODPB6P_IOTk6PolLPsAuth "Short Range Radar Side Right Rear Object Detection and Processing Burst 6 Protected : Infrastructure Object Track 6 Point of Interest Lateral Position Authenticated";
BA_ "SignalLongName" SG_ 522 SRRSRRODPB6P_IOTk7PolLPsAuth "Short Range Radar Side Right Rear Object Detection and Processing Burst 6 Protected : Infrastructure Object Track 7 Point of Interest Lateral Position Authenticated";
BA_ "SignalLongName" SG_ 522 SRRSRRODPB6P_IOTk8PolLPsAuth "Short Range Radar Side Right Rear Object Detection and Processing Burst 6 Protected : Infrastructure Object Track 8 Point of Interest Lateral Position Authenticated";
BA_ "SignalLongName" SG_ 522 SRRSRRODPB6P_IOTk9PolLPsAuth "Short Range Radar Side Right Rear Object Detection and Processing Burst 6 Protected : Infrastructure Object Track 9 Point of Interest Lateral Position Authenticated";
BA_ "SignalType" SG_ 522 SRRSRRODPB6P_REOTk1CnfdStsAuth "ENM";
BA_ "SignalLongName" SG_ 522 SRRSRRODPB6P_REOTk1CnfdStsAuth "Short Range Radar Side Right Rear Object Detection and Processing Burst 6 Protected : Road Edge Object Track 1 Confidence Status Authenticated";
BA_ "SignalLongName" SG_ 522 SRRSRRODPB6P_REOTk1CrvAuth "Short Range Radar Side Right Rear Object Detection and Processing Burst 6 Protected : Road Edge Object Track 1 Curvature Authenticated";
BA_ "SignalLongName" SG_ 522 SRRSRRODPB6P_REOTk1CrvDrvtAuth "Short Range Radar Side Right Rear Object Detection and Processing Burst 6 Protected : Road Edge Object Track 1 Curvature Derivative Authenticated";
BA_ "SignalLongName" SG_ 522 SRRSRRODPB6P_REOTk1HdgAuth "Short Range Radar Side Right Rear Object Detection and Processing Burst 6 Protected : Road Edge Object Track 1 Heading Authenticated";
BA_ "SignalLongName" SG_ 522 SRRSRRODPB6P_REOTk1OfstAuth "Short Range Radar Side Right Rear Object Detection and Processing Burst 6 Protected : Road Edge Object Track 1 Offset Authenticated";
BA_ "SignalLongName" SG_ 522 SRRSRRODPB6P_REOTk1PsEndAuth "Short Range Radar Side Right Rear Object Detection and Processing Burst 6 Protected : Road Edge Object Track 1 Position End Authenticated";
BA_ "SignalLongName" SG_ 522 SRRSRRODPB6P_REOTk1PsStrtAuth "Short Range Radar Side Right Rear Object Detection and Processing Burst 6 Protected : Road Edge Object Track 1 Position Start Authenticated";
BA_ "SignalType" SG_ 522 SRRSRRODPB6P_REOTk2CnfdStsAuth "ENM";
BA_ "SignalLongName" SG_ 522 SRRSRRODPB6P_REOTk2CnfdStsAuth "Short Range Radar Side Right Rear Object Detection and Processing Burst 6 Protected : Road Edge Object Track 2 Confidence Status Authenticated";
BA_ "SignalType" SG_ 522 SRRSRRODPB6P_REOTk1TypCnfdAuth "ENM";
BA_ "SignalLongName" SG_ 522 SRRSRRODPB6P_REOTk1TypCnfdAuth "Short Range Radar Side Right Rear Object Detection and Processing Burst 6 Protected : Road Edge Object Track 1 Type Confidence Authenticated";
BA_ "SignalType" SG_ 522 SRRSRRODPB6P_REOTk1TypAuth "ENM";
BA_ "SignalLongName" SG_ 522 SRRSRRODPB6P_REOTk1TypAuth "Short Range Radar Side Right Rear Object Detection and Processing Burst 6 Protected : Road Edge Object Track 1 Type Authenticated";
BA_ "SignalLongName" SG_ 522 SRRSRRODPB6P_REOTk2CrvAuth "Short Range Radar Side Right Rear Object Detection and Processing Burst 6 Protected : Road Edge Object Track 2 Curvature Authenticated";
BA_ "SignalLongName" SG_ 522 SRRSRRODPB6P_REOTk2CrvDrvtAuth "Short Range Radar Side Right Rear Object Detection and Processing Burst 6 Protected : Road Edge Object Track 2 Curvature Derivative Authenticated";
BA_ "SignalLongName" SG_ 522 SRRSRRODPB6P_REOTk2HdgAuth "Short Range Radar Side Right Rear Object Detection and Processing Burst 6 Protected : Road Edge Object Track 2 Heading Authenticated";
BA_ "SignalLongName" SG_ 522 SRRSRRODPB6P_REOTk2OfstAuth "Short Range Radar Side Right Rear Object Detection and Processing Burst 6 Protected : Road Edge Object Track 2 Offset Authenticated";
BA_ "SignalLongName" SG_ 522 SRRSRRODPB6P_REOTk2PsEndAuth "Short Range Radar Side Right Rear Object Detection and Processing Burst 6 Protected : Road Edge Object Track 2 Position End Authenticated";
BA_ "SignalLongName" SG_ 522 SRRSRRODPB6P_REOTk2PsStrtAuth "Short Range Radar Side Right Rear Object Detection and Processing Burst 6 Protected : Road Edge Object Track 2 Position Start Authenticated";
BA_ "SignalType" SG_ 522 SRRSRRODPB6P_REOTk3CnfdStsAuth "ENM";
BA_ "SignalLongName" SG_ 522 SRRSRRODPB6P_REOTk3CnfdStsAuth "Short Range Radar Side Right Rear Object Detection and Processing Burst 6 Protected : Road Edge Object Track 3 Confidence Status Authenticated";
BA_ "SignalType" SG_ 522 SRRSRRODPB6P_REOTk2TypCnfdAuth "ENM";
BA_ "SignalLongName" SG_ 522 SRRSRRODPB6P_REOTk2TypCnfdAuth "Short Range Radar Side Right Rear Object Detection and Processing Burst 6 Protected : Road Edge Object Track 2 Type Confidence Authenticated";
BA_ "SignalType" SG_ 522 SRRSRRODPB6P_REOTk2TypAuth "ENM";
BA_ "SignalLongName" SG_ 522 SRRSRRODPB6P_REOTk2TypAuth "Short Range Radar Side Right Rear Object Detection and Processing Burst 6 Protected : Road Edge Object Track 2 Type Authenticated";
BA_ "SignalLongName" SG_ 522 SRRSRRODPB6P_REOTk3CrvAuth "Short Range Radar Side Right Rear Object Detection and Processing Burst 6 Protected : Road Edge Object Track 3 Curvature Authenticated";
BA_ "SignalLongName" SG_ 522 SRRSRRODPB6P_REOTk3CrvDrvtAuth "Short Range Radar Side Right Rear Object Detection and Processing Burst 6 Protected : Road Edge Object Track 3 Curvature Derivative Authenticated";
BA_ "SignalLongName" SG_ 522 SRRSRRODPB6P_REOTk3HdgAuth "Short Range Radar Side Right Rear Object Detection and Processing Burst 6 Protected : Road Edge Object Track 3 Heading Authenticated";
BA_ "SignalLongName" SG_ 522 SRRSRRODPB6P_REOTk3OfstAuth "Short Range Radar Side Right Rear Object Detection and Processing Burst 6 Protected : Road Edge Object Track 3 Offset Authenticated";
BA_ "SignalLongName" SG_ 522 SRRSRRODPB6P_REOTk3PsEndAuth "Short Range Radar Side Right Rear Object Detection and Processing Burst 6 Protected : Road Edge Object Track 3 Position End Authenticated";
BA_ "SignalLongName" SG_ 522 SRRSRRODPB6P_REOTk3PsStrtAuth "Short Range Radar Side Right Rear Object Detection and Processing Burst 6 Protected : Road Edge Object Track 3 Position Start Authenticated";
BA_ "SignalLongName" SG_ 522 SRRSRRODPB6P_Filler "Short Range Radar Side Right Rear Object Detection and Processing Burst 6 Protected : Filler";
BA_ "SignalType" SG_ 522 SRRSRRODPB6P_REOTk3TypCnfdAuth "ENM";
BA_ "SignalLongName" SG_ 522 SRRSRRODPB6P_REOTk3TypCnfdAuth "Short Range Radar Side Right Rear Object Detection and Processing Burst 6 Protected : Road Edge Object Track 3 Type Confidence Authenticated";
BA_ "SignalType" SG_ 522 SRRSRRODPB6P_REOTk3TypAuth "ENM";
BA_ "SignalLongName" SG_ 522 SRRSRRODPB6P_REOTk3TypAuth "Short Range Radar Side Right Rear Object Detection and Processing Burst 6 Protected : Road Edge Object Track 3 Type Authenticated";
BA_ "SignalLongName" SG_ 522 SRRSRRODPB6P_FillerExtnd "Short Range Radar Side Right Rear Object Detection and Processing Burst 6 Protected : Filler Extended";
BA_ "SignalType" SG_ 2147745812 SRR_LF_CAN8_ClscCANHrtBtActv "ENM";
BA_ "SignalLongName" SG_ 2147745812 SRR_LF_CAN8_ClscCANHrtBtActv "SRR_LF CAN 8 Classic CAN Heart Beat Active";
BA_ "SignalType" SG_ 2147745813 SRR_LR_CR_CAN8_ClscCANHrtBtActv "ENM";
BA_ "SignalLongName" SG_ 2147745813 SRR_LR_CR_CAN8_ClscCANHrtBtActv "SRR_LR_CR CAN 8 Classic CAN Heart Beat Active";
BA_ "SignalType" SG_ 2147745814 SRR_RF_CAN8_ClscCANHrtBtActv "ENM";
BA_ "SignalLongName" SG_ 2147745814 SRR_RF_CAN8_ClscCANHrtBtActv "SRR_RF CAN 8 Classic CAN Heart Beat Active";
BA_ "SignalType" SG_ 2147745815 SRR_RR_CAN8_ClscCANHrtBtActv "ENM";
BA_ "SignalLongName" SG_ 2147745815 SRR_RR_CAN8_ClscCANHrtBtActv "SRR_RR CAN 8 Classic CAN Heart Beat Active";
BA_ "SignalType" SG_ 2147745816 SRR_SLR_CAN8_ClscCANHrtBtActv "ENM";
BA_ "SignalLongName" SG_ 2147745816 SRR_SLR_CAN8_ClscCANHrtBtActv "SRR_SLR CAN 8 Classic CAN Heart Beat Active";
BA_ "SignalType" SG_ 2147745817 SRR_SRR_CAN8_ClscCANHrtBtActv "ENM";
BA_ "SignalLongName" SG_ 2147745817 SRR_SRR_CAN8_ClscCANHrtBtActv "SRR_SRR CAN 8 Classic CAN Heart Beat Active";
BA_ "SignalLongName" SG_ 1348 SpdLimVsnFsdSpd_PCSM "Speed Limit Vision Fused Speed Protected Counter Sync Message";
BA_ "SignalLongName" SG_ 1317 SLVFSP_MAC "Speed Limit Vision Fused Speed Protected : MAC";
BA_ "SignalLongName" SG_ 1317 SLVFSP_FCnt "Speed Limit Vision Fused Speed Protected : Freshness Counter";
BA_ "SignalLongName" SG_ 1317 SLVFSP_SpdLimVsnFsdSpdAuth "Speed Limit Vision Fused Speed Protected : Speed Limit Vision Fused Speed Authenticated";
BA_ "SignalLongName" SG_ 1317 SLVFSP_Filler "Speed Limit Vision Fused Speed Protected : Filler";
BA_ "SignalLongName" SG_ 1317 SLVFSP_ARC "Speed Limit Vision Fused Speed Protected : Alive Rolling Count";
BA_ "SignalType" SG_ 1317 SLVFSP_SpdLimVsnFsdSpdUntAuth "ENM";
BA_ "SignalLongName" SG_ 1317 SLVFSP_SpdLimVsnFsdSpdUntAuth "Speed Limit Vision Fused Speed Protected : Speed Limit Vision Fused Speed Unit Authenticated";
BA_ "SignalType" SG_ 1317 SLVFSP_SpdLimVsnFsdSpdNwDtdAuth "ENM";
BA_ "SignalLongName" SG_ 1317 SLVFSP_SpdLimVsnFsdSpdNwDtdAuth "Speed Limit Vision Fused Speed Protected : Speed Limit Vision Fused Speed New Detected Authenticated";
BA_ "SignalType" SG_ 1317 SLVFSP_SpdLimVsnFsdSpdAuth_DuD "ENM";
BA_ "SignalLongName" SG_ 1317 SLVFSP_SpdLimVsnFsdSpdAuth_DuD "Speed Limit Vision Fused Speed Protected : Speed Limit Vision Fused Speed Authenticated Don't Use Data";
BA_ "SignalLongName" SG_ 1378 SpnsnGenInfo2_PCSM "Suspension General Information 2 Protected Counter Sync Message";
BA_ "SignalLongName" SG_ 1309 SGI2P_MAC "Suspension General Information 2 Protected : MAC";
BA_ "SignalLongName" SG_ 1309 SGI2P_FCnt "Suspension General Information 2 Protected : Freshness Counter";
BA_ "SignalType" SG_ 1309 SGI2P_AirSpnsnRdHghtLwrActnAuth "ENM";
BA_ "SignalLongName" SG_ 1309 SGI2P_AirSpnsnRdHghtLwrActnAuth "Suspension General Information 2 Protected : Air Suspension Ride Height Lower Action Authenticated";
BA_ "SignalType" SG_ 1309 SGI2P_AirSpnsnRdHghtActvAxlAuth "ENM";
BA_ "SignalLongName" SG_ 1309 SGI2P_AirSpnsnRdHghtActvAxlAuth "Suspension General Information 2 Protected : Air Suspension Ride Height Active Axle Authenticated";
BA_ "SignalType" SG_ 1309 SGI2P_AirSpnsnRdHghtActlStsAuth "ENM";
BA_ "SignalLongName" SG_ 1309 SGI2P_AirSpnsnRdHghtActlStsAuth "Suspension General Information 2 Protected : Air Suspension Ride Height Actual Status Authenticated";
BA_ "SignalLongName" SG_ 1309 SGI2P_ARC "Suspension General Information 2 Protected : Alive Rolling Count";
BA_ "SignalType" SG_ 1309 SGI2P_AirSpnsnRdHghtTgtStsAuth "ENM";
BA_ "SignalLongName" SG_ 1309 SGI2P_AirSpnsnRdHghtTgtStsAuth "Suspension General Information 2 Protected : Air Suspension Ride Height Target Status Authenticated";
BA_ "SignalType" SG_ 1309 SGI2P_AirSpnsnRdHghtRseActnAuth "ENM";
BA_ "SignalLongName" SG_ 1309 SGI2P_AirSpnsnRdHghtRseActnAuth "Suspension General Information 2 Protected : Air Suspension Ride Height Raise Action Authenticated";
BA_ "SignalLongName" SG_ 636 SrlDat100_PCSM "Serial Data 100 Protected Counter Sync Message";
BA_ "SignalLongName" SG_ 179 SD100P_MAC "Serial Data 100 Protected : MAC";
BA_ "SignalLongName" SG_ 179 SD100P_FCnt "Serial Data 100 Protected : Freshness Counter";
BA_ "SignalLongName" SG_ 179 SD100P_Filler "Serial Data 100 Protected : Filler";
BA_ "SignalType" SG_ 179 FsdLoclzdRdTyp "ENM";
BA_ "SignalLongName" SG_ 179 FsdLoclzdRdTyp "Serial Data 100 Protected : Fused Localized Road Type";
BA_ "SignalLongName" SG_ 179 SD100P_ARC "Serial Data 100 Protected : Alive Rolling Count";
BA_ "SignalLongName" SG_ 884 SrlDat101_PCSM "Serial Data 101 Protected Counter Sync Message";
BA_ "SignalLongName" SG_ 180 SD101P_MAC "Serial Data 101 Protected : MAC";
BA_ "SignalLongName" SG_ 180 SD101P_FCnt "Serial Data 101 Protected : Freshness Counter";
BA_ "SignalLongName" SG_ 180 UODPFrtEchoAcqTmStm "Serial Data 101 Protected : Ultrasonic Object Detection and Processing Front Echo Acquisition Time Stamp";
BA_ "SignalLongName" SG_ 180 UODPFrtSnsr1EchoDist1 "Serial Data 101 Protected : Ultrasonic Object Detection and Processing Front Sensor 1 Echo Distance 1";
BA_ "SignalType" SG_ 180 UODPFrtEchoAcqTmStm_Inv "ENM";
BA_ "SignalLongName" SG_ 180 UODPFrtEchoAcqTmStm_Inv "Serial Data 101 Protected : Ultrasonic Object Detection and Processing Front Echo Acquisition Time Stamp Invalid";
BA_ "SignalLongName" SG_ 180 UODPFrtSnsr1EchoDist2 "Serial Data 101 Protected : Ultrasonic Object Detection and Processing Front Sensor 1 Echo Distance 2";
BA_ "SignalLongName" SG_ 180 UODPFrtSnsr1EchoDist3 "Serial Data 101 Protected : Ultrasonic Object Detection and Processing Front Sensor 1 Echo Distance 3";
BA_ "SignalLongName" SG_ 180 UODPFrtSnsr1EchoQlty1 "Serial Data 101 Protected : Ultrasonic Object Detection and Processing Front Sensor 1 Echo Quality 1";
BA_ "SignalLongName" SG_ 180 UODPFrtSnsr1EchoQlty3 "Serial Data 101 Protected : Ultrasonic Object Detection and Processing Front Sensor 1 Echo Quality 3";
BA_ "SignalLongName" SG_ 180 UODPFrtSnsr1EchoQlty2 "Serial Data 101 Protected : Ultrasonic Object Detection and Processing Front Sensor 1 Echo Quality 2";
BA_ "SignalLongName" SG_ 180 UODPFrtSnsr2EchoDist1 "Serial Data 101 Protected : Ultrasonic Object Detection and Processing Front Sensor 2 Echo Distance 1";
BA_ "SignalType" SG_ 180 UODPFrtSnsr1EchoSnsrMode "ENM";
BA_ "SignalLongName" SG_ 180 UODPFrtSnsr1EchoSnsrMode "Serial Data 101 Protected : Ultrasonic Object Detection and Processing Front Sensor 1 Echo Sensor Mode";
BA_ "SignalType" SG_ 180 UODPFrtSnsr1EchoSnsrDatUsg "ENM";
BA_ "SignalLongName" SG_ 180 UODPFrtSnsr1EchoSnsrDatUsg "Serial Data 101 Protected : Ultrasonic Object Detection and Processing Front Sensor 1 Echo Sensor Data Usage";
BA_ "SignalLongName" SG_ 180 UODPFrtSnsr2EchoDist2 "Serial Data 101 Protected : Ultrasonic Object Detection and Processing Front Sensor 2 Echo Distance 2";
BA_ "SignalLongName" SG_ 180 UODPFrtSnsr2EchoDist3 "Serial Data 101 Protected : Ultrasonic Object Detection and Processing Front Sensor 2 Echo Distance 3";
BA_ "SignalLongName" SG_ 180 UODPFrtSnsr2EchoQlty1 "Serial Data 101 Protected : Ultrasonic Object Detection and Processing Front Sensor 2 Echo Quality 1";
BA_ "SignalLongName" SG_ 180 UODPFrtSnsr2EchoQlty3 "Serial Data 101 Protected : Ultrasonic Object Detection and Processing Front Sensor 2 Echo Quality 3";
BA_ "SignalLongName" SG_ 180 UODPFrtSnsr2EchoQlty2 "Serial Data 101 Protected : Ultrasonic Object Detection and Processing Front Sensor 2 Echo Quality 2";
BA_ "SignalLongName" SG_ 180 UODPFrtSnsr3EchoDist1 "Serial Data 101 Protected : Ultrasonic Object Detection and Processing Front Sensor 3 Echo Distance 1";
BA_ "SignalType" SG_ 180 UODPFrtSnsr2EchoSnsrMode "ENM";
BA_ "SignalLongName" SG_ 180 UODPFrtSnsr2EchoSnsrMode "Serial Data 101 Protected : Ultrasonic Object Detection and Processing Front Sensor 2 Echo Sensor Mode";
BA_ "SignalType" SG_ 180 UODPFrtSnsr2EchoSnsrDatUsg "ENM";
BA_ "SignalLongName" SG_ 180 UODPFrtSnsr2EchoSnsrDatUsg "Serial Data 101 Protected : Ultrasonic Object Detection and Processing Front Sensor 2 Echo Sensor Data Usage";
BA_ "SignalLongName" SG_ 180 UODPFrtSnsr3EchoDist2 "Serial Data 101 Protected : Ultrasonic Object Detection and Processing Front Sensor 3 Echo Distance 2";
BA_ "SignalLongName" SG_ 180 UODPFrtSnsr3EchoDist3 "Serial Data 101 Protected : Ultrasonic Object Detection and Processing Front Sensor 3 Echo Distance 3";
BA_ "SignalLongName" SG_ 180 UODPFrtSnsr3EchoQlty1 "Serial Data 101 Protected : Ultrasonic Object Detection and Processing Front Sensor 3 Echo Quality 1";
BA_ "SignalLongName" SG_ 180 UODPFrtSnsr3EchoQlty3 "Serial Data 101 Protected : Ultrasonic Object Detection and Processing Front Sensor 3 Echo Quality 3";
BA_ "SignalLongName" SG_ 180 UODPFrtSnsr3EchoQlty2 "Serial Data 101 Protected : Ultrasonic Object Detection and Processing Front Sensor 3 Echo Quality 2";
BA_ "SignalLongName" SG_ 180 UODPFrtSnsr4EchoDist1 "Serial Data 101 Protected : Ultrasonic Object Detection and Processing Front Sensor 4 Echo Distance 1";
BA_ "SignalType" SG_ 180 UODPFrtSnsr3EchoSnsrMode "ENM";
BA_ "SignalLongName" SG_ 180 UODPFrtSnsr3EchoSnsrMode "Serial Data 101 Protected : Ultrasonic Object Detection and Processing Front Sensor 3 Echo Sensor Mode";
BA_ "SignalType" SG_ 180 UODPFrtSnsr3EchoSnsrDatUsg "ENM";
BA_ "SignalLongName" SG_ 180 UODPFrtSnsr3EchoSnsrDatUsg "Serial Data 101 Protected : Ultrasonic Object Detection and Processing Front Sensor 3 Echo Sensor Data Usage";
BA_ "SignalLongName" SG_ 180 UODPFrtSnsr4EchoDist2 "Serial Data 101 Protected : Ultrasonic Object Detection and Processing Front Sensor 4 Echo Distance 2";
BA_ "SignalLongName" SG_ 180 UODPFrtSnsr4EchoDist3 "Serial Data 101 Protected : Ultrasonic Object Detection and Processing Front Sensor 4 Echo Distance 3";
BA_ "SignalLongName" SG_ 180 UODPFrtSnsr4EchoQlty1 "Serial Data 101 Protected : Ultrasonic Object Detection and Processing Front Sensor 4 Echo Quality 1";
BA_ "SignalLongName" SG_ 180 UODPFrtSnsr4EchoQlty3 "Serial Data 101 Protected : Ultrasonic Object Detection and Processing Front Sensor 4 Echo Quality 3";
BA_ "SignalLongName" SG_ 180 UODPFrtSnsr4EchoQlty2 "Serial Data 101 Protected : Ultrasonic Object Detection and Processing Front Sensor 4 Echo Quality 2";
BA_ "SignalLongName" SG_ 180 UODPFrtSnsr5EchoDist1 "Serial Data 101 Protected : Ultrasonic Object Detection and Processing Front Sensor 5 Echo Distance 1";
BA_ "SignalType" SG_ 180 UODPFrtSnsr4EchoSnsrMode "ENM";
BA_ "SignalLongName" SG_ 180 UODPFrtSnsr4EchoSnsrMode "Serial Data 101 Protected : Ultrasonic Object Detection and Processing Front Sensor 4 Echo Sensor Mode";
BA_ "SignalType" SG_ 180 UODPFrtSnsr4EchoSnsrDatUsg "ENM";
BA_ "SignalLongName" SG_ 180 UODPFrtSnsr4EchoSnsrDatUsg "Serial Data 101 Protected : Ultrasonic Object Detection and Processing Front Sensor 4 Echo Sensor Data Usage";
BA_ "SignalLongName" SG_ 180 UODPFrtSnsr5EchoDist2 "Serial Data 101 Protected : Ultrasonic Object Detection and Processing Front Sensor 5 Echo Distance 2";
BA_ "SignalLongName" SG_ 180 UODPFrtSnsr5EchoDist3 "Serial Data 101 Protected : Ultrasonic Object Detection and Processing Front Sensor 5 Echo Distance 3";
BA_ "SignalLongName" SG_ 180 UODPFrtSnsr5EchoQlty1 "Serial Data 101 Protected : Ultrasonic Object Detection and Processing Front Sensor 5 Echo Quality 1";
BA_ "SignalLongName" SG_ 180 UODPFrtSnsr5EchoQlty3 "Serial Data 101 Protected : Ultrasonic Object Detection and Processing Front Sensor 5 Echo Quality 3";
BA_ "SignalLongName" SG_ 180 UODPFrtSnsr5EchoQlty2 "Serial Data 101 Protected : Ultrasonic Object Detection and Processing Front Sensor 5 Echo Quality 2";
BA_ "SignalLongName" SG_ 180 UODPFrtSnsr6EchoDist1 "Serial Data 101 Protected : Ultrasonic Object Detection and Processing Front Sensor 6 Echo Distance 1";
BA_ "SignalType" SG_ 180 UODPFrtSnsr5EchoSnsrMode "ENM";
BA_ "SignalLongName" SG_ 180 UODPFrtSnsr5EchoSnsrMode "Serial Data 101 Protected : Ultrasonic Object Detection and Processing Front Sensor 5 Echo Sensor Mode";
BA_ "SignalType" SG_ 180 UODPFrtSnsr5EchoSnsrDatUsg "ENM";
BA_ "SignalLongName" SG_ 180 UODPFrtSnsr5EchoSnsrDatUsg "Serial Data 101 Protected : Ultrasonic Object Detection and Processing Front Sensor 5 Echo Sensor Data Usage";
BA_ "SignalLongName" SG_ 180 UODPFrtSnsr6EchoDist2 "Serial Data 101 Protected : Ultrasonic Object Detection and Processing Front Sensor 6 Echo Distance 2";
BA_ "SignalLongName" SG_ 180 UODPFrtSnsr6EchoDist3 "Serial Data 101 Protected : Ultrasonic Object Detection and Processing Front Sensor 6 Echo Distance 3";
BA_ "SignalLongName" SG_ 180 UODPFrtSnsr6EchoQlty1 "Serial Data 101 Protected : Ultrasonic Object Detection and Processing Front Sensor 6 Echo Quality 1";
BA_ "SignalLongName" SG_ 180 UODPFrtSnsr6EchoQlty3 "Serial Data 101 Protected : Ultrasonic Object Detection and Processing Front Sensor 6 Echo Quality 3";
BA_ "SignalLongName" SG_ 180 UODPFrtSnsr6EchoQlty2 "Serial Data 101 Protected : Ultrasonic Object Detection and Processing Front Sensor 6 Echo Quality 2";
BA_ "SignalType" SG_ 180 UODPFrtModSts "ENM";
BA_ "SignalLongName" SG_ 180 UODPFrtModSts "Serial Data 101 Protected : Ultrasonic Object Detection and Processing Front Module Status";
BA_ "SignalType" SG_ 180 UODPSnsAutoPrkAval "ENM";
BA_ "SignalLongName" SG_ 180 UODPSnsAutoPrkAval "Serial Data 101 Protected : Ultrasonic Object Detection and Processing Sensing for Automated Parking Available";
BA_ "SignalType" SG_ 180 UODPFrtSnsr6EchoSnsrMode "ENM";
BA_ "SignalLongName" SG_ 180 UODPFrtSnsr6EchoSnsrMode "Serial Data 101 Protected : Ultrasonic Object Detection and Processing Front Sensor 6 Echo Sensor Mode";
BA_ "SignalType" SG_ 180 UODPFrtSnsr6EchoSnsrDatUsg "ENM";
BA_ "SignalLongName" SG_ 180 UODPFrtSnsr6EchoSnsrDatUsg "Serial Data 101 Protected : Ultrasonic Object Detection and Processing Front Sensor 6 Echo Sensor Data Usage";
BA_ "SignalLongName" SG_ 180 SD101P_ARC "Serial Data 101 Protected : Alive Rolling Count";
BA_ "SignalLongName" SG_ 883 SrlDat102_PCSM "Serial Data 102 Protected Counter Sync Message";
BA_ "SignalLongName" SG_ 532 SD102P_MAC "Serial Data 102 Protected : MAC";
BA_ "SignalLongName" SG_ 532 SD102P_FCnt "Serial Data 102 Protected : Freshness Counter";
BA_ "SignalLongName" SG_ 532 UODPRrEchoAcqTmStm "Serial Data 102 Protected : Ultrasonic Object Detection and Processing Rear Echo Acquisition Time Stamp";
BA_ "SignalLongName" SG_ 532 UODPRrSnsr1EchoDist1 "Serial Data 102 Protected : Ultrasonic Object Detection and Processing Rear Sensor 1 Echo Distance 1";
BA_ "SignalType" SG_ 532 UODPRrEchoAcqTmStm_Inv "ENM";
BA_ "SignalLongName" SG_ 532 UODPRrEchoAcqTmStm_Inv "Serial Data 102 Protected : Ultrasonic Object Detection and Processing Rear Echo Acquisition Time Stamp Invalid";
BA_ "SignalLongName" SG_ 532 UODPRrSnsr1EchoDist2 "Serial Data 102 Protected : Ultrasonic Object Detection and Processing Rear Sensor 1 Echo Distance 2";
BA_ "SignalLongName" SG_ 532 UODPRrSnsr1EchoDist3 "Serial Data 102 Protected : Ultrasonic Object Detection and Processing Rear Sensor 1 Echo Distance 3";
BA_ "SignalLongName" SG_ 532 UODPRrSnsr1EchoQlty1 "Serial Data 102 Protected : Ultrasonic Object Detection and Processing Rear Sensor 1 Echo Quality 1";
BA_ "SignalLongName" SG_ 532 UODPRrSnsr1EchoQlty3 "Serial Data 102 Protected : Ultrasonic Object Detection and Processing Rear Sensor 1 Echo Quality 3";
BA_ "SignalLongName" SG_ 532 UODPRrSnsr1EchoQlty2 "Serial Data 102 Protected : Ultrasonic Object Detection and Processing Rear Sensor 1 Echo Quality 2";
BA_ "SignalLongName" SG_ 532 UODPRrSnsr2EchoDist1 "Serial Data 102 Protected : Ultrasonic Object Detection and Processing Rear Sensor 2 Echo Distance 1";
BA_ "SignalType" SG_ 532 UODPRrSnsr1EchoSnsrMode "ENM";
BA_ "SignalLongName" SG_ 532 UODPRrSnsr1EchoSnsrMode "Serial Data 102 Protected : Ultrasonic Object Detection and Processing Rear Sensor 1 Echo Sensor Mode";
BA_ "SignalType" SG_ 532 UODPRrSnsr1EchoSnsrDatUsg "ENM";
BA_ "SignalLongName" SG_ 532 UODPRrSnsr1EchoSnsrDatUsg "Serial Data 102 Protected : Ultrasonic Object Detection and Processing Rear Sensor 1 Echo Sensor Data Usage";
BA_ "SignalLongName" SG_ 532 UODPRrSnsr2EchoDist2 "Serial Data 102 Protected : Ultrasonic Object Detection and Processing Rear Sensor 2 Echo Distance 2";
BA_ "SignalLongName" SG_ 532 UODPRrSnsr2EchoDist3 "Serial Data 102 Protected : Ultrasonic Object Detection and Processing Rear Sensor 2 Echo Distance 3";
BA_ "SignalLongName" SG_ 532 UODPRrSnsr2EchoQlty1 "Serial Data 102 Protected : Ultrasonic Object Detection and Processing Rear Sensor 2 Echo Quality 1";
BA_ "SignalLongName" SG_ 532 UODPRrSnsr2EchoQlty3 "Serial Data 102 Protected : Ultrasonic Object Detection and Processing Rear Sensor 2 Echo Quality 3";
BA_ "SignalLongName" SG_ 532 UODPRrSnsr2EchoQlty2 "Serial Data 102 Protected : Ultrasonic Object Detection and Processing Rear Sensor 2 Echo Quality 2";
BA_ "SignalLongName" SG_ 532 UODPRrSnsr3EchoDist1 "Serial Data 102 Protected : Ultrasonic Object Detection and Processing Rear Sensor 3 Echo Distance 1";
BA_ "SignalType" SG_ 532 UODPRrSnsr2EchoSnsrMode "ENM";
BA_ "SignalLongName" SG_ 532 UODPRrSnsr2EchoSnsrMode "Serial Data 102 Protected : Ultrasonic Object Detection and Processing Rear Sensor 2 Echo Sensor Mode";
BA_ "SignalType" SG_ 532 UODPRrSnsr2EchoSnsrDatUsg "ENM";
BA_ "SignalLongName" SG_ 532 UODPRrSnsr2EchoSnsrDatUsg "Serial Data 102 Protected : Ultrasonic Object Detection and Processing Rear Sensor 2 Echo Sensor Data Usage";
BA_ "SignalLongName" SG_ 532 UODPRrSnsr3EchoDist2 "Serial Data 102 Protected : Ultrasonic Object Detection and Processing Rear Sensor 3 Echo Distance 2";
BA_ "SignalLongName" SG_ 532 UODPRrSnsr3EchoDist3 "Serial Data 102 Protected : Ultrasonic Object Detection and Processing Rear Sensor 3 Echo Distance 3";
BA_ "SignalLongName" SG_ 532 UODPRrSnsr3EchoQlty1 "Serial Data 102 Protected : Ultrasonic Object Detection and Processing Rear Sensor 3 Echo Quality 1";
BA_ "SignalLongName" SG_ 532 UODPRrSnsr3EchoQlty3 "Serial Data 102 Protected : Ultrasonic Object Detection and Processing Rear Sensor 3 Echo Quality 3";
BA_ "SignalLongName" SG_ 532 UODPRrSnsr3EchoQlty2 "Serial Data 102 Protected : Ultrasonic Object Detection and Processing Rear Sensor 3 Echo Quality 2";
BA_ "SignalLongName" SG_ 532 UODPRrSnsr4EchoDist1 "Serial Data 102 Protected : Ultrasonic Object Detection and Processing Rear Sensor 4 Echo Distance 1";
BA_ "SignalType" SG_ 532 UODPRrSnsr3EchoSnsrMode "ENM";
BA_ "SignalLongName" SG_ 532 UODPRrSnsr3EchoSnsrMode "Serial Data 102 Protected : Ultrasonic Object Detection and Processing Rear Sensor 3 Echo Sensor Mode";
BA_ "SignalType" SG_ 532 UODPRrSnsr3EchoSnsrDatUsg "ENM";
BA_ "SignalLongName" SG_ 532 UODPRrSnsr3EchoSnsrDatUsg "Serial Data 102 Protected : Ultrasonic Object Detection and Processing Rear Sensor 3 Echo Sensor Data Usage";
BA_ "SignalLongName" SG_ 532 UODPRrSnsr4EchoDist2 "Serial Data 102 Protected : Ultrasonic Object Detection and Processing Rear Sensor 4 Echo Distance 2";
BA_ "SignalLongName" SG_ 532 UODPRrSnsr4EchoDist3 "Serial Data 102 Protected : Ultrasonic Object Detection and Processing Rear Sensor 4 Echo Distance 3";
BA_ "SignalLongName" SG_ 532 UODPRrSnsr4EchoQlty1 "Serial Data 102 Protected : Ultrasonic Object Detection and Processing Rear Sensor 4 Echo Quality 1";
BA_ "SignalLongName" SG_ 532 UODPRrSnsr4EchoQlty3 "Serial Data 102 Protected : Ultrasonic Object Detection and Processing Rear Sensor 4 Echo Quality 3";
BA_ "SignalLongName" SG_ 532 UODPRrSnsr4EchoQlty2 "Serial Data 102 Protected : Ultrasonic Object Detection and Processing Rear Sensor 4 Echo Quality 2";
BA_ "SignalLongName" SG_ 532 UODPRrSnsr5EchoDist1 "Serial Data 102 Protected : Ultrasonic Object Detection and Processing Rear Sensor 5 Echo Distance 1";
BA_ "SignalType" SG_ 532 UODPRrSnsr4EchoSnsrMode "ENM";
BA_ "SignalLongName" SG_ 532 UODPRrSnsr4EchoSnsrMode "Serial Data 102 Protected : Ultrasonic Object Detection and Processing Rear Sensor 4 Echo Sensor Mode";
BA_ "SignalType" SG_ 532 UODPRrSnsr4EchoSnsrDatUsg "ENM";
BA_ "SignalLongName" SG_ 532 UODPRrSnsr4EchoSnsrDatUsg "Serial Data 102 Protected : Ultrasonic Object Detection and Processing Rear Sensor 4 Echo Sensor Data Usage";
BA_ "SignalLongName" SG_ 532 UODPRrSnsr5EchoDist2 "Serial Data 102 Protected : Ultrasonic Object Detection and Processing Rear Sensor 5 Echo Distance 2";
BA_ "SignalLongName" SG_ 532 UODPRrSnsr5EchoDist3 "Serial Data 102 Protected : Ultrasonic Object Detection and Processing Rear Sensor 5 Echo Distance 3";
BA_ "SignalLongName" SG_ 532 UODPRrSnsr5EchoQlty1 "Serial Data 102 Protected : Ultrasonic Object Detection and Processing Rear Sensor 5 Echo Quality 1";
BA_ "SignalLongName" SG_ 532 UODPRrSnsr5EchoQlty3 "Serial Data 102 Protected : Ultrasonic Object Detection and Processing Rear Sensor 5 Echo Quality 3";
BA_ "SignalLongName" SG_ 532 UODPRrSnsr5EchoQlty2 "Serial Data 102 Protected : Ultrasonic Object Detection and Processing Rear Sensor 5 Echo Quality 2";
BA_ "SignalLongName" SG_ 532 UODPRrSnsr6EchoDist1 "Serial Data 102 Protected : Ultrasonic Object Detection and Processing Rear Sensor 6 Echo Distance 1";
BA_ "SignalType" SG_ 532 UODPRrSnsr5EchoSnsrMode "ENM";
BA_ "SignalLongName" SG_ 532 UODPRrSnsr5EchoSnsrMode "Serial Data 102 Protected : Ultrasonic Object Detection and Processing Rear Sensor 5 Echo Sensor Mode";
BA_ "SignalType" SG_ 532 UODPRrSnsr5EchoSnsrDatUsg "ENM";
BA_ "SignalLongName" SG_ 532 UODPRrSnsr5EchoSnsrDatUsg "Serial Data 102 Protected : Ultrasonic Object Detection and Processing Rear Sensor 5 Echo Sensor Data Usage";
BA_ "SignalLongName" SG_ 532 UODPRrSnsr6EchoDist2 "Serial Data 102 Protected : Ultrasonic Object Detection and Processing Rear Sensor 6 Echo Distance 2";
BA_ "SignalLongName" SG_ 532 UODPRrSnsr6EchoDist3 "Serial Data 102 Protected : Ultrasonic Object Detection and Processing Rear Sensor 6 Echo Distance 3";
BA_ "SignalLongName" SG_ 532 UODPRrSnsr6EchoQlty1 "Serial Data 102 Protected : Ultrasonic Object Detection and Processing Rear Sensor 6 Echo Quality 1";
BA_ "SignalLongName" SG_ 532 UODPRrSnsr6EchoQlty3 "Serial Data 102 Protected : Ultrasonic Object Detection and Processing Rear Sensor 6 Echo Quality 3";
BA_ "SignalLongName" SG_ 532 UODPRrSnsr6EchoQlty2 "Serial Data 102 Protected : Ultrasonic Object Detection and Processing Rear Sensor 6 Echo Quality 2";
BA_ "SignalLongName" SG_ 532 SD102P_ARC "Serial Data 102 Protected : Alive Rolling Count";
BA_ "SignalType" SG_ 532 UODPRrModSts "ENM";
BA_ "SignalLongName" SG_ 532 UODPRrModSts "Serial Data 102 Protected : Ultrasonic Object Detection and Processing Rear Module Status";
BA_ "SignalType" SG_ 532 UODPRrSnsr6EchoSnsrMode "ENM";
BA_ "SignalLongName" SG_ 532 UODPRrSnsr6EchoSnsrMode "Serial Data 102 Protected : Ultrasonic Object Detection and Processing Rear Sensor 6 Echo Sensor Mode";
BA_ "SignalType" SG_ 532 UODPRrSnsr6EchoSnsrDatUsg "ENM";
BA_ "SignalLongName" SG_ 532 UODPRrSnsr6EchoSnsrDatUsg "Serial Data 102 Protected : Ultrasonic Object Detection and Processing Rear Sensor 6 Echo Sensor Data Usage";
BA_ "SignalLongName" SG_ 1326 SrlDat104BrstGrp1_PCSM "Serial Data 104 Burst Group 1 Protected Counter Sync Message";
BA_ "SignalLongName" SG_ 594 SD104BG1P_MAC "Serial Data 104 Burst Group 1 Protected : MAC";
BA_ "SignalLongName" SG_ 594 SD104BG1P_FCnt "Serial Data 104 Burst Group 1 Protected : Freshness Counter";
BA_ "SignalLongName" SG_ 594 UODPLoclzdObj10PstnP1X "Serial Data 104 Burst Group 1 Protected : Ultrasonic Object Detection and Processing Localized Object 10 Position P1_X";
BA_ "SignalType" SG_ 594 UODPLoclzdObj10Hght "ENM";
BA_ "SignalLongName" SG_ 594 UODPLoclzdObj10Hght "Serial Data 104 Burst Group 1 Protected : Ultrasonic Object Detection and Processing Localized Object 10 Height";
BA_ "SignalLongName" SG_ 594 SD104BG1P_BrstID "Serial Data 104 Burst Group 1 Protected : Burst ID";
BA_ "SignalLongName" SG_ 594 UODPLoclzdObj10PstnP1Y "Serial Data 104 Burst Group 1 Protected : Ultrasonic Object Detection and Processing Localized Object 10 Position P1_Y";
BA_ "SignalLongName" SG_ 594 UODPLoclzdObj10PstnP2X "Serial Data 104 Burst Group 1 Protected : Ultrasonic Object Detection and Processing Localized Object 10 Position P2_X";
BA_ "SignalLongName" SG_ 594 UODPLoclzdObj10PstnP2Y "Serial Data 104 Burst Group 1 Protected : Ultrasonic Object Detection and Processing Localized Object 10 Position P2_Y";
BA_ "SignalLongName" SG_ 594 UODPLoclzdObj1PstnP1X "Serial Data 104 Burst Group 1 Protected : Ultrasonic Object Detection and Processing Localized Object 1 Position P1_X";
BA_ "SignalType" SG_ 594 UODPLoclzdObj1Hght "ENM";
BA_ "SignalLongName" SG_ 594 UODPLoclzdObj1Hght "Serial Data 104 Burst Group 1 Protected : Ultrasonic Object Detection and Processing Localized Object 1 Height";
BA_ "SignalLongName" SG_ 594 UODPLoclzdObj1PstnP1Y "Serial Data 104 Burst Group 1 Protected : Ultrasonic Object Detection and Processing Localized Object 1 Position P1_Y";
BA_ "SignalLongName" SG_ 594 UODPLoclzdObj1PstnP2X "Serial Data 104 Burst Group 1 Protected : Ultrasonic Object Detection and Processing Localized Object 1 Position P2_X";
BA_ "SignalLongName" SG_ 594 UODPLoclzdObj1PstnP2Y "Serial Data 104 Burst Group 1 Protected : Ultrasonic Object Detection and Processing Localized Object 1 Position P2_Y";
BA_ "SignalType" SG_ 594 UODPLoclzdObj2Hght "ENM";
BA_ "SignalLongName" SG_ 594 UODPLoclzdObj2Hght "Serial Data 104 Burst Group 1 Protected : Ultrasonic Object Detection and Processing Localized Object 2 Height";
BA_ "SignalLongName" SG_ 594 UODPLoclzdObj2PstnP1X "Serial Data 104 Burst Group 1 Protected : Ultrasonic Object Detection and Processing Localized Object 2 Position P1_X";
BA_ "SignalLongName" SG_ 594 UODPLoclzdObj2PstnP1Y "Serial Data 104 Burst Group 1 Protected : Ultrasonic Object Detection and Processing Localized Object 2 Position P1_Y";
BA_ "SignalLongName" SG_ 594 UODPLoclzdObj2PstnP2X "Serial Data 104 Burst Group 1 Protected : Ultrasonic Object Detection and Processing Localized Object 2 Position P2_X";
BA_ "SignalLongName" SG_ 594 UODPLoclzdObj2PstnP2Y "Serial Data 104 Burst Group 1 Protected : Ultrasonic Object Detection and Processing Localized Object 2 Position P2_Y";
BA_ "SignalLongName" SG_ 594 UODPLoclzdObj3PstnP1X "Serial Data 104 Burst Group 1 Protected : Ultrasonic Object Detection and Processing Localized Object 3 Position P1_X";
BA_ "SignalType" SG_ 594 UODPLoclzdObj3Hght "ENM";
BA_ "SignalLongName" SG_ 594 UODPLoclzdObj3Hght "Serial Data 104 Burst Group 1 Protected : Ultrasonic Object Detection and Processing Localized Object 3 Height";
BA_ "SignalLongName" SG_ 594 UODPLoclzdObj3PstnP1Y "Serial Data 104 Burst Group 1 Protected : Ultrasonic Object Detection and Processing Localized Object 3 Position P1_Y";
BA_ "SignalLongName" SG_ 594 UODPLoclzdObj3PstnP2X "Serial Data 104 Burst Group 1 Protected : Ultrasonic Object Detection and Processing Localized Object 3 Position P2_X";
BA_ "SignalLongName" SG_ 594 UODPLoclzdObj3PstnP2Y "Serial Data 104 Burst Group 1 Protected : Ultrasonic Object Detection and Processing Localized Object 3 Position P2_Y";
BA_ "SignalLongName" SG_ 594 UODPLoclzdObj4PstnP1X "Serial Data 104 Burst Group 1 Protected : Ultrasonic Object Detection and Processing Localized Object 4 Position P1_X";
BA_ "SignalType" SG_ 594 UODPLoclzdObj4Hght "ENM";
BA_ "SignalLongName" SG_ 594 UODPLoclzdObj4Hght "Serial Data 104 Burst Group 1 Protected : Ultrasonic Object Detection and Processing Localized Object 4 Height";
BA_ "SignalLongName" SG_ 594 UODPLoclzdObj4PstnP1Y "Serial Data 104 Burst Group 1 Protected : Ultrasonic Object Detection and Processing Localized Object 4 Position P1_Y";
BA_ "SignalLongName" SG_ 594 UODPLoclzdObj4PstnP2X "Serial Data 104 Burst Group 1 Protected : Ultrasonic Object Detection and Processing Localized Object 4 Position P2_X";
BA_ "SignalLongName" SG_ 594 UODPLoclzdObj4PstnP2Y "Serial Data 104 Burst Group 1 Protected : Ultrasonic Object Detection and Processing Localized Object 4 Position P2_Y";
BA_ "SignalLongName" SG_ 594 UODPLoclzdObj5PstnP1X "Serial Data 104 Burst Group 1 Protected : Ultrasonic Object Detection and Processing Localized Object 5 Position P1_X";
BA_ "SignalType" SG_ 594 UODPLoclzdObj5Hght "ENM";
BA_ "SignalLongName" SG_ 594 UODPLoclzdObj5Hght "Serial Data 104 Burst Group 1 Protected : Ultrasonic Object Detection and Processing Localized Object 5 Height";
BA_ "SignalLongName" SG_ 594 UODPLoclzdObj5PstnP1Y "Serial Data 104 Burst Group 1 Protected : Ultrasonic Object Detection and Processing Localized Object 5 Position P1_Y";
BA_ "SignalLongName" SG_ 594 UODPLoclzdObj5PstnP2X "Serial Data 104 Burst Group 1 Protected : Ultrasonic Object Detection and Processing Localized Object 5 Position P2_X";
BA_ "SignalLongName" SG_ 594 UODPLoclzdObj5PstnP2Y "Serial Data 104 Burst Group 1 Protected : Ultrasonic Object Detection and Processing Localized Object 5 Position P2_Y";
BA_ "SignalType" SG_ 594 UODPLoclzdObj6Hght "ENM";
BA_ "SignalLongName" SG_ 594 UODPLoclzdObj6Hght "Serial Data 104 Burst Group 1 Protected : Ultrasonic Object Detection and Processing Localized Object 6 Height";
BA_ "SignalLongName" SG_ 594 UODPLoclzdObj6PstnP1X "Serial Data 104 Burst Group 1 Protected : Ultrasonic Object Detection and Processing Localized Object 6 Position P1_X";
BA_ "SignalLongName" SG_ 594 UODPLoclzdObj6PstnP1Y "Serial Data 104 Burst Group 1 Protected : Ultrasonic Object Detection and Processing Localized Object 6 Position P1_Y";
BA_ "SignalLongName" SG_ 594 UODPLoclzdObj6PstnP2X "Serial Data 104 Burst Group 1 Protected : Ultrasonic Object Detection and Processing Localized Object 6 Position P2_X";
BA_ "SignalLongName" SG_ 594 UODPLoclzdObj6PstnP2Y "Serial Data 104 Burst Group 1 Protected : Ultrasonic Object Detection and Processing Localized Object 6 Position P2_Y";
BA_ "SignalLongName" SG_ 594 UODPLoclzdObj7PstnP1X "Serial Data 104 Burst Group 1 Protected : Ultrasonic Object Detection and Processing Localized Object 7 Position P1_X";
BA_ "SignalType" SG_ 594 UODPLoclzdObj7Hght "ENM";
BA_ "SignalLongName" SG_ 594 UODPLoclzdObj7Hght "Serial Data 104 Burst Group 1 Protected : Ultrasonic Object Detection and Processing Localized Object 7 Height";
BA_ "SignalLongName" SG_ 594 UODPLoclzdObj7PstnP1Y "Serial Data 104 Burst Group 1 Protected : Ultrasonic Object Detection and Processing Localized Object 7 Position P1_Y";
BA_ "SignalLongName" SG_ 594 UODPLoclzdObj7PstnP2X "Serial Data 104 Burst Group 1 Protected : Ultrasonic Object Detection and Processing Localized Object 7 Position P2_X";
BA_ "SignalLongName" SG_ 594 UODPLoclzdObj7PstnP2Y "Serial Data 104 Burst Group 1 Protected : Ultrasonic Object Detection and Processing Localized Object 7 Position P2_Y";
BA_ "SignalLongName" SG_ 594 UODPLoclzdObj8PstnP1X "Serial Data 104 Burst Group 1 Protected : Ultrasonic Object Detection and Processing Localized Object 8 Position P1_X";
BA_ "SignalType" SG_ 594 UODPLoclzdObj8Hght "ENM";
BA_ "SignalLongName" SG_ 594 UODPLoclzdObj8Hght "Serial Data 104 Burst Group 1 Protected : Ultrasonic Object Detection and Processing Localized Object 8 Height";
BA_ "SignalLongName" SG_ 594 UODPLoclzdObj8PstnP1Y "Serial Data 104 Burst Group 1 Protected : Ultrasonic Object Detection and Processing Localized Object 8 Position P1_Y";
BA_ "SignalLongName" SG_ 594 UODPLoclzdObj8PstnP2X "Serial Data 104 Burst Group 1 Protected : Ultrasonic Object Detection and Processing Localized Object 8 Position P2_X";
BA_ "SignalLongName" SG_ 594 UODPLoclzdObj8PstnP2Y "Serial Data 104 Burst Group 1 Protected : Ultrasonic Object Detection and Processing Localized Object 8 Position P2_Y";
BA_ "SignalLongName" SG_ 594 UODPLoclzdObj9PstnP1X "Serial Data 104 Burst Group 1 Protected : Ultrasonic Object Detection and Processing Localized Object 9 Position P1_X";
BA_ "SignalType" SG_ 594 UODPLoclzdObj9Hght "ENM";
BA_ "SignalLongName" SG_ 594 UODPLoclzdObj9Hght "Serial Data 104 Burst Group 1 Protected : Ultrasonic Object Detection and Processing Localized Object 9 Height";
BA_ "SignalLongName" SG_ 594 UODPLoclzdObj9PstnP1Y "Serial Data 104 Burst Group 1 Protected : Ultrasonic Object Detection and Processing Localized Object 9 Position P1_Y";
BA_ "SignalLongName" SG_ 594 UODPLoclzdObj9PstnP2X "Serial Data 104 Burst Group 1 Protected : Ultrasonic Object Detection and Processing Localized Object 9 Position P2_X";
BA_ "SignalLongName" SG_ 594 UODPLoclzdObj9PstnP2Y "Serial Data 104 Burst Group 1 Protected : Ultrasonic Object Detection and Processing Localized Object 9 Position P2_Y";
BA_ "SignalLongName" SG_ 594 SD104BG1P_ARC "Serial Data 104 Burst Group 1 Protected : Alive Rolling Count";
BA_ "SignalLongName" SG_ 593 UODPLoclzdObj10Cnfd "Serial Data 104 Burst Group 2 Protected : Ultrasonic Object Detection and Processing Localized Object 10 Confidence";
BA_ "SignalLongName" SG_ 593 SD104BG2P_BrstID "Serial Data 104 Burst Group 2 Protected : Burst ID";
BA_ "SignalType" SG_ 593 UODPLoclzdObj10Typ "ENM";
BA_ "SignalLongName" SG_ 593 UODPLoclzdObj10Typ "Serial Data 104 Burst Group 2 Protected : Ultrasonic Object Detection and Processing Localized Object 10 Type";
BA_ "SignalLongName" SG_ 593 UODPLoclzdObj10HghtCnfd "Serial Data 104 Burst Group 2 Protected : Ultrasonic Object Detection and Processing Localized Object 10 Height Confidence";
BA_ "SignalLongName" SG_ 593 UODPLoclzdObj1HghtCnfd "Serial Data 104 Burst Group 2 Protected : Ultrasonic Object Detection and Processing Localized Object 1 Height Confidence";
BA_ "SignalLongName" SG_ 593 UODPLoclzdObj1Cnfd "Serial Data 104 Burst Group 2 Protected : Ultrasonic Object Detection and Processing Localized Object 1 Confidence";
BA_ "SignalType" SG_ 593 UODPLoclzdObj1Typ "ENM";
BA_ "SignalLongName" SG_ 593 UODPLoclzdObj1Typ "Serial Data 104 Burst Group 2 Protected : Ultrasonic Object Detection and Processing Localized Object 1 Type";
BA_ "SignalLongName" SG_ 593 UODPLoclzdObj2HghtCnfd "Serial Data 104 Burst Group 2 Protected : Ultrasonic Object Detection and Processing Localized Object 2 Height Confidence";
BA_ "SignalLongName" SG_ 593 UODPLoclzdObj2Cnfd "Serial Data 104 Burst Group 2 Protected : Ultrasonic Object Detection and Processing Localized Object 2 Confidence";
BA_ "SignalLongName" SG_ 593 UODPLoclzdObj3Cnfd "Serial Data 104 Burst Group 2 Protected : Ultrasonic Object Detection and Processing Localized Object 3 Confidence";
BA_ "SignalType" SG_ 593 UODPLoclzdObj2Typ "ENM";
BA_ "SignalLongName" SG_ 593 UODPLoclzdObj2Typ "Serial Data 104 Burst Group 2 Protected : Ultrasonic Object Detection and Processing Localized Object 2 Type";
BA_ "SignalLongName" SG_ 593 UODPLoclzdObj3HghtCnfd "Serial Data 104 Burst Group 2 Protected : Ultrasonic Object Detection and Processing Localized Object 3 Height Confidence";
BA_ "SignalLongName" SG_ 593 UODPLoclzdObj4Cnfd "Serial Data 104 Burst Group 2 Protected : Ultrasonic Object Detection and Processing Localized Object 4 Confidence";
BA_ "SignalType" SG_ 593 UODPLoclzdObj3Typ "ENM";
BA_ "SignalLongName" SG_ 593 UODPLoclzdObj3Typ "Serial Data 104 Burst Group 2 Protected : Ultrasonic Object Detection and Processing Localized Object 3 Type";
BA_ "SignalLongName" SG_ 593 UODPLoclzdObj4HghtCnfd "Serial Data 104 Burst Group 2 Protected : Ultrasonic Object Detection and Processing Localized Object 4 Height Confidence";
BA_ "SignalLongName" SG_ 593 UODPLoclzdObj5Cnfd "Serial Data 104 Burst Group 2 Protected : Ultrasonic Object Detection and Processing Localized Object 5 Confidence";
BA_ "SignalType" SG_ 593 UODPLoclzdObj4Typ "ENM";
BA_ "SignalLongName" SG_ 593 UODPLoclzdObj4Typ "Serial Data 104 Burst Group 2 Protected : Ultrasonic Object Detection and Processing Localized Object 4 Type";
BA_ "SignalLongName" SG_ 593 UODPLoclzdObj5HghtCnfd "Serial Data 104 Burst Group 2 Protected : Ultrasonic Object Detection and Processing Localized Object 5 Height Confidence";
BA_ "SignalLongName" SG_ 593 UODPLoclzdObj6Cnfd "Serial Data 104 Burst Group 2 Protected : Ultrasonic Object Detection and Processing Localized Object 6 Confidence";
BA_ "SignalType" SG_ 593 UODPLoclzdObj5Typ "ENM";
BA_ "SignalLongName" SG_ 593 UODPLoclzdObj5Typ "Serial Data 104 Burst Group 2 Protected : Ultrasonic Object Detection and Processing Localized Object 5 Type";
BA_ "SignalLongName" SG_ 593 UODPLoclzdObj6HghtCnfd "Serial Data 104 Burst Group 2 Protected : Ultrasonic Object Detection and Processing Localized Object 6 Height Confidence";
BA_ "SignalLongName" SG_ 593 UODPLoclzdObj7Cnfd "Serial Data 104 Burst Group 2 Protected : Ultrasonic Object Detection and Processing Localized Object 7 Confidence";
BA_ "SignalType" SG_ 593 UODPLoclzdObj6Typ "ENM";
BA_ "SignalLongName" SG_ 593 UODPLoclzdObj6Typ "Serial Data 104 Burst Group 2 Protected : Ultrasonic Object Detection and Processing Localized Object 6 Type";
BA_ "SignalType" SG_ 593 UODPLoclzdObj7Typ "ENM";
BA_ "SignalLongName" SG_ 593 UODPLoclzdObj7Typ "Serial Data 104 Burst Group 2 Protected : Ultrasonic Object Detection and Processing Localized Object 7 Type";
BA_ "SignalLongName" SG_ 593 UODPLoclzdObj7HghtCnfd "Serial Data 104 Burst Group 2 Protected : Ultrasonic Object Detection and Processing Localized Object 7 Height Confidence";
BA_ "SignalLongName" SG_ 593 UODPLoclzdObj8Cnfd "Serial Data 104 Burst Group 2 Protected : Ultrasonic Object Detection and Processing Localized Object 8 Confidence";
BA_ "SignalType" SG_ 593 UODPLoclzdObj8Typ "ENM";
BA_ "SignalLongName" SG_ 593 UODPLoclzdObj8Typ "Serial Data 104 Burst Group 2 Protected : Ultrasonic Object Detection and Processing Localized Object 8 Type";
BA_ "SignalLongName" SG_ 593 UODPLoclzdObj8HghtCnfd "Serial Data 104 Burst Group 2 Protected : Ultrasonic Object Detection and Processing Localized Object 8 Height Confidence";
BA_ "SignalLongName" SG_ 593 UODPLoclzdObj9HghtCnfd "Serial Data 104 Burst Group 2 Protected : Ultrasonic Object Detection and Processing Localized Object 9 Height Confidence";
BA_ "SignalLongName" SG_ 593 UODPLoclzdObj9Cnfd "Serial Data 104 Burst Group 2 Protected : Ultrasonic Object Detection and Processing Localized Object 9 Confidence";
BA_ "SignalType" SG_ 593 UODPLoclzdObj9Typ "ENM";
BA_ "SignalLongName" SG_ 593 UODPLoclzdObj9Typ "Serial Data 104 Burst Group 2 Protected : Ultrasonic Object Detection and Processing Localized Object 9 Type";
BA_ "SignalLongName" SG_ 882 SrlDat105_PCSM "Serial Data 105 Protected Counter Sync Message";
BA_ "SignalLongName" SG_ 33 SD105P_MAC "Serial Data 105 Protected : MAC";
BA_ "SignalLongName" SG_ 33 SD105P_FCnt "Serial Data 105 Protected : Freshness Counter";
BA_ "SignalLongName" SG_ 33 SD105P_Filler "Serial Data 105 Protected : Filler";
BA_ "SignalType" SG_ 33 SuprRmtPrkFirngModeReq "ENM";
BA_ "SignalLongName" SG_ 33 SuprRmtPrkFirngModeReq "Serial Data 105 Protected : Supervised Remote Parking Firing Mode Request";
BA_ "SignalType" SG_ 33 AutoPrkUltrsncObjSnsActvnReqd "ENM";
BA_ "SignalLongName" SG_ 33 AutoPrkUltrsncObjSnsActvnReqd "Serial Data 105 Protected : Automated Parking For Ultrasonic Object Sensing Activation Requested";
BA_ "SignalLongName" SG_ 33 SD105P_ARC "Serial Data 105 Protected : Alive Rolling Count";
BA_ "SignalLongName" SG_ 540 SrlDat197_PCSM "Serial Data 197 Protected Counter Sync Message";
BA_ "SignalLongName" SG_ 23 SD197P_MAC "Serial Data 197 Protected : MAC";
BA_ "SignalLongName" SG_ 23 SD197P_FCnt "Serial Data 197 Protected : Freshness Counter";
BA_ "SignalLongName" SG_ 23 SRRLRCRODPTOVYawRate "Serial Data 197 Protected : Short Range Radar Left Rear / Center Object Detection and Processing Trailer Object Variance Yaw Rate";
BA_ "SignalLongName" SG_ 23 SRRLRCRODPTrObjYawRate "Serial Data 197 Protected : Short Range Radar Left Rear / Center Object Detection and Processing Trailer Object Yaw Rate";
BA_ "SignalLongName" SG_ 23 SRRLRCRODPTrObjOrntn "Serial Data 197 Protected : Short Range Radar Left Rear / Center Object Detection and Processing Trailer Object Orientation";
BA_ "SignalLongName" SG_ 23 SRRLRCRODPTODTrHtchTrFrt "Serial Data 197 Protected : Short Range Radar Left Rear / Center Object Detection and Processing Trailer Object Distance Trailer Hitch To Trailer Front";
BA_ "SignalLongName" SG_ 23 SRRLRCRODPTOVLgth "Serial Data 197 Protected : Short Range Radar Left Rear / Center Object Detection and Processing Trailer Object Variance Length";
BA_ "SignalLongName" SG_ 23 SRRLRCRODPTOVOrntn "Serial Data 197 Protected : Short Range Radar Left Rear / Center Object Detection and Processing Trailer Object Variance Orientation";
BA_ "SignalLongName" SG_ 23 SRRLRCRODPTOVWdth "Serial Data 197 Protected : Short Range Radar Left Rear / Center Object Detection and Processing Trailer Object Variance Width";
BA_ "SignalLongName" SG_ 23 SRRLRCRODPTrObjLgth "Serial Data 197 Protected : Short Range Radar Left Rear / Center Object Detection and Processing Trailer Object Length";
BA_ "SignalLongName" SG_ 23 SRRLRCRODPTODVhFrtAxVhHtch "Serial Data 197 Protected : Short Range Radar Left Rear / Center Object Detection and Processing Trailer Object Distance Vehicle Front Axle To Vehicle Hitch";
BA_ "SignalLongName" SG_ 23 SRRLRCRODPTODTrHtchTrAx "Serial Data 197 Protected : Short Range Radar Left Rear / Center Object Detection and Processing Trailer Object Distance Trailer Hitch To Trailer Axle";
BA_ "SignalLongName" SG_ 23 SRRLRCRODPTOEExistPrblty "Serial Data 197 Protected : Short Range Radar Left Rear / Center Object Detection and Processing Trailer Object Edge Existence Probability";
BA_ "SignalLongName" SG_ 23 SRRLRCRODPTOPDtnPrblty "Serial Data 197 Protected : Short Range Radar Left Rear / Center Object Detection and Processing Trailer Object Presence Detection Probability";
BA_ "SignalLongName" SG_ 23 SRRLRCRODPTrObjQlty "Serial Data 197 Protected : Short Range Radar Left Rear / Center Object Detection and Processing Trailer Object Quality";
BA_ "SignalLongName" SG_ 23 SRRLRCRODPTOVDTrHtchTrAx "Serial Data 197 Protected : Short Range Radar Left Rear / Center Object Detection and Processing Trailer Object Variance Distance Trailer Hitch To Trailer Axle";
BA_ "SignalLongName" SG_ 23 SRRLRCRODPTOVDVhFrtAxVhHtch "Serial Data 197 Protected : Short Range Radar Left Rear / Center Object Detection and Processing Trailer Object Variance Distance Vehicle Front Axle To Vehicle Hitch";
BA_ "SignalLongName" SG_ 23 SRRLRCRODPTOVDTrHtchTrFrt "Serial Data 197 Protected : Short Range Radar Left Rear / Center Object Detection and Processing Trailer Object Variance Distance Trailer Hitch To Trailer Front";
BA_ "SignalLongName" SG_ 23 SRRLRCRODPTrObjWdth "Serial Data 197 Protected : Short Range Radar Left Rear / Center Object Detection and Processing Trailer Object Width";
BA_ "SignalType" SG_ 23 SRRLRCRODPTrObjStatInfo "ENM";
BA_ "SignalLongName" SG_ 23 SRRLRCRODPTrObjStatInfo "Serial Data 197 Protected : Short Range Radar Left Rear / Center Object Detection and Processing Trailer Object State Information";
BA_ "SignalLongName" SG_ 23 SRRLRCRODPTrObjExtrnInfo "Serial Data 197 Protected : Short Range Radar Left Rear / Center Object Detection and Processing Trailer Object External Information";
BA_ "SignalType" SG_ 23 SRRLRCRODPTOPDtnPrblty_Inv "ENM";
BA_ "SignalLongName" SG_ 23 SRRLRCRODPTOPDtnPrblty_Inv "Serial Data 197 Protected : Short Range Radar Left Rear / Center Object Detection and Processing Trailer Object Presence Detection Probability Invalid";
BA_ "SignalType" SG_ 23 SRRLRCRODPTOEExistPrblty_Inv "ENM";
BA_ "SignalLongName" SG_ 23 SRRLRCRODPTOEExistPrblty_Inv "Serial Data 197 Protected : Short Range Radar Left Rear / Center Object Detection and Processing Trailer Object Edge Existence Probability Invalid";
BA_ "SignalType" SG_ 23 SRRLRCRODPTODVhFrtAxVhHtch_Inv "ENM";
BA_ "SignalLongName" SG_ 23 SRRLRCRODPTODVhFrtAxVhHtch_Inv "Serial Data 197 Protected : Short Range Radar Left Rear / Center Object Detection and Processing Trailer Object Distance Vehicle Front Axle To Vehicle Hitch Invalid";
BA_ "SignalType" SG_ 23 SRRLRCRODPTODTrHtchTrFrt_Inv "ENM";
BA_ "SignalLongName" SG_ 23 SRRLRCRODPTODTrHtchTrFrt_Inv "Serial Data 197 Protected : Short Range Radar Left Rear / Center Object Detection and Processing Trailer Object Distance Trailer Hitch To Trailer Front Invalid";
BA_ "SignalType" SG_ 23 SRRLRCRODPTODTrHtchTrAx_Inv "ENM";
BA_ "SignalLongName" SG_ 23 SRRLRCRODPTODTrHtchTrAx_Inv "Serial Data 197 Protected : Short Range Radar Left Rear / Center Object Detection and Processing Trailer Object Distance Trailer Hitch To Trailer Axle Invalid";
BA_ "SignalType" SG_ 23 SRRLRCRODPTrAtchdInfo "ENM";
BA_ "SignalLongName" SG_ 23 SRRLRCRODPTrAtchdInfo "Serial Data 197 Protected : Short Range Radar Left Rear / Center Object Detection and Processing Trailer Attached Information";
BA_ "SignalType" SG_ 23 SRRLRCRODPTrObjExtrnInfo_Inv "ENM";
BA_ "SignalLongName" SG_ 23 SRRLRCRODPTrObjExtrnInfo_Inv "Serial Data 197 Protected : Short Range Radar Left Rear / Center Object Detection and Processing Trailer Object External Information Invalid";
BA_ "SignalType" SG_ 23 SRRLRCRODPTOVYawRate_Inv "ENM";
BA_ "SignalLongName" SG_ 23 SRRLRCRODPTOVYawRate_Inv "Serial Data 197 Protected : Short Range Radar Left Rear / Center Object Detection and Processing Trailer Object Variance Yaw Rate Invalid";
BA_ "SignalType" SG_ 23 SRRLRCRODPTOVWdth_Inv "ENM";
BA_ "SignalLongName" SG_ 23 SRRLRCRODPTOVWdth_Inv "Serial Data 197 Protected : Short Range Radar Left Rear / Center Object Detection and Processing Trailer Object Variance Width Invalid";
BA_ "SignalType" SG_ 23 SRRLRCRODPTOVOrntn_Inv "ENM";
BA_ "SignalLongName" SG_ 23 SRRLRCRODPTOVOrntn_Inv "Serial Data 197 Protected : Short Range Radar Left Rear / Center Object Detection and Processing Trailer Object Variance Orientation Invalid";
BA_ "SignalType" SG_ 23 SRRLRCRODPTOVLgth_Inv "ENM";
BA_ "SignalLongName" SG_ 23 SRRLRCRODPTOVLgth_Inv "Serial Data 197 Protected : Short Range Radar Left Rear / Center Object Detection and Processing Trailer Object Variance Length Invalid";
BA_ "SignalType" SG_ 23 SRRLRCRODPTOVDVhFrtAxVhHtch_Inv "ENM";
BA_ "SignalLongName" SG_ 23 SRRLRCRODPTOVDVhFrtAxVhHtch_Inv "Serial Data 197 Protected : Short Range Radar Left Rear / Center Object Detection and Processing Trailer Object Variance Distance Vehicle Front Axle To Vehicle Hitch Invalid";
BA_ "SignalType" SG_ 23 SRRLRCRODPTOVDTrHtchTrFrt_Inv "ENM";
BA_ "SignalLongName" SG_ 23 SRRLRCRODPTOVDTrHtchTrFrt_Inv "Serial Data 197 Protected : Short Range Radar Left Rear / Center Object Detection and Processing Trailer Object Variance Distance Trailer Hitch To Trailer Front Invalid";
BA_ "SignalType" SG_ 23 SRRLRCRODPTOVDTrHtchTrAx_Inv "ENM";
BA_ "SignalLongName" SG_ 23 SRRLRCRODPTOVDTrHtchTrAx_Inv "Serial Data 197 Protected : Short Range Radar Left Rear / Center Object Detection and Processing Trailer Object Variance Distance Trailer Hitch To Trailer Axle Invalid";
BA_ "SignalLongName" SG_ 23 SrlDat197_Filler "Serial Data 197 Protected : Filler";
BA_ "SignalType" SG_ 23 SRRLRCRODPTrObjYawRate_Inv "ENM";
BA_ "SignalLongName" SG_ 23 SRRLRCRODPTrObjYawRate_Inv "Serial Data 197 Protected : Short Range Radar Left Rear / Center Object Detection and Processing Trailer Object Yaw Rate Invalid";
BA_ "SignalType" SG_ 23 SRRLRCRODPTrObjWdth_Inv "ENM";
BA_ "SignalLongName" SG_ 23 SRRLRCRODPTrObjWdth_Inv "Serial Data 197 Protected : Short Range Radar Left Rear / Center Object Detection and Processing Trailer Object Width Invalid";
BA_ "SignalType" SG_ 23 SRRLRCRODPTrObjQlty_Inv "ENM";
BA_ "SignalLongName" SG_ 23 SRRLRCRODPTrObjQlty_Inv "Serial Data 197 Protected : Short Range Radar Left Rear / Center Object Detection and Processing Trailer Object Quality Invalid";
BA_ "SignalType" SG_ 23 SRRLRCRODPTrObjOrntn_Inv "ENM";
BA_ "SignalLongName" SG_ 23 SRRLRCRODPTrObjOrntn_Inv "Serial Data 197 Protected : Short Range Radar Left Rear / Center Object Detection and Processing Trailer Object Orientation Invalid";
BA_ "SignalType" SG_ 23 SRRLRCRODPTrObjLgth_Inv "ENM";
BA_ "SignalLongName" SG_ 23 SRRLRCRODPTrObjLgth_Inv "Serial Data 197 Protected : Short Range Radar Left Rear / Center Object Detection and Processing Trailer Object Length Invalid";
BA_ "SignalLongName" SG_ 23 SrlDat197_FillerExtnd "Serial Data 197 Protected : Filler Extended";
BA_ "SignalLongName" SG_ 23 SD197P_ARC "Serial Data 197 Protected : Alive Rolling Count";
BA_ "SignalLongName" SG_ 541 SrlDat198_PCSM "Serial Data 198 Protected Counter Sync Message";
BA_ "SignalLongName" SG_ 22 SD198P_MAC "Serial Data 198 Protected : MAC";
BA_ "SignalLongName" SG_ 22 SD198P_FCnt "Serial Data 198 Protected : Freshness Counter";
BA_ "SignalLongName" SG_ 22 SRRSLRODPTOVYawRate "Serial Data 198 Protected : Short Range Radar Side Left Rear Object Detection and Processing Trailer Object Variance Yaw Rate";
BA_ "SignalLongName" SG_ 22 SRRSLRODPTrObjYawRate "Serial Data 198 Protected : Short Range Radar Side Left Rear Object Detection and Processing Trailer Object Yaw Rate";
BA_ "SignalLongName" SG_ 22 SRRSLRODPTrObjOrntn "Serial Data 198 Protected : Short Range Radar Side Left Rear Object Detection and Processing Trailer Object Orientation";
BA_ "SignalLongName" SG_ 22 SRRSLRODPTODTrHtchTrFrt "Serial Data 198 Protected : Short Range Radar Side Left Rear Object Detection and Processing Trailer Object Distance Trailer Hitch To Trailer Front";
BA_ "SignalLongName" SG_ 22 SRRSLRODPTOVLgth "Serial Data 198 Protected : Short Range Radar Side Left Rear Object Detection and Processing Trailer Object Variance Length";
BA_ "SignalLongName" SG_ 22 SRRSLRODPTOVOrntn "Serial Data 198 Protected : Short Range Radar Side Left Rear Object Detection and Processing Trailer Object Variance Orientation";
BA_ "SignalLongName" SG_ 22 SRRSLRODPTOVWdth "Serial Data 198 Protected : Short Range Radar Side Left Rear Object Detection and Processing Trailer Object Variance Width";
BA_ "SignalLongName" SG_ 22 SRRSLRODPTrObjLgth "Serial Data 198 Protected : Short Range Radar Side Left Rear Object Detection and Processing Trailer Object Length";
BA_ "SignalLongName" SG_ 22 SRRSLRODPTODVhFrtAxVhHtch "Serial Data 198 Protected : Short Range Radar Side Left Rear Object Detection and Processing Trailer Object Distance Vehicle Front Axle To Vehicle Hitch";
BA_ "SignalLongName" SG_ 22 SRRSLRODPTODTrHtchTrAx "Serial Data 198 Protected : Short Range Radar Side Left Rear Object Detection and Processing Trailer Object Distance Trailer Hitch To Trailer Axle";
BA_ "SignalLongName" SG_ 22 SRRSLRODPTOEExistPrblty "Serial Data 198 Protected : Short Range Radar Side Left Rear Object Detection and Processing Trailer Object Edge Existence Probability";
BA_ "SignalLongName" SG_ 22 SRRSLRODPTOPDtnPrblty "Serial Data 198 Protected : Short Range Radar Side Left Rear Object Detection and Processing Trailer Object Presence Detection Probability";
BA_ "SignalLongName" SG_ 22 SRRSLRODPTrObjQlty "Serial Data 198 Protected : Short Range Radar Side Left Rear Object Detection and Processing Trailer Object Quality";
BA_ "SignalLongName" SG_ 22 SRRSLRODPTOVDTrHtchTrAx "Serial Data 198 Protected : Short Range Radar Side Left Rear Object Detection and Processing Trailer Object Variance Distance Trailer Hitch To Trailer Axle";
BA_ "SignalLongName" SG_ 22 SRRSLRODPTOVDVhFrtAxVhHtch "Serial Data 198 Protected : Short Range Radar Side Left Rear Object Detection and Processing Trailer Object Variance Distance Vehicle Front Axle To Vehicle Hitch";
BA_ "SignalLongName" SG_ 22 SRRSLRODPTOVDTrHtchTrFrt "Serial Data 198 Protected : Short Range Radar Side Left Rear Object Detection and Processing Trailer Object Variance Distance Trailer Hitch To Trailer Front";
BA_ "SignalLongName" SG_ 22 SRRSLRODPTrObjWdth "Serial Data 198 Protected : Short Range Radar Side Left Rear Object Detection and Processing Trailer Object Width";
BA_ "SignalType" SG_ 22 SRRSLRODPTrObjStatInfo "ENM";
BA_ "SignalLongName" SG_ 22 SRRSLRODPTrObjStatInfo "Serial Data 198 Protected : Short Range Radar Side Left Rear Object Detection and Processing Trailer Object State Information";
BA_ "SignalLongName" SG_ 22 SRRSLRODPTrObjExtrnInfo "Serial Data 198 Protected : Short Range Radar Side Left Rear Object Detection and Processing Trailer Object External Information";
BA_ "SignalType" SG_ 22 SRRSLRODPTOPDtnPrblty_Inv "ENM";
BA_ "SignalLongName" SG_ 22 SRRSLRODPTOPDtnPrblty_Inv "Serial Data 198 Protected : Short Range Radar Side Left Rear Object Detection and Processing Trailer Object Presence Detection Probability Invalid";
BA_ "SignalType" SG_ 22 SRRSLRODPTOEExistPrblty_Inv "ENM";
BA_ "SignalLongName" SG_ 22 SRRSLRODPTOEExistPrblty_Inv "Serial Data 198 Protected : Short Range Radar Side Left Rear Object Detection and Processing Trailer Object Edge Existence Probability Invalid";
BA_ "SignalType" SG_ 22 SRRSLRODPTODVhFrtAxVhHtch_Inv "ENM";
BA_ "SignalLongName" SG_ 22 SRRSLRODPTODVhFrtAxVhHtch_Inv "Serial Data 198 Protected : Short Range Radar Side Left Rear Object Detection and Processing Trailer Object Distance Vehicle Front Axle To Vehicle Hitch Invalid";
BA_ "SignalType" SG_ 22 SRRSLRODPTODTrHtchTrFrt_Inv "ENM";
BA_ "SignalLongName" SG_ 22 SRRSLRODPTODTrHtchTrFrt_Inv "Serial Data 198 Protected : Short Range Radar Side Left Rear Object Detection and Processing Trailer Object Distance Trailer Hitch To Trailer Front Invalid";
BA_ "SignalType" SG_ 22 SRRSLRODPTODTrHtchTrAx_Inv "ENM";
BA_ "SignalLongName" SG_ 22 SRRSLRODPTODTrHtchTrAx_Inv "Serial Data 198 Protected : Short Range Radar Side Left Rear Object Detection and Processing Trailer Object Distance Trailer Hitch To Trailer Axle Invalid";
BA_ "SignalType" SG_ 22 SRRSLRODPTrAtchdInfo "ENM";
BA_ "SignalLongName" SG_ 22 SRRSLRODPTrAtchdInfo "Serial Data 198 Protected : Short Range Radar Side Left Rear Object Detection and Processing Trailer Attached Information";
BA_ "SignalType" SG_ 22 SRRSLRODPTrObjExtrnInfo_Inv "ENM";
BA_ "SignalLongName" SG_ 22 SRRSLRODPTrObjExtrnInfo_Inv "Serial Data 198 Protected : Short Range Radar Side Left Rear Object Detection and Processing Trailer Object External Information Invalid";
BA_ "SignalType" SG_ 22 SRRSLRODPTOVYawRate_Inv "ENM";
BA_ "SignalLongName" SG_ 22 SRRSLRODPTOVYawRate_Inv "Serial Data 198 Protected : Short Range Radar Side Left Rear Object Detection and Processing Trailer Object Variance Yaw Rate Invalid";
BA_ "SignalType" SG_ 22 SRRSLRODPTOVWdth_Inv "ENM";
BA_ "SignalLongName" SG_ 22 SRRSLRODPTOVWdth_Inv "Serial Data 198 Protected : Short Range Radar Side Left Rear Object Detection and Processing Trailer Object Variance Width Invalid";
BA_ "SignalType" SG_ 22 SRRSLRODPTOVOrntn_Inv "ENM";
BA_ "SignalLongName" SG_ 22 SRRSLRODPTOVOrntn_Inv "Serial Data 198 Protected : Short Range Radar Side Left Rear Object Detection and Processing Trailer Object Variance Orientation Invalid";
BA_ "SignalType" SG_ 22 SRRSLRODPTOVLgth_Inv "ENM";
BA_ "SignalLongName" SG_ 22 SRRSLRODPTOVLgth_Inv "Serial Data 198 Protected : Short Range Radar Side Left Rear Object Detection and Processing Trailer Object Variance Length Invalid";
BA_ "SignalType" SG_ 22 SRRSLRODPTOVDVhFrtAxVhHtch_Inv "ENM";
BA_ "SignalLongName" SG_ 22 SRRSLRODPTOVDVhFrtAxVhHtch_Inv "Serial Data 198 Protected : Short Range Radar Side Left Rear Object Detection and Processing Trailer Object Variance Distance Vehicle Front Axle To Vehicle Hitch Invalid";
BA_ "SignalType" SG_ 22 SRRSLRODPTOVDTrHtchTrFrt_Inv "ENM";
BA_ "SignalLongName" SG_ 22 SRRSLRODPTOVDTrHtchTrFrt_Inv "Serial Data 198 Protected : Short Range Radar Side Left Rear Object Detection and Processing Trailer Object Variance Distance Trailer Hitch To Trailer Front Invalid";
BA_ "SignalType" SG_ 22 SRRSLRODPTOVDTrHtchTrAx_Inv "ENM";
BA_ "SignalLongName" SG_ 22 SRRSLRODPTOVDTrHtchTrAx_Inv "Serial Data 198 Protected : Short Range Radar Side Left Rear Object Detection and Processing Trailer Object Variance Distance Trailer Hitch To Trailer Axle Invalid";
BA_ "SignalLongName" SG_ 22 SrlDat198_Filler "Serial Data 198 Protected : Filler";
BA_ "SignalType" SG_ 22 SRRSLRODPTrObjYawRate_Inv "ENM";
BA_ "SignalLongName" SG_ 22 SRRSLRODPTrObjYawRate_Inv "Serial Data 198 Protected : Short Range Radar Side Left Rear Object Detection and Processing Trailer Object Yaw Rate Invalid";
BA_ "SignalType" SG_ 22 SRRSLRODPTrObjWdth_Inv "ENM";
BA_ "SignalLongName" SG_ 22 SRRSLRODPTrObjWdth_Inv "Serial Data 198 Protected : Short Range Radar Side Left Rear Object Detection and Processing Trailer Object Width Invalid";
BA_ "SignalType" SG_ 22 SRRSLRODPTrObjQlty_Inv "ENM";
BA_ "SignalLongName" SG_ 22 SRRSLRODPTrObjQlty_Inv "Serial Data 198 Protected : Short Range Radar Side Left Rear Object Detection and Processing Trailer Object Quality Invalid";
BA_ "SignalType" SG_ 22 SRRSLRODPTrObjOrntn_Inv "ENM";
BA_ "SignalLongName" SG_ 22 SRRSLRODPTrObjOrntn_Inv "Serial Data 198 Protected : Short Range Radar Side Left Rear Object Detection and Processing Trailer Object Orientation Invalid";
BA_ "SignalType" SG_ 22 SRRSLRODPTrObjLgth_Inv "ENM";
BA_ "SignalLongName" SG_ 22 SRRSLRODPTrObjLgth_Inv "Serial Data 198 Protected : Short Range Radar Side Left Rear Object Detection and Processing Trailer Object Length Invalid";
BA_ "SignalLongName" SG_ 22 SrlDat198_FillerExtnd "Serial Data 198 Protected : Filler Extended";
BA_ "SignalLongName" SG_ 22 SD198P_ARC "Serial Data 198 Protected : Alive Rolling Count";
BA_ "SignalLongName" SG_ 542 SrlDat199_PCSM "Serial Data 199 Protected Counter Sync Message";
VAL_ 191 SRRSRRODPB4P_POTk5DynPrpAuth 0 "Has Never Moved" 1 "Has Moved But Currently Stopped" 2 "Moving In Same Direction As Host" 3 "Moving In Opposite Direction As Host" 4 "Crossing Path" ;
VAL_ 191 SRRSRRODPB4P_POTk5CnfdStsAuth 0 "Highly Speculative" 1 "Speculative" 2 "Confident" 3 "Highly Confident" ;
VAL_ 191 SRRSRRODPB4P_POTk5MStsAuth 0 "No Object" 1 "New Object" 2 "Latent Track Not Detected this Cycle" 3 "Measured this Cycle" ;
VAL_ 191 SRRSRRODPB4P_POTk5TypCnfdAuth 0 "Highly Speculative" 1 "Speculative" 2 "Confident" 3 "Highly Confident" ;
VAL_ 191 SRRSRRODPB4P_POTk5TypAuth 0 "Unknown" 1 "Pedestrian" 2 "Bicycle" ;
VAL_ 191 SRRSRRODPB4P_VOTk10DynPrpStAuth 0 "Stopped" 1 "Not Stopped" ;
VAL_ 191 SRRSRRODPB4P_VOTk10DynPrpAuth 0 "Has Never Moved" 1 "Moving In Same Direction As Host" 2 "Moving In Opposite Direction As Host" 3 "Crossing From Left To Right" 4 "Crossing From Right To Left" ;
VAL_ 191 SRRSRRODPB4P_VOTk10CnfdStsAuth 0 "Highly Speculative" 1 "Speculative" 2 "Confident" 3 "Highly Confident" ;
VAL_ 191 SRRSRRODPB4P_VOTk10MStsAuth 0 "No Object" 1 "New Object" 2 "Latent Track Not Detected this Cycle" 3 "Measured this Cycle" ;
VAL_ 191 SRRSRRODPB4P_VOTk10TypCnfdAuth 0 "Highly Speculative" 1 "Speculative" 2 "Confident" 3 "Highly Confident" ;
VAL_ 191 SRRSRRODPB4P_VOTk8CnfdStsAuth 0 "Highly Speculative" 1 "Speculative" 2 "Confident" 3 "Highly Confident" ;
VAL_ 191 SRRSRRODPB4P_VOTk8DynPrpStsAuth 0 "Stopped" 1 "Not Stopped" ;
VAL_ 191 SRRSRRODPB4P_VOTk8DynPrpAuth 0 "Has Never Moved" 1 "Moving In Same Direction As Host" 2 "Moving In Opposite Direction As Host" 3 "Crossing From Left To Right" 4 "Crossing From Right To Left" ;
VAL_ 191 SRRSRRODPB4P_VOTk8MStsAuth 0 "No Object" 1 "New Object" 2 "Latent Track Not Detected this Cycle" 3 "Measured this Cycle" ;
VAL_ 191 SRRSRRODPB4P_VOTk8TypCnfdAuth 0 "Highly Speculative" 1 "Speculative" 2 "Confident" 3 "Highly Confident" ;
VAL_ 191 SRRSRRODPB4P_VOTk9DynPrpStsAuth 0 "Stopped" 1 "Not Stopped" ;
VAL_ 191 SRRSRRODPB4P_VOTk9DynPrpAuth 0 "Has Never Moved" 1 "Moving In Same Direction As Host" 2 "Moving In Opposite Direction As Host" 3 "Crossing From Left To Right" 4 "Crossing From Right To Left" ;
VAL_ 191 SRRSRRODPB4P_VOTk9CnfdStsAuth 0 "Highly Speculative" 1 "Speculative" 2 "Confident" 3 "Highly Confident" ;
VAL_ 191 SRRSRRODPB4P_VOTk9MStsAuth 0 "No Object" 1 "New Object" 2 "Latent Track Not Detected this Cycle" 3 "Measured this Cycle" ;
VAL_ 191 SRRSRRODPB4P_VOTk9TypCnfdAuth 0 "Highly Speculative" 1 "Speculative" 2 "Confident" 3 "Highly Confident" ;
VAL_ 190 SRRSRRODPB5P_IOTk10ElvtnAuth 0 "Not Elevated Elevation" 1 "Speculative Elevation" 2 "Confident Elevation" 3 "Very Confident" ;
VAL_ 190 SRRSRRODPB5P_IOTk10CnfdStsAuth 0 "Highly Speculative" 1 "Speculative" 2 "Confident" 3 "Highly Confident" ;
VAL_ 190 SRRSRRODPB5P_IOTk10MStsAuth 0 "No Object" 1 "New Object" 2 "Latent Track Not Detected this Cycle" 3 "Measured this Cycle" ;
VAL_ 190 SRRSRRODPB5P_IOTk1CnfdStsAuth 0 "Highly Speculative" 1 "Speculative" 2 "Confident" 3 "Highly Confident" ;
VAL_ 190 SRRSRRODPB5P_IOTk10TypCnfdAuth 0 "Highly Speculative" 1 "Speculative" 2 "Confident" 3 "Highly Confident" ;
VAL_ 190 SRRSRRODPB5P_IOTk10TypAuth 0 "Unknown" 1 "Guard Rail" 2 "Tunnel" 3 "Traffic Sign" 4 "Bridge" 5 "Pole" ;
VAL_ 190 SRRSRRODPB5P_IOTk1ElvtnAuth 0 "Not Elevated Elevation" 1 "Speculative Elevation" 2 "Confident Elevation" 3 "Very Confident" ;
VAL_ 190 SRRSRRODPB5P_IOTk1MStsAuth 0 "No Object" 1 "New Object" 2 "Latent Track Not Detected this Cycle" 3 "Measured this Cycle" ;
VAL_ 190 SRRSRRODPB5P_IOTk1TypAuth 0 "Unknown" 1 "Guard Rail" 2 "Tunnel" 3 "Traffic Sign" 4 "Bridge" 5 "Pole" ;
VAL_ 190 SRRSRRODPB5P_IOTk2ElvtnAuth 0 "Not Elevated Elevation" 1 "Speculative Elevation" 2 "Confident Elevation" 3 "Very Confident" ;
VAL_ 190 SRRSRRODPB5P_IOTk2CnfdStsAuth 0 "Highly Speculative" 1 "Speculative" 2 "Confident" 3 "Highly Confident" ;
VAL_ 190 SRRSRRODPB5P_IOTk1TypCnfdAuth 0 "Highly Speculative" 1 "Speculative" 2 "Confident" 3 "Highly Confident" ;
VAL_ 190 SRRSRRODPB5P_IOTk2MStsAuth 0 "No Object" 1 "New Object" 2 "Latent Track Not Detected this Cycle" 3 "Measured this Cycle" ;
VAL_ 190 SRRSRRODPB5P_IOTk2TypCnfdAuth 0 "Highly Speculative" 1 "Speculative" 2 "Confident" 3 "Highly Confident" ;
VAL_ 190 SRRSRRODPB5P_IOTk2TypAuth 0 "Unknown" 1 "Guard Rail" 2 "Tunnel" 3 "Traffic Sign" 4 "Bridge" 5 "Pole" ;
VAL_ 190 SRRSRRODPB5P_IOTk3ElvtnAuth 0 "Not Elevated Elevation" 1 "Speculative Elevation" 2 "Confident Elevation" 3 "Very Confident" ;
VAL_ 190 SRRSRRODPB5P_IOTk3CnfdStsAuth 0 "Highly Speculative" 1 "Speculative" 2 "Confident" 3 "Highly Confident" ;
VAL_ 190 SRRSRRODPB5P_IOTk3MStsAuth 0 "No Object" 1 "New Object" 2 "Latent Track Not Detected this Cycle" 3 "Measured this Cycle" ;
VAL_ 190 SRRSRRODPB5P_IOTk4CnfdStsAuth 0 "Highly Speculative" 1 "Speculative" 2 "Confident" 3 "Highly Confident" ;
VAL_ 190 SRRSRRODPB5P_IOTk3TypCnfdAuth 0 "Highly Speculative" 1 "Speculative" 2 "Confident" 3 "Highly Confident" ;
VAL_ 190 SRRSRRODPB5P_IOTk3TypAuth 0 "Unknown" 1 "Guard Rail" 2 "Tunnel" 3 "Traffic Sign" 4 "Bridge" 5 "Pole" ;
VAL_ 190 SRRSRRODPB5P_IOTk4ElvtnAuth 0 "Not Elevated Elevation" 1 "Speculative Elevation" 2 "Confident Elevation" 3 "Very Confident" ;
VAL_ 190 SRRSRRODPB5P_IOTk4MStsAuth 0 "No Object" 1 "New Object" 2 "Latent Track Not Detected this Cycle" 3 "Measured this Cycle" ;
VAL_ 190 SRRSRRODPB5P_IOTk4TypAuth 0 "Unknown" 1 "Guard Rail" 2 "Tunnel" 3 "Traffic Sign" 4 "Bridge" 5 "Pole" ;
VAL_ 190 SRRSRRODPB5P_IOTk5ElvtnAuth 0 "Not Elevated Elevation" 1 "Speculative Elevation" 2 "Confident Elevation" 3 "Very Confident" ;
VAL_ 190 SRRSRRODPB5P_IOTk5CnfdStsAuth 0 "Highly Speculative" 1 "Speculative" 2 "Confident" 3 "Highly Confident" ;
VAL_ 190 SRRSRRODPB5P_IOTk4TypCnfdAuth 0 "Highly Speculative" 1 "Speculative" 2 "Confident" 3 "Highly Confident" ;
VAL_ 190 SRRSRRODPB5P_IOTk5MStsAuth 0 "No Object" 1 "New Object" 2 "Latent Track Not Detected this Cycle" 3 "Measured this Cycle" ;
VAL_ 190 SRRSRRODPB5P_IOTk5TypCnfdAuth 0 "Highly Speculative" 1 "Speculative" 2 "Confident" 3 "Highly Confident" ;
VAL_ 190 SRRSRRODPB5P_IOTk5TypAuth 0 "Unknown" 1 "Guard Rail" 2 "Tunnel" 3 "Traffic Sign" 4 "Bridge" 5 "Pole" ;
VAL_ 190 SRRSRRODPB5P_IOTk6ElvtnAuth 0 "Not Elevated Elevation" 1 "Speculative Elevation" 2 "Confident Elevation" 3 "Very Confident" ;
VAL_ 190 SRRSRRODPB5P_IOTk6CnfdStsAuth 0 "Highly Speculative" 1 "Speculative" 2 "Confident" 3 "Highly Confident" ;
VAL_ 190 SRRSRRODPB5P_IOTk6MStsAuth 0 "No Object" 1 "New Object" 2 "Latent Track Not Detected this Cycle" 3 "Measured this Cycle" ;
VAL_ 190 SRRSRRODPB5P_IOTk7ElvtnAuth 0 "Not Elevated Elevation" 1 "Speculative Elevation" 2 "Confident Elevation" 3 "Very Confident" ;
VAL_ 190 SRRSRRODPB5P_IOTk7CnfdStsAuth 0 "Highly Speculative" 1 "Speculative" 2 "Confident" 3 "Highly Confident" ;
VAL_ 190 SRRSRRODPB5P_IOTk6TypCnfdAuth 0 "Highly Speculative" 1 "Speculative" 2 "Confident" 3 "Highly Confident" ;
VAL_ 190 SRRSRRODPB5P_IOTk6TypAuth 0 "Unknown" 1 "Guard Rail" 2 "Tunnel" 3 "Traffic Sign" 4 "Bridge" 5 "Pole" ;
VAL_ 190 SRRSRRODPB5P_IOTk7MStsAuth 0 "No Object" 1 "New Object" 2 "Latent Track Not Detected this Cycle" 3 "Measured this Cycle" ;
VAL_ 190 SRRSRRODPB5P_IOTk7TypAuth 0 "Unknown" 1 "Guard Rail" 2 "Tunnel" 3 "Traffic Sign" 4 "Bridge" 5 "Pole" ;
VAL_ 190 SRRSRRODPB5P_IOTk8ElvtnAuth 0 "Not Elevated Elevation" 1 "Speculative Elevation" 2 "Confident Elevation" 3 "Very Confident" ;
VAL_ 190 SRRSRRODPB5P_IOTk8CnfdStsAuth 0 "Highly Speculative" 1 "Speculative" 2 "Confident" 3 "Highly Confident" ;
VAL_ 190 SRRSRRODPB5P_IOTk7TypCnfdAuth 0 "Highly Speculative" 1 "Speculative" 2 "Confident" 3 "Highly Confident" ;
VAL_ 190 SRRSRRODPB5P_IOTk8MStsAuth 0 "No Object" 1 "New Object" 2 "Latent Track Not Detected this Cycle" 3 "Measured this Cycle" ;
VAL_ 190 SRRSRRODPB5P_IOTk9CnfdStsAuth 0 "Highly Speculative" 1 "Speculative" 2 "Confident" 3 "Highly Confident" ;
VAL_ 190 SRRSRRODPB5P_IOTk8TypCnfdAuth 0 "Highly Speculative" 1 "Speculative" 2 "Confident" 3 "Highly Confident" ;
VAL_ 190 SRRSRRODPB5P_IOTk8TypAuth 0 "Unknown" 1 "Guard Rail" 2 "Tunnel" 3 "Traffic Sign" 4 "Bridge" 5 "Pole" ;
VAL_ 190 SRRSRRODPB5P_IOTk9ElvtnAuth 0 "Not Elevated Elevation" 1 "Speculative Elevation" 2 "Confident Elevation" 3 "Very Confident" ;
VAL_ 190 SRRSRRODPB5P_IOTk9MStsAuth 0 "No Object" 1 "New Object" 2 "Latent Track Not Detected this Cycle" 3 "Measured this Cycle" ;
VAL_ 190 SRRSRRODPB5P_IOTk9TypAuth 0 "Unknown" 1 "Guard Rail" 2 "Tunnel" 3 "Traffic Sign" 4 "Bridge" 5 "Pole" ;
VAL_ 190 SRRSRRODPB5P_IOTk9TypCnfdAuth 0 "Highly Speculative" 1 "Speculative" 2 "Confident" 3 "Highly Confident" ;
VAL_ 193 SRRSRRODPB1P_CnstrArDtnCnfdAuth 0 "Highly Speculative" 1 "Speculative" 2 "Confident" 3 "Highly Confident" ;
VAL_ 193 SRRSRRODPB1P_AcqTmStmAuth_Inv 0 "FALSE" 1 "TRUE" ;
VAL_ 193 SRRSRRODPB1P_POTk1DynPrpAuth 0 "Has Never Moved" 1 "Has Moved But Currently Stopped" 2 "Moving In Same Direction As Host" 3 "Moving In Opposite Direction As Host" 4 "Crossing Path" ;
VAL_ 193 SRRSRRODPB1P_POTk1CnfdStsAuth 0 "Highly Speculative" 1 "Speculative" 2 "Confident" 3 "Highly Confident" ;
VAL_ 193 SRRSRRODPB1P_MdCmdStsAuth 0 "Not Radiating" 1 "Reporting Object Data" 2 "Not Reporting Object Data" ;
VAL_ 193 SRRSRRODPB1P_CnstrArDtnStsAuth 0 "Not Detected" 1 "Detected" 2 "Unknown" ;
VAL_ 193 SRRSRRODPB1P_POTk1MStsAuth 0 "No Object" 1 "New Object" 2 "Latent Track Not Detected this Cycle" 3 "Measured this Cycle" ;
VAL_ 193 SRRSRRODPB1P_POTk2CnfdStsAuth 0 "Highly Speculative" 1 "Speculative" 2 "Confident" 3 "Highly Confident" ;
VAL_ 193 SRRSRRODPB1P_POTk1TypCnfdAuth 0 "Highly Speculative" 1 "Speculative" 2 "Confident" 3 "Highly Confident" ;
VAL_ 193 SRRSRRODPB1P_POTk1TypAuth 0 "Unknown" 1 "Pedestrian" 2 "Bicycle" ;
VAL_ 193 SRRSRRODPB1P_POTk2DynPrpAuth 0 "Has Never Moved" 1 "Has Moved But Currently Stopped" 2 "Moving In Same Direction As Host" 3 "Moving In Opposite Direction As Host" 4 "Crossing Path" ;
VAL_ 193 SRRSRRODPB1P_POTk2MStsAuth 0 "No Object" 1 "New Object" 2 "Latent Track Not Detected this Cycle" 3 "Measured this Cycle" ;
VAL_ 193 SRRSRRODPB1P_POTk2TypCnfdAuth 0 "Highly Speculative" 1 "Speculative" 2 "Confident" 3 "Highly Confident" ;
VAL_ 193 SRRSRRODPB1P_POTk2TypAuth 0 "Unknown" 1 "Pedestrian" 2 "Bicycle" ;
VAL_ 193 SRRSRRODPB1P_SnsrUnvAuth 0 "FALSE" 1 "TRUE" ;
VAL_ 193 SRRSRRODPB1P_SnsrBlckdAuth 0 "FALSE" 1 "TRUE" ;
VAL_ 193 SRRSRRODPB1P_ServRqrdAuth 0 "FALSE" 1 "TRUE" ;
VAL_ 193 SRRSRRODPB1P_RdTypCnfdAuth 0 "Highly Speculative" 1 "Speculative" 2 "Confident" 3 "Highly Confident" ;
VAL_ 193 SRRSRRODPB1P_RdTypAuth 0 "Unknown" 1 "City" 2 "Secondary Road" 3 "Highway" 4 "Construction" 5 "Zone Entry" 6 "Construction" 7 "Zone Exit" ;
VAL_ 193 SRRSRRODPB1P_SwpBndwdthStsAuth 0 "Mode A" 1 "Mode B" 2 "Mode C" 3 "Mode D" ;
VAL_ 193 SRRSRRODPB1P_VOTk1DynPrpStsAuth 0 "Stopped" 1 "Not Stopped" ;
VAL_ 193 SRRSRRODPB1P_VOTk1DynPrpAuth 0 "Has Never Moved" 1 "Moving In Same Direction As Host" 2 "Moving In Opposite Direction As Host" 3 "Crossing From Left To Right" 4 "Crossing From Right To Left" ;
VAL_ 193 SRRSRRODPB1P_VOTk1CnfdStsAuth 0 "Highly Speculative" 1 "Speculative" 2 "Confident" 3 "Highly Confident" ;
VAL_ 193 SRRSRRODPB1P_VOTk1MStsAuth 0 "No Object" 1 "New Object" 2 "Latent Track Not Detected this Cycle" 3 "Measured this Cycle" ;
VAL_ 193 SRRSRRODPB1P_VOTk1TypCnfdAuth 0 "Highly Speculative" 1 "Speculative" 2 "Confident" 3 "Highly Confident" ;
VAL_ 522 SRRSRRODPB6P_REOTk1CnfdStsAuth 0 "Highly Speculative" 1 "Speculative" 2 "Confident" 3 "Highly Confident" ;
VAL_ 522 SRRSRRODPB6P_REOTk2CnfdStsAuth 0 "Highly Speculative" 1 "Speculative" 2 "Confident" 3 "Highly Confident" ;
VAL_ 522 SRRSRRODPB6P_REOTk1TypCnfdAuth 0 "Highly Speculative" 1 "Speculative" 2 "Confident" 3 "Highly Confident" ;
VAL_ 522 SRRSRRODPB6P_REOTk1TypAuth 0 "Unknown" 1 "Barriers" 2 "Guard Rails" 3 "Bridge Abutments" 4 "Edge of Road" 5 "Open Area" ;
VAL_ 522 SRRSRRODPB6P_REOTk3CnfdStsAuth 0 "Highly Speculative" 1 "Speculative" 2 "Confident" 3 "Highly Confident" ;
VAL_ 522 SRRSRRODPB6P_REOTk2TypCnfdAuth 0 "Highly Speculative" 1 "Speculative" 2 "Confident" 3 "Highly Confident" ;
VAL_ 522 SRRSRRODPB6P_REOTk2TypAuth 0 "Unknown" 1 "Barriers" 2 "Guard Rails" 3 "Bridge Abutments" 4 "Edge of Road" 5 "Open Area" ;
VAL_ 522 SRRSRRODPB6P_REOTk3TypCnfdAuth 0 "Highly Speculative" 1 "Speculative" 2 "Confident" 3 "Highly Confident" ;
VAL_ 522 SRRSRRODPB6P_REOTk3TypAuth 0 "Unknown" 1 "Barriers" 2 "Guard Rails" 3 "Bridge Abutments" 4 "Edge of Road" 5 "Open Area" ;
VAL_ 2147745812 SRR_LF_CAN8_ClscCANHrtBtActv 0 "FALSE" 1 "TRUE" ;
VAL_ 2147745813 SRR_LR_CR_CAN8_ClscCANHrtBtActv 0 "FALSE" 1 "TRUE" ;
VAL_ 2147745814 SRR_RF_CAN8_ClscCANHrtBtActv 0 "FALSE" 1 "TRUE" ;
VAL_ 2147745815 SRR_RR_CAN8_ClscCANHrtBtActv 0 "FALSE" 1 "TRUE" ;
VAL_ 2147745816 SRR_SLR_CAN8_ClscCANHrtBtActv 0 "FALSE" 1 "TRUE" ;
VAL_ 2147745817 SRR_SRR_CAN8_ClscCANHrtBtActv 0 "FALSE" 1 "TRUE" ;
VAL_ 1317 SLVFSP_SpdLimVsnFsdSpdUntAuth 0 "km/h" 1 "mph" ;
VAL_ 1317 SLVFSP_SpdLimVsnFsdSpdNwDtdAuth 0 "FALSE" 1 "TRUE" ;
VAL_ 1317 SLVFSP_SpdLimVsnFsdSpdAuth_DuD 0 "FALSE" 1 "TRUE" ;
VAL_ 1309 SGI2P_AirSpnsnRdHghtLwrActnAuth 0 "None" 1 "Slow" 2 "Medium (Exhaust)" 3 "Fast" ;
VAL_ 1309 SGI2P_AirSpnsnRdHghtActvAxlAuth 0 "None" 1 "Front" 2 "Rear" 3 "Both" 4 "Pending" ;
VAL_ 1309 SGI2P_AirSpnsnRdHghtActlStsAuth 0 "Faulted" 1 "Entry/Exit" 2 "Lowered 3" 3 "Lowered 2" 4 "Lowered 1" 5 "Showroom" 6 "Normal" 7 "Raised 1" 8 "Raised 2" 9 "Raised 3" 10 "Cargo" 11 "Trailer Low" 12 "Trailer High" 13 "Car Show" ;
VAL_ 1309 SGI2P_AirSpnsnRdHghtTgtStsAuth 0 "Faulted" 1 "Entry/Exit" 2 "Lowered 3" 3 "Lowered 2" 4 "Lowered 1" 5 "Showroom" 6 "Normal" 7 "Raised 1" 8 "Raised 2" 9 "Raised 3" 10 "Cargo" 11 "Trailer Low" 12 "Trailer High" 13 "Car Show" ;
VAL_ 1309 SGI2P_AirSpnsnRdHghtRseActnAuth 0 "None" 1 "Slow(i.e. compressor)" 2 "Medium (i.e. Boost)" 3 "Fast (i.e. Reservoir)" ;
VAL_ 179 FsdLoclzdRdTyp 0 "Unknown" 1 "Limited Access Road" 2 "Not Limited Access Road" ;
VAL_ 180 UODPFrtEchoAcqTmStm_Inv 0 "FALSE" 1 "TRUE" ;
VAL_ 180 UODPFrtSnsr1EchoSnsrMode 0 "Unknown" 1 "Transmit Receive" 2 "Receive" ;
VAL_ 180 UODPFrtSnsr1EchoSnsrDatUsg 0 "Don't Use Data" 1 "Use Data" ;
VAL_ 180 UODPFrtSnsr2EchoSnsrMode 0 "Unknown" 1 "Transmit Receive" 2 "Receive" ;
VAL_ 180 UODPFrtSnsr2EchoSnsrDatUsg 0 "Don't Use Data" 1 "Use Data" ;
VAL_ 180 UODPFrtSnsr3EchoSnsrMode 0 "Unknown" 1 "Transmit Receive" 2 "Receive" ;
VAL_ 180 UODPFrtSnsr3EchoSnsrDatUsg 0 "Don't Use Data" 1 "Use Data" ;
VAL_ 180 UODPFrtSnsr4EchoSnsrMode 0 "Unknown" 1 "Transmit Receive" 2 "Receive" ;
VAL_ 180 UODPFrtSnsr4EchoSnsrDatUsg 0 "Don't Use Data" 1 "Use Data" ;
VAL_ 180 UODPFrtSnsr5EchoSnsrMode 0 "Unknown" 1 "Transmit Receive" 2 "Receive" ;
VAL_ 180 UODPFrtSnsr5EchoSnsrDatUsg 0 "Don't Use Data" 1 "Use Data" ;
VAL_ 180 UODPFrtModSts 0 "Unknown" 1 "Internal Failure" 2 "External Failure" 3 "Environmental Disablement" 4 "Unavailable" 5 "Functioning" ;
VAL_ 180 UODPSnsAutoPrkAval 0 "FALSE" 1 "TRUE" ;
VAL_ 180 UODPFrtSnsr6EchoSnsrMode 0 "Unknown" 1 "Transmit Receive" 2 "Receive" ;
VAL_ 180 UODPFrtSnsr6EchoSnsrDatUsg 0 "Don't Use Data" 1 "Use Data" ;
VAL_ 532 UODPRrEchoAcqTmStm_Inv 0 "FALSE" 1 "TRUE" ;
VAL_ 532 UODPRrSnsr1EchoSnsrMode 0 "Unknown" 1 "Transmit Receive" 2 "Receive" ;
VAL_ 532 UODPRrSnsr1EchoSnsrDatUsg 0 "Don't Use Data" 1 "Use Data" ;
VAL_ 532 UODPRrSnsr2EchoSnsrMode 0 "Unknown" 1 "Transmit Receive" 2 "Receive" ;
VAL_ 532 UODPRrSnsr2EchoSnsrDatUsg 0 "Don't Use Data" 1 "Use Data" ;
VAL_ 532 UODPRrSnsr3EchoSnsrMode 0 "Unknown" 1 "Transmit Receive" 2 "Receive" ;
VAL_ 532 UODPRrSnsr3EchoSnsrDatUsg 0 "Don't Use Data" 1 "Use Data" ;
VAL_ 532 UODPRrSnsr4EchoSnsrMode 0 "Unknown" 1 "Transmit Receive" 2 "Receive" ;
VAL_ 532 UODPRrSnsr4EchoSnsrDatUsg 0 "Don't Use Data" 1 "Use Data" ;
VAL_ 532 UODPRrSnsr5EchoSnsrMode 0 "Unknown" 1 "Transmit Receive" 2 "Receive" ;
VAL_ 532 UODPRrSnsr5EchoSnsrDatUsg 0 "Don't Use Data" 1 "Use Data" ;
VAL_ 532 UODPRrModSts 0 "Unknown" 1 "Internal Failure" 2 "External Failure" 3 "Environmental Disablement" 4 "Unavailable" 5 "Functioning" ;
VAL_ 532 UODPRrSnsr6EchoSnsrMode 0 "Unknown" 1 "Transmit Receive" 2 "Receive" ;
VAL_ 532 UODPRrSnsr6EchoSnsrDatUsg 0 "Don't Use Data" 1 "Use Data" ;
VAL_ 594 UODPLoclzdObj10Hght 0 "Unknown" 1 "Traversable" 2 "High Object" 3 "Low Object" ;
VAL_ 594 UODPLoclzdObj1Hght 0 "Unknown" 1 "Traversable" 2 "High Object" 3 "Low Object" ;
VAL_ 594 UODPLoclzdObj2Hght 0 "Unknown" 1 "Traversable" 2 "High Object" 3 "Low Object" ;
VAL_ 594 UODPLoclzdObj3Hght 0 "Unknown" 1 "Traversable" 2 "High Object" 3 "Low Object" ;
VAL_ 594 UODPLoclzdObj4Hght 0 "Unknown" 1 "Traversable" 2 "High Object" 3 "Low Object" ;
VAL_ 594 UODPLoclzdObj5Hght 0 "Unknown" 1 "Traversable" 2 "High Object" 3 "Low Object" ;
VAL_ 594 UODPLoclzdObj6Hght 0 "Unknown" 1 "Traversable" 2 "High Object" 3 "Low Object" ;
VAL_ 594 UODPLoclzdObj7Hght 0 "Unknown" 1 "Traversable" 2 "High Object" 3 "Low Object" ;
VAL_ 594 UODPLoclzdObj8Hght 0 "Unknown" 1 "Traversable" 2 "High Object" 3 "Low Object" ;
VAL_ 594 UODPLoclzdObj9Hght 0 "Unknown" 1 "Traversable" 2 "High Object" 3 "Low Object" ;
VAL_ 593 UODPLoclzdObj10Typ 0 "No Object" 1 "Straight 0 Corner" 2 "Straight 1 Corner" 3 "Straight 2 Corners" 4 "Point" 5 "Curbstone" ;
VAL_ 593 UODPLoclzdObj1Typ 0 "No Object" 1 "Straight 0 Corner" 2 "Straight 1 Corner" 3 "Straight 2 Corners" 4 "Point" 5 "Curbstone" ;
VAL_ 593 UODPLoclzdObj2Typ 0 "No Object" 1 "Straight 0 Corner" 2 "Straight 1 Corner" 3 "Straight 2 Corners" 4 "Point" 5 "Curbstone" ;
VAL_ 593 UODPLoclzdObj3Typ 0 "No Object" 1 "Straight 0 Corner" 2 "Straight 1 Corner" 3 "Straight 2 Corners" 4 "Point" 5 "Curbstone" ;
VAL_ 593 UODPLoclzdObj4Typ 0 "No Object" 1 "Straight 0 Corner" 2 "Straight 1 Corner" 3 "Straight 2 Corners" 4 "Point" 5 "Curbstone" ;
VAL_ 593 UODPLoclzdObj5Typ 0 "No Object" 1 "Straight 0 Corner" 2 "Straight 1 Corner" 3 "Straight 2 Corners" 4 "Point" 5 "Curbstone" ;
VAL_ 593 UODPLoclzdObj6Typ 0 "No Object" 1 "Straight 0 Corner" 2 "Straight 1 Corner" 3 "Straight 2 Corners" 4 "Point" 5 "Curbstone" ;
VAL_ 593 UODPLoclzdObj7Typ 0 "No Object" 1 "Straight 0 Corner" 2 "Straight 1 Corner" 3 "Straight 2 Corners" 4 "Point" 5 "Curbstone" ;
VAL_ 593 UODPLoclzdObj8Typ 0 "No Object" 1 "Straight 0 Corner" 2 "Straight 1 Corner" 3 "Straight 2 Corners" 4 "Point" 5 "Curbstone" ;
VAL_ 593 UODPLoclzdObj9Typ 0 "No Object" 1 "Straight 0 Corner" 2 "Straight 1 Corner" 3 "Straight 2 Corners" 4 "Point" 5 "Curbstone" ;
VAL_ 33 SuprRmtPrkFirngModeReq 0 "Unknown" 1 "Mode 1" 2 "Mode 2" 3 "Mode 3" 4 "Mode 4" 5 "Custom Mode" ;
VAL_ 33 AutoPrkUltrsncObjSnsActvnReqd 0 "FALSE" 1 "TRUE" ;
VAL_ 23 SRRLRCRODPTrObjStatInfo 0 "Off" 1 "Passive" 2 "Active" 3 "Restricted" 4 "Invalid" ;
VAL_ 23 SRRLRCRODPTOPDtnPrblty_Inv 0 "FALSE" 1 "TRUE" ;
VAL_ 23 SRRLRCRODPTOEExistPrblty_Inv 0 "FALSE" 1 "TRUE" ;
VAL_ 23 SRRLRCRODPTODVhFrtAxVhHtch_Inv 0 "FALSE" 1 "TRUE" ;
VAL_ 23 SRRLRCRODPTODTrHtchTrFrt_Inv 0 "FALSE" 1 "TRUE" ;
VAL_ 23 SRRLRCRODPTODTrHtchTrAx_Inv 0 "FALSE" 1 "TRUE" ;
VAL_ 23 SRRLRCRODPTrAtchdInfo 0 "Not Attached" 1 "Attached" 2 "Unknown" 3 "Invalid" ;
VAL_ 23 SRRLRCRODPTrObjExtrnInfo_Inv 0 "FALSE" 1 "TRUE" ;
VAL_ 23 SRRLRCRODPTOVYawRate_Inv 0 "FALSE" 1 "TRUE" ;
VAL_ 23 SRRLRCRODPTOVWdth_Inv 0 "FALSE" 1 "TRUE" ;
VAL_ 23 SRRLRCRODPTOVOrntn_Inv 0 "FALSE" 1 "TRUE" ;
VAL_ 23 SRRLRCRODPTOVLgth_Inv 0 "FALSE" 1 "TRUE" ;
VAL_ 23 SRRLRCRODPTOVDVhFrtAxVhHtch_Inv 0 "FALSE" 1 "TRUE" ;
VAL_ 23 SRRLRCRODPTOVDTrHtchTrFrt_Inv 0 "FALSE" 1 "TRUE" ;
VAL_ 23 SRRLRCRODPTOVDTrHtchTrAx_Inv 0 "FALSE" 1 "TRUE" ;
VAL_ 23 SRRLRCRODPTrObjYawRate_Inv 0 "FALSE" 1 "TRUE" ;
VAL_ 23 SRRLRCRODPTrObjWdth_Inv 0 "FALSE" 1 "TRUE" ;
VAL_ 23 SRRLRCRODPTrObjQlty_Inv 0 "FALSE" 1 "TRUE" ;
VAL_ 23 SRRLRCRODPTrObjOrntn_Inv 0 "FALSE" 1 "TRUE" ;
VAL_ 23 SRRLRCRODPTrObjLgth_Inv 0 "FALSE" 1 "TRUE" ;
VAL_ 22 SRRSLRODPTrObjStatInfo 0 "Off" 1 "Passive" 2 "Active" 3 "Restricted" 4 "Invalid" ;
VAL_ 22 SRRSLRODPTOPDtnPrblty_Inv 0 "FALSE" 1 "TRUE" ;
VAL_ 22 SRRSLRODPTOEExistPrblty_Inv 0 "FALSE" 1 "TRUE" ;
VAL_ 22 SRRSLRODPTODVhFrtAxVhHtch_Inv 0 "FALSE" 1 "TRUE" ;
VAL_ 22 SRRSLRODPTODTrHtchTrFrt_Inv 0 "FALSE" 1 "TRUE" ;
VAL_ 22 SRRSLRODPTODTrHtchTrAx_Inv 0 "FALSE" 1 "TRUE" ;
VAL_ 22 SRRSLRODPTrAtchdInfo 0 "Not Attached" 1 "Attached" 2 "Unknown" 3 "Invalid" ;
VAL_ 22 SRRSLRODPTrObjExtrnInfo_Inv 0 "FALSE" 1 "TRUE" ;
VAL_ 22 SRRSLRODPTOVYawRate_Inv 0 "FALSE" 1 "TRUE" ;
VAL_ 22 SRRSLRODPTOVWdth_Inv 0 "FALSE" 1 "TRUE" ;
VAL_ 22 SRRSLRODPTOVOrntn_Inv 0 "FALSE" 1 "TRUE" ;
VAL_ 22 SRRSLRODPTOVLgth_Inv 0 "FALSE" 1 "TRUE" ;
VAL_ 22 SRRSLRODPTOVDVhFrtAxVhHtch_Inv 0 "FALSE" 1 "TRUE" ;
VAL_ 22 SRRSLRODPTOVDTrHtchTrFrt_Inv 0 "FALSE" 1 "TRUE" ;
VAL_ 22 SRRSLRODPTOVDTrHtchTrAx_Inv 0 "FALSE" 1 "TRUE" ;
VAL_ 22 SRRSLRODPTrObjYawRate_Inv 0 "FALSE" 1 "TRUE" ;
VAL_ 22 SRRSLRODPTrObjWdth_Inv 0 "FALSE" 1 "TRUE" ;
VAL_ 22 SRRSLRODPTrObjQlty_Inv 0 "FALSE" 1 "TRUE" ;
VAL_ 22 SRRSLRODPTrObjOrntn_Inv 0 "FALSE" 1 "TRUE" ;
VAL_ 22 SRRSLRODPTrObjLgth_Inv 0 "FALSE" 1 "TRUE" ;
